VERSION ""

NS_ :

BS_:

BU_:

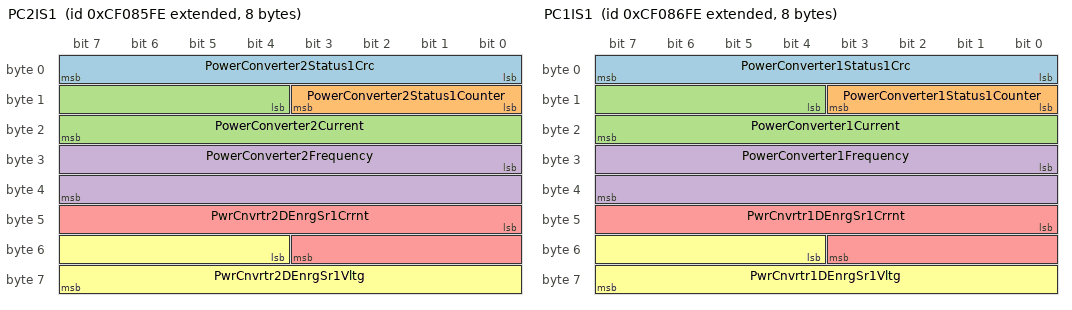
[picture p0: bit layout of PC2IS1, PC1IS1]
BO_ 2364573182 PC2IS1: 8 Vector__XXX
 SG_ PowerConverter2Status1Crc : 0|8@1+ (1,0) [0|250] "count" Vector__XXX
 SG_ PowerConverter2Status1Counter : 8|4@1+ (1,0) [0|15] "" Vector__XXX
 SG_ PowerConverter2Current : 12|12@1+ (0.0625,-125) [-125|125.9375] "%" Vector__XXX
 SG_ PowerConverter2Frequency : 24|16@1+ (0.00390625,-125) [-125|125.99609375] "%" Vector__XXX
 SG_ PwrCnvrtr2DEnrgSr1Crrnt : 40|12@1+ (0.0625,-125) [-125|125.9375] "%" Vector__XXX
 SG_ PwrCnvrtr2DEnrgSr1Vltg : 52|12@1+ (0.0625,-125) [-125|125.9375] "%" Vector__XXX

BO_ 2364573438 PC1IS1: 8 Vector__XXX
 SG_ PowerConverter1Status1Crc : 0|8@1+ (1,0) [0|250] "count" Vector__XXX
 SG_ PowerConverter1Status1Counter : 8|4@1+ (1,0) [0|15] "" Vector__XXX
 SG_ PowerConverter1Current : 12|12@1+ (0.0625,-125) [-125|125.9375] "%" Vector__XXX
 SG_ PowerConverter1Frequency : 24|16@1+ (0.00390625,-125) [-125|125.99609375] "%" Vector__XXX
 SG_ PwrCnvrtr1DEnrgSr1Crrnt : 40|12@1+ (0.0625,-125) [-125|125.9375] "%" Vector__XXX
 SG_ PwrCnvrtr1DEnrgSr1Vltg : 52|12@1+ (0.0625,-125) [-125|125.9375] "%" Vector__XXX

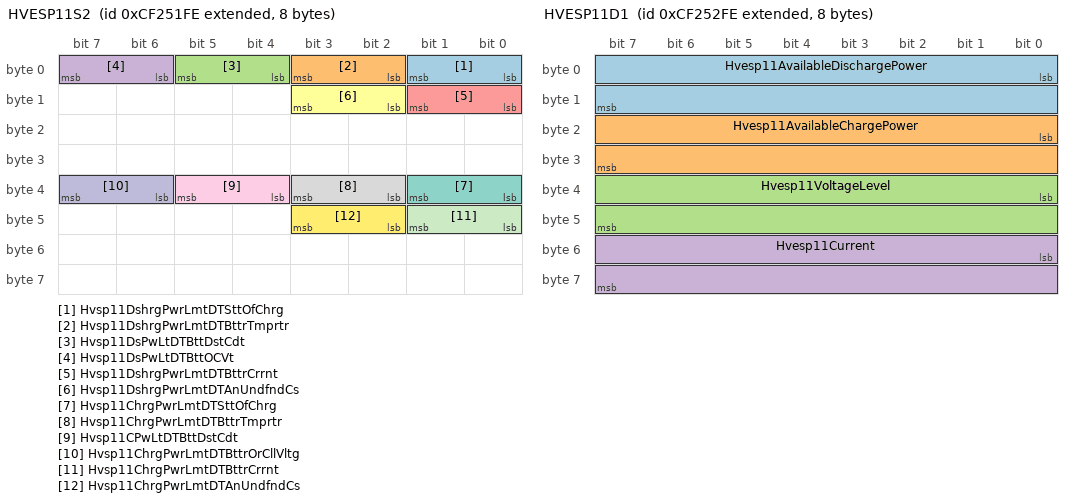
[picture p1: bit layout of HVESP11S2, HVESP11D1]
BO_ 2364690942 HVESP11S2: 8 Vector__XXX
 SG_ Hvsp11DshrgPwrLmtDTSttOfChrg : 0|2@1+ (1,0) [0|3] "" Vector__XXX
 SG_ Hvsp11DshrgPwrLmtDTBttrTmprtr : 2|2@1+ (1,0) [0|3] "" Vector__XXX
 SG_ Hvsp11DsPwLtDTBttDstCdt : 4|2@1+ (1,0) [0|3] "" Vector__XXX
 SG_ Hvsp11DsPwLtDTBttOCVt : 6|2@1+ (1,0) [0|3] "" Vector__XXX
 SG_ Hvsp11DshrgPwrLmtDTBttrCrrnt : 8|2@1+ (1,0) [0|3] "" Vector__XXX
 SG_ Hvsp11DshrgPwrLmtDTAnUndfndCs : 10|2@1+ (1,0) [0|3] "" Vector__XXX
 SG_ Hvsp11ChrgPwrLmtDTSttOfChrg : 32|2@1+ (1,0) [0|3] "" Vector__XXX
 SG_ Hvsp11ChrgPwrLmtDTBttrTmprtr : 34|2@1+ (1,0) [0|3] "" Vector__XXX
 SG_ Hvsp11CPwLtDTBttDstCdt : 36|2@1+ (1,0) [0|3] "" Vector__XXX
 SG_ Hvsp11ChrgPwrLmtDTBttrOrCllVltg : 38|2@1+ (1,0) [0|3] "" Vector__XXX
 SG_ Hvsp11ChrgPwrLmtDTBttrCrrnt : 40|2@1+ (1,0) [0|3] "" Vector__XXX
 SG_ Hvsp11ChrgPwrLmtDTAnUndfndCs : 42|2@1+ (1,0) [0|3] "" Vector__XXX

BO_ 2364691198 HVESP11D1: 8 Vector__XXX
 SG_ Hvesp11AvailableDischargePower : 0|16@1+ (0.05,0) [0|3212.75] "kW" Vector__XXX
 SG_ Hvesp11AvailableChargePower : 16|16@1+ (0.05,0) [0|3212.75] "kW" Vector__XXX
 SG_ Hvesp11VoltageLevel : 32|16@1+ (0.05,0) [0|3212.75] "V" Vector__XXX
 SG_ Hvesp11Current : 48|16@1+ (0.05,-1600) [-1600|1612.75] "A" Vector__XXX

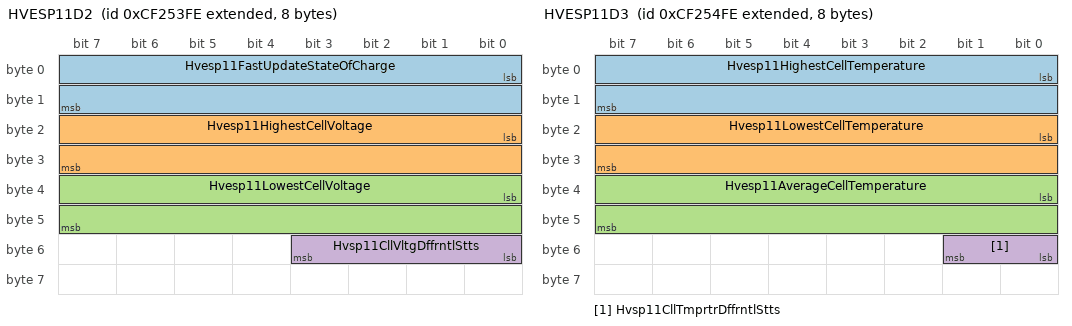
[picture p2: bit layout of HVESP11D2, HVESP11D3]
BO_ 2364691454 HVESP11D2: 8 Vector__XXX
 SG_ Hvesp11FastUpdateStateOfCharge : 0|16@1+ (0.0015625,0) [0|100.3984375] "%" Vector__XXX
 SG_ Hvesp11HighestCellVoltage : 16|16@1+ (0.001,0) [0|64.255] "V" Vector__XXX
 SG_ Hvesp11LowestCellVoltage : 32|16@1+ (0.001,0) [0|64.255] "V" Vector__XXX
 SG_ Hvsp11CllVltgDffrntlStts : 48|4@1+ (1,0) [0|15] "" Vector__XXX

BO_ 2364691710 HVESP11D3: 8 Vector__XXX
 SG_ Hvesp11HighestCellTemperature : 0|16@1+ (0.03125,-273) [-273|1734.96875] "degC" Vector__XXX
 SG_ Hvesp11LowestCellTemperature : 16|16@1+ (0.03125,-273) [-273|1734.96875] "degC" Vector__XXX
 SG_ Hvesp11AverageCellTemperature : 32|16@1+ (0.03125,-273) [-273|1734.96875] "degC" Vector__XXX
 SG_ Hvsp11CllTmprtrDffrntlStts : 48|2@1+ (1,0) [0|3] "" Vector__XXX

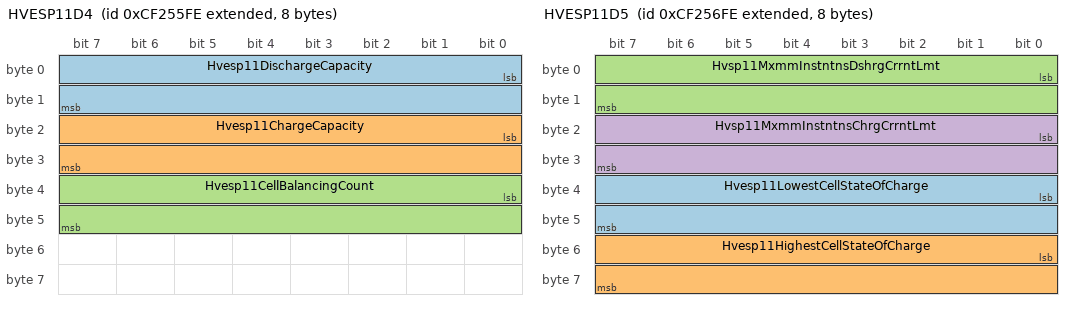
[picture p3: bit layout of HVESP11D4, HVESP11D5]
BO_ 2364691966 HVESP11D4: 8 Vector__XXX
 SG_ Hvesp11DischargeCapacity : 0|16@1+ (0.01,0) [0|642.55] "Ah" Vector__XXX
 SG_ Hvesp11ChargeCapacity : 16|16@1+ (0.01,0) [0|642.55] "Ah" Vector__XXX
 SG_ Hvesp11CellBalancingCount : 32|16@1+ (1,0) [0|64255] "count" Vector__XXX

BO_ 2364692222 HVESP11D5: 8 Vector__XXX
 SG_ Hvesp11LowestCellStateOfCharge : 32|16@1+ (0.0015625,0) [0|100.3984375] "%" Vector__XXX
 SG_ Hvesp11HighestCellStateOfCharge : 48|16@1+ (0.0015625,0) [0|100.3984375] "%" Vector__XXX
 SG_ Hvsp11MxmmInstntnsDshrgCrrntLmt : 0|16@1+ (0.05,-1600) [-1600|0] "A" Vector__XXX
 SG_ Hvsp11MxmmInstntnsChrgCrrntLmt : 16|16@1+ (0.05,-1600) [0|1612.75] "A" Vector__XXX

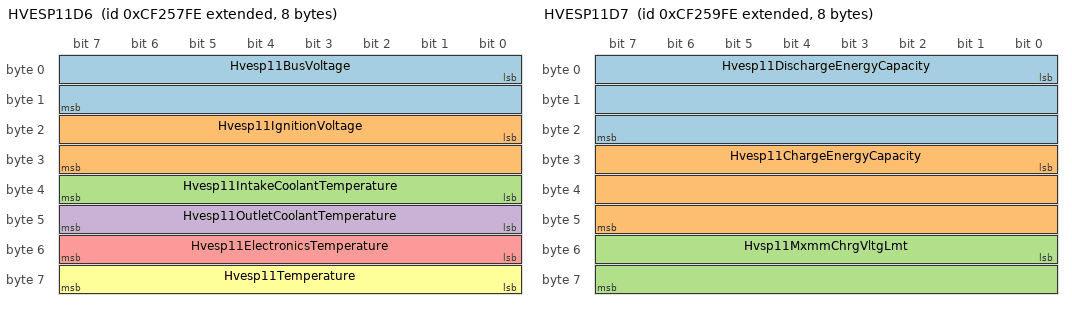
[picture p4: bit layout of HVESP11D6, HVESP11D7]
BO_ 2364692478 HVESP11D6: 8 Vector__XXX
 SG_ Hvesp11BusVoltage : 0|16@1+ (0.05,0) [0|3212.75] "V" Vector__XXX
 SG_ Hvesp11IgnitionVoltage : 16|16@1+ (0.01,0) [0|642.55] "V" Vector__XXX
 SG_ Hvesp11IntakeCoolantTemperature : 32|8@1+ (1,-40) [-40|210] "degC" Vector__XXX
 SG_ Hvesp11OutletCoolantTemperature : 40|8@1+ (1,-40) [-40|210] "degC" Vector__XXX
 SG_ Hvesp11ElectronicsTemperature : 48|8@1+ (1,-40) [-40|210] "degC" Vector__XXX
 SG_ Hvesp11Temperature : 56|8@1+ (1,-40) [-40|210] "degC" Vector__XXX

BO_ 2364692734 HVESP11S1: 8 Vector__XXX
 SG_ Hvsp11HghVltgBsPstvCnttrStt : 0|2@1+ (1,0) [0|3] "" Vector__XXX
 SG_ Hvsp11HghVltgBsNgtvCnttrStt : 2|2@1+ (1,0) [0|3] "" Vector__XXX
 SG_ Hvsp11HghVltgBsDsnntFrwrnng : 4|4@1+ (1,0) [0|15] "" Vector__XXX
 SG_ Hvsp11HghVltgBsPrChrgRlStt : 8|2@1+ (1,0) [0|3] "" Vector__XXX
 SG_ Hvsp11CntrOfPkCnttrStt : 10|2@1+ (1,0) [0|3] "" Vector__XXX
 SG_ Hvsp11HghVltgBsAtvIsltnTstStts : 12|4@1+ (1,0) [0|15] "" Vector__XXX
 SG_ Hvsp11HghVltgBsPssvIsltnTstStts : 16|4@1+ (1,0) [0|15] "" Vector__XXX
 SG_ Hvesp11HvilStatus : 20|2@1+ (1,0) [0|3] "" Vector__XXX
 SG_ Hvesp11InertiaSwitchStatus : 22|2@1+ (1,0) [0|3] "" Vector__XXX
 SG_ Hvesp11StateOfChargeStatus : 24|4@1+ (1,0) [0|15] "" Vector__XXX
 SG_ Hvesp11CellBalanceStatus : 28|2@1+ (1,0) [0|3] "" Vector__XXX
 SG_ Hvesp11CellBalancingActive : 30|2@1+ (1,0) [0|3] "" Vector__XXX
 SG_ Hvesp11InternalChargerStatus : 32|2@1+ (1,0) [0|3] "" Vector__XXX
 SG_ Hvsp11HghVltgBsCnntnStts : 40|4@1+ (1,0) [0|15] "" Vector__XXX
 SG_ Hvesp11OperationalStatus : 44|4@1+ (1,0) [0|15] "" Vector__XXX
 SG_ Hvesp11Status1Counter : 52|4@1+ (1,0) [0|15] "" Vector__XXX
 SG_ Hvesp11Status1Crc : 56|8@1+ (1,0) [0|250] "count" Vector__XXX

BO_ 2364692990 HVESP11D7: 8 Vector__XXX
 SG_ Hvesp11DischargeEnergyCapacity : 0|24@1+ (0.001,0) [0|16449.535] "kWh" Vector__XXX
 SG_ Hvesp11ChargeEnergyCapacity : 24|24@1+ (0.001,0) [0|16449.535] "kWh" Vector__XXX
 SG_ Hvsp11MxmmChrgVltgLmt : 48|16@1+ (0.05,0) [0|3212.75] "V" Vector__XXX

BO_ 2364693246 HVESP11MS1: 8 Vector__XXX
 SG_ Hvesp11Module1OperationalStatus : 0|2@1+ (1,0) [0|3] "" Vector__XXX
 SG_ Hvesp11Module2OperationalStatus : 2|2@1+ (1,0) [0|3] "" Vector__XXX
 SG_ Hvesp11Module3OperationalStatus : 4|2@1+ (1,0) [0|3] "" Vector__XXX
 SG_ Hvesp11Module4OperationalStatus : 6|2@1+ (1,0) [0|3] "" Vector__XXX
 SG_ Hvesp11Module5OperationalStatus : 8|2@1+ (1,0) [0|3] "" Vector__XXX
 SG_ Hvesp11Module6OperationalStatus : 10|2@1+ (1,0) [0|3] "" Vector__XXX
 SG_ Hvesp11Module7OperationalStatus : 12|2@1+ (1,0) [0|3] "" Vector__XXX
 SG_ Hvesp11Module8OperationalStatus : 14|2@1+ (1,0) [0|3] "" Vector__XXX
 SG_ Hvesp11Module9OperationalStatus : 16|2@1+ (1,0) [0|3] "" Vector__XXX
 SG_ Hvsp11Mdl10OprtnlStts : 18|2@1+ (1,0) [0|3] "" Vector__XXX
 SG_ Hvsp11Mdl11OprtnlStts : 20|2@1+ (1,0) [0|3] "" Vector__XXX
 SG_ Hvsp11Mdl12OprtnlStts : 22|2@1+ (1,0) [0|3] "" Vector__XXX
 SG_ Hvsp11Mdl13OprtnlStts : 24|2@1+ (1,0) [0|3] "" Vector__XXX
 SG_ Hvsp11Mdl14OprtnlStts : 26|2@1+ (1,0) [0|3] "" Vector__XXX
 SG_ Hvsp11Mdl15OprtnlStts : 28|2@1+ (1,0) [0|3] "" Vector__XXX
 SG_ Hvsp11Mdl16OprtnlStts : 30|2@1+ (1,0) [0|3] "" Vector__XXX
 SG_ Hvsp11Mdl17OprtnlStts : 32|2@1+ (1,0) [0|3] "" Vector__XXX
 SG_ Hvsp11Mdl18OprtnlStts : 34|2@1+ (1,0) [0|3] "" Vector__XXX
 SG_ Hvsp11Mdl19OprtnlStts : 36|2@1+ (1,0) [0|3] "" Vector__XXX
 SG_ Hvsp11Mdl20OprtnlStts : 38|2@1+ (1,0) [0|3] "" Vector__XXX
 SG_ Hvsp11Mdl21OprtnlStts : 40|2@1+ (1,0) [0|3] "" Vector__XXX
 SG_ Hvsp11Mdl22OprtnlStts : 42|2@1+ (1,0) [0|3] "" Vector__XXX
 SG_ Hvsp11Mdl23OprtnlStts : 44|2@1+ (1,0) [0|3] "" Vector__XXX
 SG_ Hvsp11Mdl24OprtnlStts : 46|2@1+ (1,0) [0|3] "" Vector__XXX
 SG_ Hvsp11Mdl25OprtnlStts : 48|2@1+ (1,0) [0|3] "" Vector__XXX
 SG_ Hvsp11Mdl26OprtnlStts : 50|2@1+ (1,0) [0|3] "" Vector__XXX
 SG_ Hvsp11Mdl27OprtnlStts : 52|2@1+ (1,0) [0|3] "" Vector__XXX
 SG_ Hvsp11Mdl28OprtnlStts : 54|2@1+ (1,0) [0|3] "" Vector__XXX
 SG_ Hvsp11Mdl29OprtnlStts : 56|2@1+ (1,0) [0|3] "" Vector__XXX
 SG_ Hvsp11Mdl30OprtnlStts : 58|2@1+ (1,0) [0|3] "" Vector__XXX
 SG_ Hvsp11Mdl31OprtnlStts : 60|2@1+ (1,0) [0|3] "" Vector__XXX
 SG_ Hvsp11Mdl32OprtnlStts : 62|2@1+ (1,0) [0|3] "" Vector__XXX

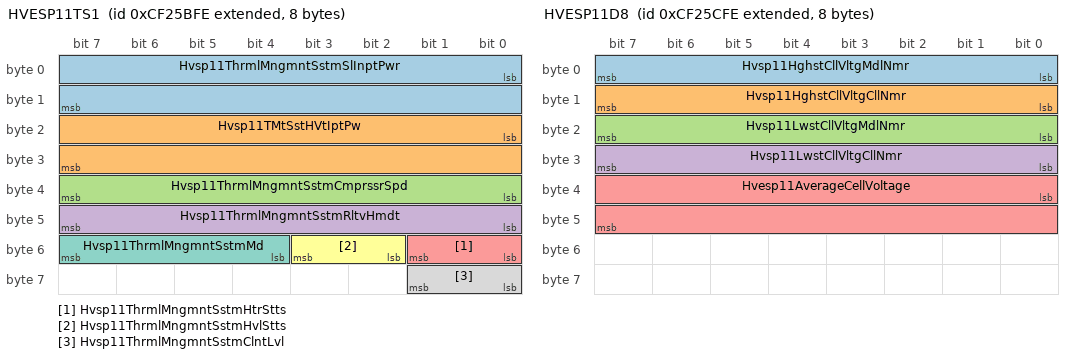
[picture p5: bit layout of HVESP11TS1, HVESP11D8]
BO_ 2364693502 HVESP11TS1: 8 Vector__XXX
 SG_ Hvsp11ThrmlMngmntSstmSlInptPwr : 0|16@1+ (0.5,0) [0|32127.5] "W" Vector__XXX
 SG_ Hvsp11TMtSstHVtIptPw : 16|16@1+ (0.5,0) [0|32127.5] "W" Vector__XXX
 SG_ Hvsp11ThrmlMngmntSstmCmprssrSpd : 32|8@1+ (32,0) [0|8000] "rpm" Vector__XXX
 SG_ Hvsp11ThrmlMngmntSstmRltvHmdt : 40|8@1+ (0.4,0) [0|100] "%" Vector__XXX
 SG_ Hvsp11ThrmlMngmntSstmHtrStts : 48|2@1+ (1,0) [0|3] "" Vector__XXX
 SG_ Hvsp11ThrmlMngmntSstmHvlStts : 50|2@1+ (1,0) [0|3] "" Vector__XXX
 SG_ Hvsp11ThrmlMngmntSstmMd : 52|4@1+ (1,0) [0|15] "" Vector__XXX
 SG_ Hvsp11ThrmlMngmntSstmClntLvl : 56|2@1+ (1,0) [0|3] "" Vector__XXX

BO_ 2364693758 HVESP11D8: 8 Vector__XXX
 SG_ Hvsp11HghstCllVltgMdlNmr : 0|8@1+ (1,0) [0|250] "count" Vector__XXX
 SG_ Hvsp11HghstCllVltgCllNmr : 8|8@1+ (1,0) [0|250] "count" Vector__XXX
 SG_ Hvsp11LwstCllVltgMdlNmr : 16|8@1+ (1,0) [0|250] "count" Vector__XXX
 SG_ Hvsp11LwstCllVltgCllNmr : 24|8@1+ (1,0) [0|250] "count" Vector__XXX
 SG_ Hvesp11AverageCellVoltage : 32|16@1+ (0.001,0) [0|64.255] "V" Vector__XXX

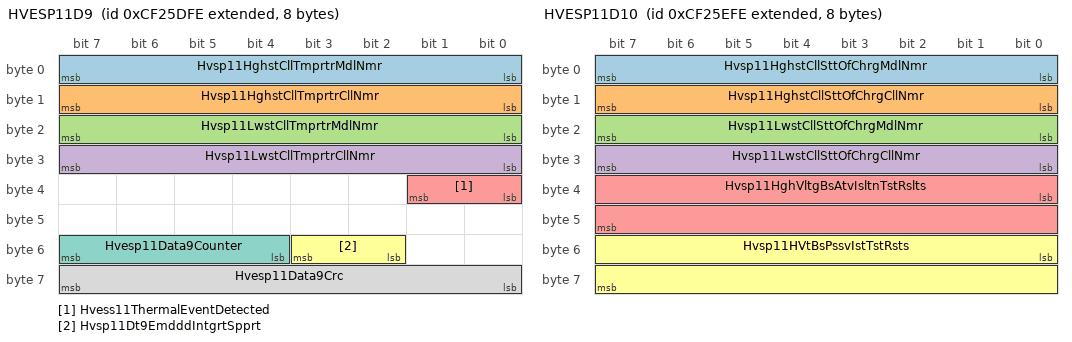
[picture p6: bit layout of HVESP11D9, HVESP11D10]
BO_ 2364694014 HVESP11D9: 8 Vector__XXX
 SG_ Hvsp11HghstCllTmprtrMdlNmr : 0|8@1+ (1,0) [0|250] "count" Vector__XXX
 SG_ Hvsp11HghstCllTmprtrCllNmr : 8|8@1+ (1,0) [0|250] "count" Vector__XXX
 SG_ Hvsp11LwstCllTmprtrMdlNmr : 16|8@1+ (1,0) [0|250] "count" Vector__XXX
 SG_ Hvsp11LwstCllTmprtrCllNmr : 24|8@1+ (1,0) [0|250] "count" Vector__XXX
 SG_ Hvess11ThermalEventDetected : 32|2@1+ (1,0) [0|3] "" Vector__XXX
 SG_ Hvsp11Dt9EmdddIntgrtSpprt : 50|2@1+ (1,0) [0|3] "" Vector__XXX
 SG_ Hvesp11Data9Counter : 52|4@1+ (1,0) [0|15] "" Vector__XXX
 SG_ Hvesp11Data9Crc : 56|8@1+ (1,0) [0|250] "count" Vector__XXX

BO_ 2364694270 HVESP11D10: 8 Vector__XXX
 SG_ Hvsp11HghstCllSttOfChrgMdlNmr : 0|8@1+ (1,0) [0|250] "count" Vector__XXX
 SG_ Hvsp11HghstCllSttOfChrgCllNmr : 8|8@1+ (1,0) [0|250] "count" Vector__XXX
 SG_ Hvsp11LwstCllSttOfChrgMdlNmr : 16|8@1+ (1,0) [0|250] "count" Vector__XXX
 SG_ Hvsp11LwstCllSttOfChrgCllNmr : 24|8@1+ (1,0) [0|250] "count" Vector__XXX
 SG_ Hvsp11HghVltgBsAtvIsltnTstRslts : 32|16@1+ (0.1,0) [0|6425.5] "OhmPerV" Vector__XXX
 SG_ Hvsp11HVtBsPssvIstTstRsts : 48|16@1+ (0.1,0) [0|6425.5] "OhmPerV" Vector__XXX

BO_ 2364694526 HVESP11D11: 8 Vector__XXX
 SG_ Hvsp11BsVltgNgtvTChsssGrndVltg : 0|16@1+ (0.05,0) [0|3212.75] "V" Vector__XXX
 SG_ Hvsp11VltgLvlNgtvTChsssGrndVltg : 16|16@1+ (0.05,0) [0|3212.75] "V" Vector__XXX
 SG_ Hvesp11ActualChargeRate : 32|16@1+ (0.05,0) [0|3212.75] "kW" Vector__XXX

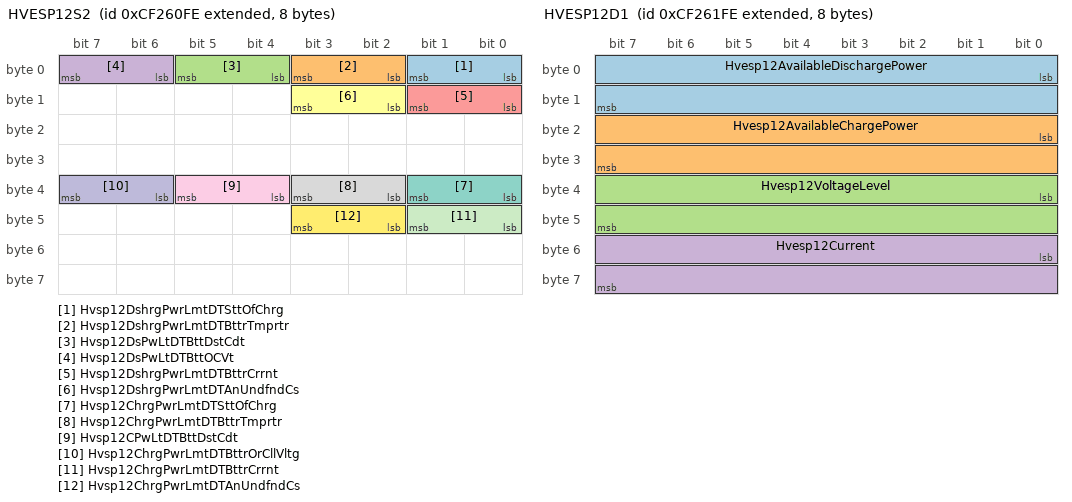
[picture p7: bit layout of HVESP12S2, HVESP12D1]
BO_ 2364694782 HVESP12S2: 8 Vector__XXX
 SG_ Hvsp12DshrgPwrLmtDTSttOfChrg : 0|2@1+ (1,0) [0|3] "" Vector__XXX
 SG_ Hvsp12DshrgPwrLmtDTBttrTmprtr : 2|2@1+ (1,0) [0|3] "" Vector__XXX
 SG_ Hvsp12DsPwLtDTBttDstCdt : 4|2@1+ (1,0) [0|3] "" Vector__XXX
 SG_ Hvsp12DsPwLtDTBttOCVt : 6|2@1+ (1,0) [0|3] "" Vector__XXX
 SG_ Hvsp12DshrgPwrLmtDTBttrCrrnt : 8|2@1+ (1,0) [0|3] "" Vector__XXX
 SG_ Hvsp12DshrgPwrLmtDTAnUndfndCs : 10|2@1+ (1,0) [0|3] "" Vector__XXX
 SG_ Hvsp12ChrgPwrLmtDTSttOfChrg : 32|2@1+ (1,0) [0|3] "" Vector__XXX
 SG_ Hvsp12ChrgPwrLmtDTBttrTmprtr : 34|2@1+ (1,0) [0|3] "" Vector__XXX
 SG_ Hvsp12CPwLtDTBttDstCdt : 36|2@1+ (1,0) [0|3] "" Vector__XXX
 SG_ Hvsp12ChrgPwrLmtDTBttrOrCllVltg : 38|2@1+ (1,0) [0|3] "" Vector__XXX
 SG_ Hvsp12ChrgPwrLmtDTBttrCrrnt : 40|2@1+ (1,0) [0|3] "" Vector__XXX
 SG_ Hvsp12ChrgPwrLmtDTAnUndfndCs : 42|2@1+ (1,0) [0|3] "" Vector__XXX

BO_ 2364695038 HVESP12D1: 8 Vector__XXX
 SG_ Hvesp12AvailableDischargePower : 0|16@1+ (0.05,0) [0|3212.75] "kW" Vector__XXX
 SG_ Hvesp12AvailableChargePower : 16|16@1+ (0.05,0) [0|3212.75] "kW" Vector__XXX
 SG_ Hvesp12VoltageLevel : 32|16@1+ (0.05,0) [0|3212.75] "V" Vector__XXX
 SG_ Hvesp12Current : 48|16@1+ (0.05,-1600) [-1600|1612.75] "A" Vector__XXX

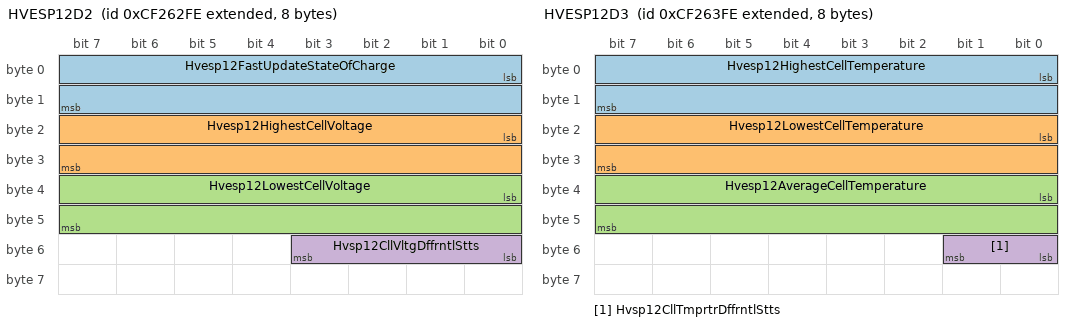
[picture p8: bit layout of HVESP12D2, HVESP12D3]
BO_ 2364695294 HVESP12D2: 8 Vector__XXX
 SG_ Hvesp12FastUpdateStateOfCharge : 0|16@1+ (0.0015625,0) [0|100.3984375] "%" Vector__XXX
 SG_ Hvesp12HighestCellVoltage : 16|16@1+ (0.001,0) [0|64.255] "V" Vector__XXX
 SG_ Hvesp12LowestCellVoltage : 32|16@1+ (0.001,0) [0|64.255] "V" Vector__XXX
 SG_ Hvsp12CllVltgDffrntlStts : 48|4@1+ (1,0) [0|15] "" Vector__XXX

BO_ 2364695550 HVESP12D3: 8 Vector__XXX
 SG_ Hvesp12HighestCellTemperature : 0|16@1+ (0.03125,-273) [-273|1734.96875] "degC" Vector__XXX
 SG_ Hvesp12LowestCellTemperature : 16|16@1+ (0.03125,-273) [-273|1734.96875] "degC" Vector__XXX
 SG_ Hvesp12AverageCellTemperature : 32|16@1+ (0.03125,-273) [-273|1734.96875] "degC" Vector__XXX
 SG_ Hvsp12CllTmprtrDffrntlStts : 48|2@1+ (1,0) [0|3] "" Vector__XXX

BO_ 2364695806 HVESP12D4: 8 Vector__XXX
 SG_ Hvesp12DischargeCapacity : 0|16@1+ (0.01,0) [0|642.55] "Ah" Vector__XXX
 SG_ Hvesp12ChargeCapacity : 16|16@1+ (0.01,0) [0|642.55] "Ah" Vector__XXX
 SG_ Hvesp12CellBalancingCount : 32|16@1+ (1,0) [0|64255] "count" Vector__XXX

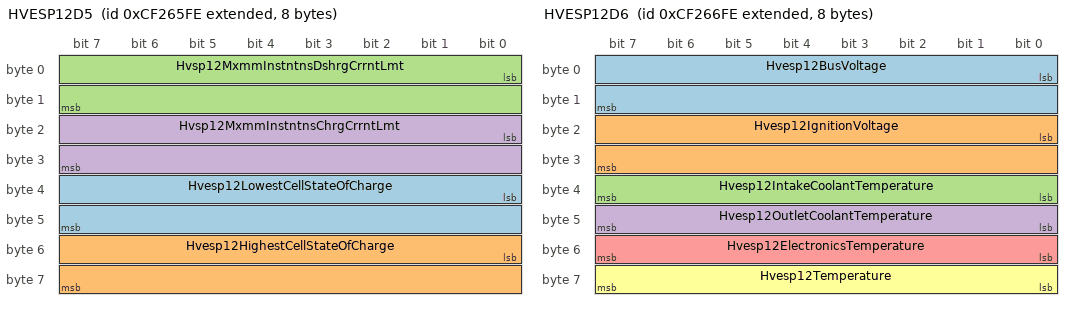
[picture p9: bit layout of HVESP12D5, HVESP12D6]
BO_ 2364696062 HVESP12D5: 8 Vector__XXX
 SG_ Hvesp12LowestCellStateOfCharge : 32|16@1+ (0.0015625,0) [0|100.3984375] "%" Vector__XXX
 SG_ Hvesp12HighestCellStateOfCharge : 48|16@1+ (0.0015625,0) [0|100.3984375] "%" Vector__XXX
 SG_ Hvsp12MxmmInstntnsDshrgCrrntLmt : 0|16@1+ (0.05,-1600) [-1600|0] "A" Vector__XXX
 SG_ Hvsp12MxmmInstntnsChrgCrrntLmt : 16|16@1+ (0.05,-1600) [0|1612.75] "A" Vector__XXX

BO_ 2364696318 HVESP12D6: 8 Vector__XXX
 SG_ Hvesp12BusVoltage : 0|16@1+ (0.05,0) [0|3212.75] "V" Vector__XXX
 SG_ Hvesp12IgnitionVoltage : 16|16@1+ (0.01,0) [0|642.55] "V" Vector__XXX
 SG_ Hvesp12IntakeCoolantTemperature : 32|8@1+ (1,-40) [-40|210] "degC" Vector__XXX
 SG_ Hvesp12OutletCoolantTemperature : 40|8@1+ (1,-40) [-40|210] "degC" Vector__XXX
 SG_ Hvesp12ElectronicsTemperature : 48|8@1+ (1,-40) [-40|210] "degC" Vector__XXX
 SG_ Hvesp12Temperature : 56|8@1+ (1,-40) [-40|210] "degC" Vector__XXX

BO_ 2364696574 HVESP12S1: 8 Vector__XXX
 SG_ Hvsp12HghVltgBsPstvCnttrStt : 0|2@1+ (1,0) [0|3] "" Vector__XXX
 SG_ Hvsp12HghVltgBsNgtvCnttrStt : 2|2@1+ (1,0) [0|3] "" Vector__XXX
 SG_ Hvsp12HghVltgBsDsnntFrwrnng : 4|4@1+ (1,0) [0|15] "" Vector__XXX
 SG_ Hvsp12HghVltgBsPrChrgRlStt : 8|2@1+ (1,0) [0|3] "" Vector__XXX
 SG_ Hvsp12CntrOfPkCnttrStt : 10|2@1+ (1,0) [0|3] "" Vector__XXX
 SG_ Hvsp12HghVltgBsAtvIsltnTstStts : 12|4@1+ (1,0) [0|15] "" Vector__XXX
 SG_ Hvsp12HghVltgBsPssvIsltnTstStts : 16|4@1+ (1,0) [0|15] "" Vector__XXX
 SG_ Hvesp12HvilStatus : 20|2@1+ (1,0) [0|3] "" Vector__XXX
 SG_ Hvesp12InertiaSwitchStatus : 22|2@1+ (1,0) [0|3] "" Vector__XXX
 SG_ Hvesp12StateOfChargeStatus : 24|4@1+ (1,0) [0|15] "" Vector__XXX
 SG_ Hvesp12CellBalanceStatus : 28|2@1+ (1,0) [0|3] "" Vector__XXX
 SG_ Hvesp12CellBalancingActive : 30|2@1+ (1,0) [0|3] "" Vector__XXX
 SG_ Hvesp12InternalChargerStatus : 32|2@1+ (1,0) [0|3] "" Vector__XXX
 SG_ Hvsp12HghVltgBsCnntnStts : 40|4@1+ (1,0) [0|15] "" Vector__XXX
 SG_ Hvesp12OperationalStatus : 44|4@1+ (1,0) [0|15] "" Vector__XXX
 SG_ Hvesp12Status1Counter : 52|4@1+ (1,0) [0|15] "" Vector__XXX
 SG_ Hvesp12Status1Crc : 56|8@1+ (1,0) [0|250] "count" Vector__XXX

BO_ 2364696830 HVESP12D7: 8 Vector__XXX
 SG_ Hvesp12DischargeEnergyCapacity : 0|24@1+ (0.001,0) [0|16449.535] "kWh" Vector__XXX
 SG_ Hvesp12ChargeEnergyCapacity : 24|24@1+ (0.001,0) [0|16449.535] "kWh" Vector__XXX
 SG_ Hvsp12MxmmChrgVltgLmt : 48|16@1+ (0.05,0) [0|3212.75] "V" Vector__XXX

BO_ 2364697086 HVESP12MS1: 8 Vector__XXX
 SG_ Hvesp12Module1OperationalStatus : 0|2@1+ (1,0) [0|3] "" Vector__XXX
 SG_ Hvesp12Module2OperationalStatus : 2|2@1+ (1,0) [0|3] "" Vector__XXX
 SG_ Hvesp12Module3OperationalStatus : 4|2@1+ (1,0) [0|3] "" Vector__XXX
 SG_ Hvesp12Module4OperationalStatus : 6|2@1+ (1,0) [0|3] "" Vector__XXX
 SG_ Hvesp12Module5OperationalStatus : 8|2@1+ (1,0) [0|3] "" Vector__XXX
 SG_ Hvesp12Module6OperationalStatus : 10|2@1+ (1,0) [0|3] "" Vector__XXX
 SG_ Hvesp12Module7OperationalStatus : 12|2@1+ (1,0) [0|3] "" Vector__XXX
 SG_ Hvesp12Module8OperationalStatus : 14|2@1+ (1,0) [0|3] "" Vector__XXX
 SG_ Hvesp12Module9OperationalStatus : 16|2@1+ (1,0) [0|3] "" Vector__XXX
 SG_ Hvsp12Mdl10OprtnlStts : 18|2@1+ (1,0) [0|3] "" Vector__XXX
 SG_ Hvsp12Mdl11OprtnlStts : 20|2@1+ (1,0) [0|3] "" Vector__XXX
 SG_ Hvsp12Mdl12OprtnlStts : 22|2@1+ (1,0) [0|3] "" Vector__XXX
 SG_ Hvsp12Mdl13OprtnlStts : 24|2@1+ (1,0) [0|3] "" Vector__XXX
 SG_ Hvsp12Mdl14OprtnlStts : 26|2@1+ (1,0) [0|3] "" Vector__XXX
 SG_ Hvsp12Mdl15OprtnlStts : 28|2@1+ (1,0) [0|3] "" Vector__XXX
 SG_ Hvsp12Mdl16OprtnlStts : 30|2@1+ (1,0) [0|3] "" Vector__XXX
 SG_ Hvsp12Mdl17OprtnlStts : 32|2@1+ (1,0) [0|3] "" Vector__XXX
 SG_ Hvsp12Mdl18OprtnlStts : 34|2@1+ (1,0) [0|3] "" Vector__XXX
 SG_ Hvsp12Mdl19OprtnlStts : 36|2@1+ (1,0) [0|3] "" Vector__XXX
 SG_ Hvsp12Mdl20OprtnlStts : 38|2@1+ (1,0) [0|3] "" Vector__XXX
 SG_ Hvsp12Mdl21OprtnlStts : 40|2@1+ (1,0) [0|3] "" Vector__XXX
 SG_ Hvsp12Mdl22OprtnlStts : 42|2@1+ (1,0) [0|3] "" Vector__XXX
 SG_ Hvsp12Mdl23OprtnlStts : 44|2@1+ (1,0) [0|3] "" Vector__XXX
 SG_ Hvsp12Mdl24OprtnlStts : 46|2@1+ (1,0) [0|3] "" Vector__XXX
 SG_ Hvsp12Mdl25OprtnlStts : 48|2@1+ (1,0) [0|3] "" Vector__XXX
 SG_ Hvsp12Mdl26OprtnlStts : 50|2@1+ (1,0) [0|3] "" Vector__XXX
 SG_ Hvsp12Mdl27OprtnlStts : 52|2@1+ (1,0) [0|3] "" Vector__XXX
 SG_ Hvsp12Mdl28OprtnlStts : 54|2@1+ (1,0) [0|3] "" Vector__XXX
 SG_ Hvsp12Mdl29OprtnlStts : 56|2@1+ (1,0) [0|3] "" Vector__XXX
 SG_ Hvsp12Mdl30OprtnlStts : 58|2@1+ (1,0) [0|3] "" Vector__XXX
 SG_ Hvsp12Mdl31OprtnlStts : 60|2@1+ (1,0) [0|3] "" Vector__XXX
 SG_ Hvsp12Mdl32OprtnlStts : 62|2@1+ (1,0) [0|3] "" Vector__XXX

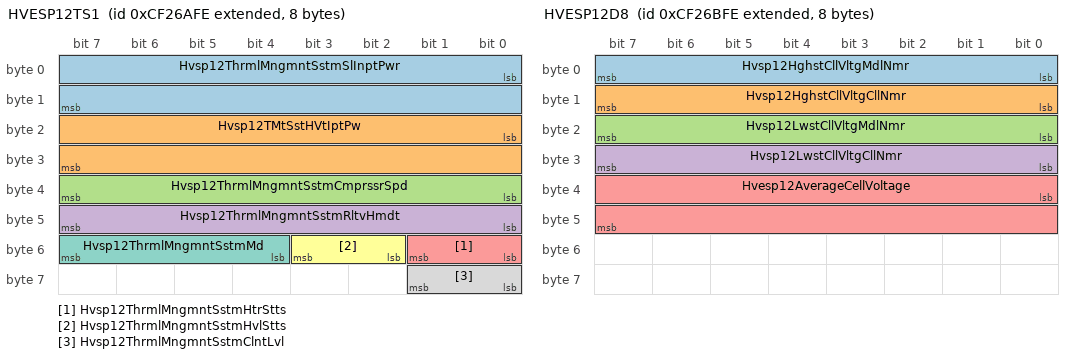
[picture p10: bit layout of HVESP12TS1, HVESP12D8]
BO_ 2364697342 HVESP12TS1: 8 Vector__XXX
 SG_ Hvsp12ThrmlMngmntSstmSlInptPwr : 0|16@1+ (0.5,0) [0|32127.5] "W" Vector__XXX
 SG_ Hvsp12TMtSstHVtIptPw : 16|16@1+ (0.5,0) [0|32127.5] "W" Vector__XXX
 SG_ Hvsp12ThrmlMngmntSstmCmprssrSpd : 32|8@1+ (32,0) [0|8000] "rpm" Vector__XXX
 SG_ Hvsp12ThrmlMngmntSstmRltvHmdt : 40|8@1+ (0.4,0) [0|100] "%" Vector__XXX
 SG_ Hvsp12ThrmlMngmntSstmHtrStts : 48|2@1+ (1,0) [0|3] "" Vector__XXX
 SG_ Hvsp12ThrmlMngmntSstmHvlStts : 50|2@1+ (1,0) [0|3] "" Vector__XXX
 SG_ Hvsp12ThrmlMngmntSstmMd : 52|4@1+ (1,0) [0|15] "" Vector__XXX
 SG_ Hvsp12ThrmlMngmntSstmClntLvl : 56|2@1+ (1,0) [0|3] "" Vector__XXX

BO_ 2364697598 HVESP12D8: 8 Vector__XXX
 SG_ Hvsp12HghstCllVltgMdlNmr : 0|8@1+ (1,0) [0|250] "count" Vector__XXX
 SG_ Hvsp12HghstCllVltgCllNmr : 8|8@1+ (1,0) [0|250] "count" Vector__XXX
 SG_ Hvsp12LwstCllVltgMdlNmr : 16|8@1+ (1,0) [0|250] "count" Vector__XXX
 SG_ Hvsp12LwstCllVltgCllNmr : 24|8@1+ (1,0) [0|250] "count" Vector__XXX
 SG_ Hvesp12AverageCellVoltage : 32|16@1+ (0.001,0) [0|64.255] "V" Vector__XXX

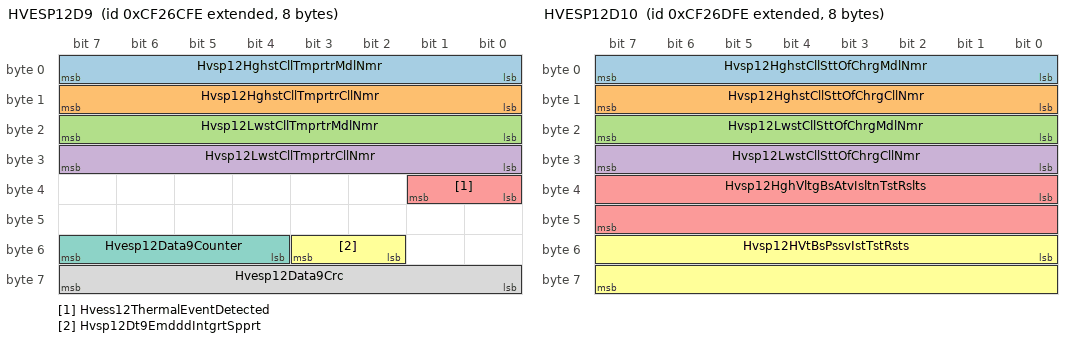
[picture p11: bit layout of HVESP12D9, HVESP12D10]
BO_ 2364697854 HVESP12D9: 8 Vector__XXX
 SG_ Hvsp12HghstCllTmprtrMdlNmr : 0|8@1+ (1,0) [0|250] "count" Vector__XXX
 SG_ Hvsp12HghstCllTmprtrCllNmr : 8|8@1+ (1,0) [0|250] "count" Vector__XXX
 SG_ Hvsp12LwstCllTmprtrMdlNmr : 16|8@1+ (1,0) [0|250] "count" Vector__XXX
 SG_ Hvsp12LwstCllTmprtrCllNmr : 24|8@1+ (1,0) [0|250] "count" Vector__XXX
 SG_ Hvess12ThermalEventDetected : 32|2@1+ (1,0) [0|3] "" Vector__XXX
 SG_ Hvsp12Dt9EmdddIntgrtSpprt : 50|2@1+ (1,0) [0|3] "" Vector__XXX
 SG_ Hvesp12Data9Counter : 52|4@1+ (1,0) [0|15] "" Vector__XXX
 SG_ Hvesp12Data9Crc : 56|8@1+ (1,0) [0|250] "count" Vector__XXX

BO_ 2364698110 HVESP12D10: 8 Vector__XXX
 SG_ Hvsp12HghstCllSttOfChrgMdlNmr : 0|8@1+ (1,0) [0|250] "count" Vector__XXX
 SG_ Hvsp12HghstCllSttOfChrgCllNmr : 8|8@1+ (1,0) [0|250] "count" Vector__XXX
 SG_ Hvsp12LwstCllSttOfChrgMdlNmr : 16|8@1+ (1,0) [0|250] "count" Vector__XXX
 SG_ Hvsp12LwstCllSttOfChrgCllNmr : 24|8@1+ (1,0) [0|250] "count" Vector__XXX
 SG_ Hvsp12HghVltgBsAtvIsltnTstRslts : 32|16@1+ (0.1,0) [0|6425.5] "OhmPerV" Vector__XXX
 SG_ Hvsp12HVtBsPssvIstTstRsts : 48|16@1+ (0.1,0) [0|6425.5] "OhmPerV" Vector__XXX

BO_ 2364698366 HVESP12D11: 8 Vector__XXX
 SG_ Hvsp12BsVltgNgtvTChsssGrndVltg : 0|16@1+ (0.05,0) [0|3212.75] "V" Vector__XXX
 SG_ Hvsp12VltgLvlNgtvTChsssGrndVltg : 16|16@1+ (0.05,0) [0|3212.75] "V" Vector__XXX
 SG_ Hvesp12ActualChargeRate : 32|16@1+ (0.05,0) [0|3212.75] "kW" Vector__XXX

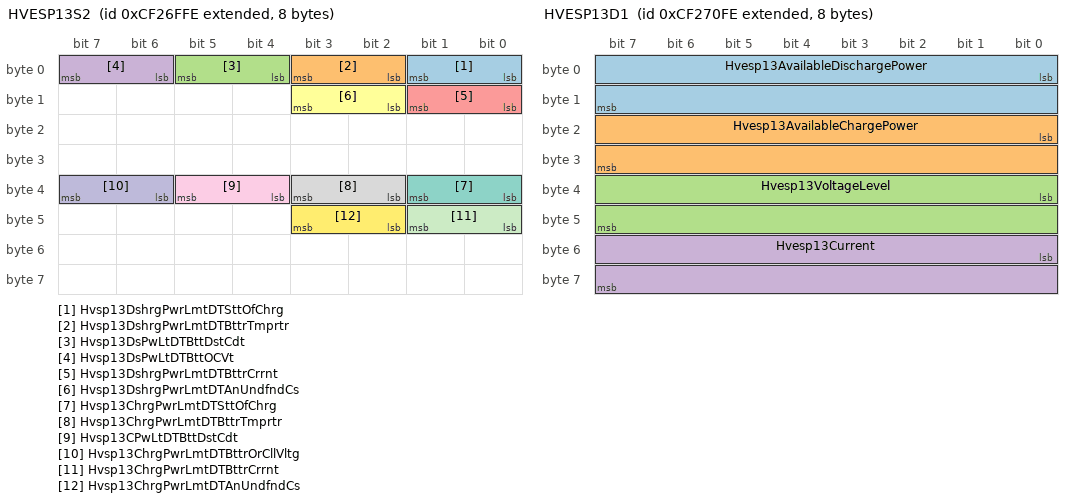
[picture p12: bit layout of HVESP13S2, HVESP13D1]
BO_ 2364698622 HVESP13S2: 8 Vector__XXX
 SG_ Hvsp13DshrgPwrLmtDTSttOfChrg : 0|2@1+ (1,0) [0|3] "" Vector__XXX
 SG_ Hvsp13DshrgPwrLmtDTBttrTmprtr : 2|2@1+ (1,0) [0|3] "" Vector__XXX
 SG_ Hvsp13DsPwLtDTBttDstCdt : 4|2@1+ (1,0) [0|3] "" Vector__XXX
 SG_ Hvsp13DsPwLtDTBttOCVt : 6|2@1+ (1,0) [0|3] "" Vector__XXX
 SG_ Hvsp13DshrgPwrLmtDTBttrCrrnt : 8|2@1+ (1,0) [0|3] "" Vector__XXX
 SG_ Hvsp13DshrgPwrLmtDTAnUndfndCs : 10|2@1+ (1,0) [0|3] "" Vector__XXX
 SG_ Hvsp13ChrgPwrLmtDTSttOfChrg : 32|2@1+ (1,0) [0|3] "" Vector__XXX
 SG_ Hvsp13ChrgPwrLmtDTBttrTmprtr : 34|2@1+ (1,0) [0|3] "" Vector__XXX
 SG_ Hvsp13CPwLtDTBttDstCdt : 36|2@1+ (1,0) [0|3] "" Vector__XXX
 SG_ Hvsp13ChrgPwrLmtDTBttrOrCllVltg : 38|2@1+ (1,0) [0|3] "" Vector__XXX
 SG_ Hvsp13ChrgPwrLmtDTBttrCrrnt : 40|2@1+ (1,0) [0|3] "" Vector__XXX
 SG_ Hvsp13ChrgPwrLmtDTAnUndfndCs : 42|2@1+ (1,0) [0|3] "" Vector__XXX

BO_ 2364698878 HVESP13D1: 8 Vector__XXX
 SG_ Hvesp13AvailableDischargePower : 0|16@1+ (0.05,0) [0|3212.75] "kW" Vector__XXX
 SG_ Hvesp13AvailableChargePower : 16|16@1+ (0.05,0) [0|3212.75] "kW" Vector__XXX
 SG_ Hvesp13VoltageLevel : 32|16@1+ (0.05,0) [0|3212.75] "V" Vector__XXX
 SG_ Hvesp13Current : 48|16@1+ (0.05,-1600) [-1600|1612.75] "A" Vector__XXX

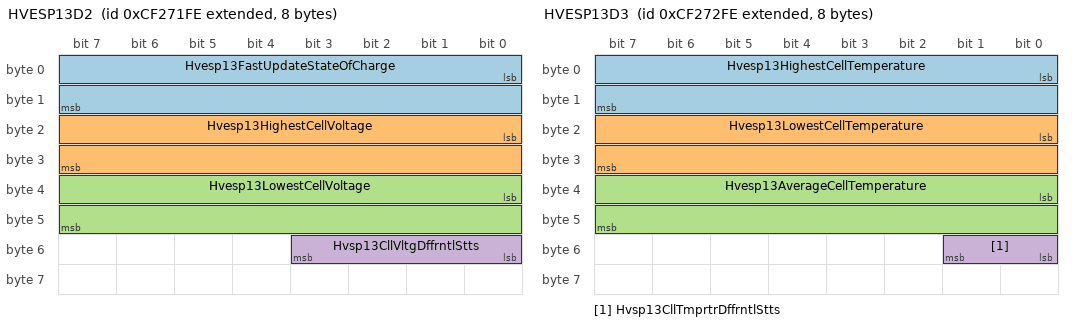
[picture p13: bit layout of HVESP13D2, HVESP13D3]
BO_ 2364699134 HVESP13D2: 8 Vector__XXX
 SG_ Hvesp13FastUpdateStateOfCharge : 0|16@1+ (0.0015625,0) [0|100.3984375] "%" Vector__XXX
 SG_ Hvesp13HighestCellVoltage : 16|16@1+ (0.001,0) [0|64.255] "V" Vector__XXX
 SG_ Hvesp13LowestCellVoltage : 32|16@1+ (0.001,0) [0|64.255] "V" Vector__XXX
 SG_ Hvsp13CllVltgDffrntlStts : 48|4@1+ (1,0) [0|15] "" Vector__XXX

BO_ 2364699390 HVESP13D3: 8 Vector__XXX
 SG_ Hvesp13HighestCellTemperature : 0|16@1+ (0.03125,-273) [-273|1734.96875] "degC" Vector__XXX
 SG_ Hvesp13LowestCellTemperature : 16|16@1+ (0.03125,-273) [-273|1734.96875] "degC" Vector__XXX
 SG_ Hvesp13AverageCellTemperature : 32|16@1+ (0.03125,-273) [-273|1734.96875] "degC" Vector__XXX
 SG_ Hvsp13CllTmprtrDffrntlStts : 48|2@1+ (1,0) [0|3] "" Vector__XXX

BO_ 2364699646 HVESP13D4: 8 Vector__XXX
 SG_ Hvesp13DischargeCapacity : 0|16@1+ (0.01,0) [0|642.55] "Ah" Vector__XXX
 SG_ Hvesp13ChargeCapacity : 16|16@1+ (0.01,0) [0|642.55] "Ah" Vector__XXX
 SG_ Hvesp13CellBalancingCount : 32|16@1+ (1,0) [0|64255] "count" Vector__XXX

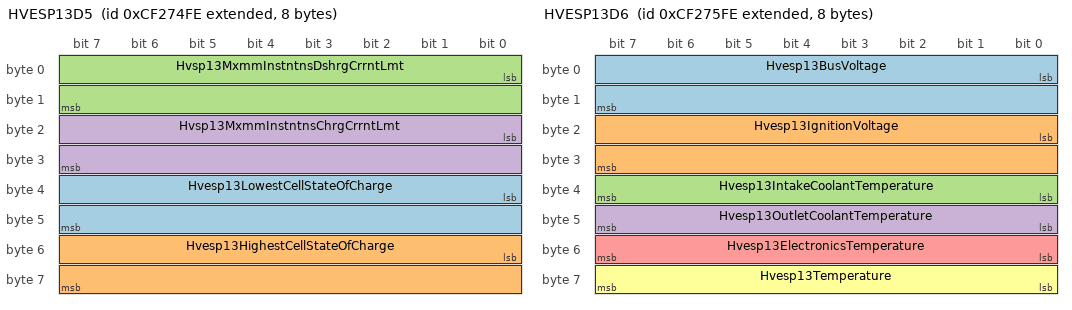
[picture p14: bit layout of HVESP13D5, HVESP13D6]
BO_ 2364699902 HVESP13D5: 8 Vector__XXX
 SG_ Hvesp13LowestCellStateOfCharge : 32|16@1+ (0.0015625,0) [0|100.3984375] "%" Vector__XXX
 SG_ Hvesp13HighestCellStateOfCharge : 48|16@1+ (0.0015625,0) [0|100.3984375] "%" Vector__XXX
 SG_ Hvsp13MxmmInstntnsDshrgCrrntLmt : 0|16@1+ (0.05,-1600) [-1600|0] "A" Vector__XXX
 SG_ Hvsp13MxmmInstntnsChrgCrrntLmt : 16|16@1+ (0.05,-1600) [0|1612.75] "A" Vector__XXX

BO_ 2364700158 HVESP13D6: 8 Vector__XXX
 SG_ Hvesp13BusVoltage : 0|16@1+ (0.05,0) [0|3212.75] "V" Vector__XXX
 SG_ Hvesp13IgnitionVoltage : 16|16@1+ (0.01,0) [0|642.55] "V" Vector__XXX
 SG_ Hvesp13IntakeCoolantTemperature : 32|8@1+ (1,-40) [-40|210] "degC" Vector__XXX
 SG_ Hvesp13OutletCoolantTemperature : 40|8@1+ (1,-40) [-40|210] "degC" Vector__XXX
 SG_ Hvesp13ElectronicsTemperature : 48|8@1+ (1,-40) [-40|210] "degC" Vector__XXX
 SG_ Hvesp13Temperature : 56|8@1+ (1,-40) [-40|210] "degC" Vector__XXX

BO_ 2364700414 HVESP13S1: 8 Vector__XXX
 SG_ Hvsp13HghVltgBsPstvCnttrStt : 0|2@1+ (1,0) [0|3] "" Vector__XXX
 SG_ Hvsp13HghVltgBsNgtvCnttrStt : 2|2@1+ (1,0) [0|3] "" Vector__XXX
 SG_ Hvsp13HghVltgBsDsnntFrwrnng : 4|4@1+ (1,0) [0|15] "" Vector__XXX
 SG_ Hvsp13HghVltgBsPrChrgRlStt : 8|2@1+ (1,0) [0|3] "" Vector__XXX
 SG_ Hvsp13CntrOfPkCnttrStt : 10|2@1+ (1,0) [0|3] "" Vector__XXX
 SG_ Hvsp13HghVltgBsAtvIsltnTstStts : 12|4@1+ (1,0) [0|15] "" Vector__XXX
 SG_ Hvsp13HghVltgBsPssvIsltnTstStts : 16|4@1+ (1,0) [0|15] "" Vector__XXX
 SG_ Hvesp13HvilStatus : 20|2@1+ (1,0) [0|3] "" Vector__XXX
 SG_ Hvesp13InertiaSwitchStatus : 22|2@1+ (1,0) [0|3] "" Vector__XXX
 SG_ Hvesp13StateOfChargeStatus : 24|4@1+ (1,0) [0|15] "" Vector__XXX
 SG_ Hvesp13CellBalanceStatus : 28|2@1+ (1,0) [0|3] "" Vector__XXX
 SG_ Hvesp13CellBalancingActive : 30|2@1+ (1,0) [0|3] "" Vector__XXX
 SG_ Hvesp13InternalChargerStatus : 32|2@1+ (1,0) [0|3] "" Vector__XXX
 SG_ Hvsp13HghVltgBsCnntnStts : 40|4@1+ (1,0) [0|15] "" Vector__XXX
 SG_ Hvesp13OperationalStatus : 44|4@1+ (1,0) [0|15] "" Vector__XXX
 SG_ Hvesp13Status1Counter : 52|4@1+ (1,0) [0|15] "" Vector__XXX
 SG_ Hvesp13Status1Crc : 56|8@1+ (1,0) [0|250] "count" Vector__XXX

BO_ 2364700670 HVESP13D7: 8 Vector__XXX
 SG_ Hvesp13DischargeEnergyCapacity : 0|24@1+ (0.001,0) [0|16449.535] "kWh" Vector__XXX
 SG_ Hvesp13ChargeEnergyCapacity : 24|24@1+ (0.001,0) [0|16449.535] "kWh" Vector__XXX
 SG_ Hvsp13MxmmChrgVltgLmt : 48|16@1+ (0.05,0) [0|3212.75] "V" Vector__XXX

BO_ 2364700926 HVESP13MS1: 8 Vector__XXX
 SG_ Hvesp13Module1OperationalStatus : 0|2@1+ (1,0) [0|3] "" Vector__XXX
 SG_ Hvesp13Module2OperationalStatus : 2|2@1+ (1,0) [0|3] "" Vector__XXX
 SG_ Hvesp13Module3OperationalStatus : 4|2@1+ (1,0) [0|3] "" Vector__XXX
 SG_ Hvesp13Module4OperationalStatus : 6|2@1+ (1,0) [0|3] "" Vector__XXX
 SG_ Hvesp13Module5OperationalStatus : 8|2@1+ (1,0) [0|3] "" Vector__XXX
 SG_ Hvesp13Module6OperationalStatus : 10|2@1+ (1,0) [0|3] "" Vector__XXX
 SG_ Hvesp13Module7OperationalStatus : 12|2@1+ (1,0) [0|3] "" Vector__XXX
 SG_ Hvesp13Module8OperationalStatus : 14|2@1+ (1,0) [0|3] "" Vector__XXX
 SG_ Hvesp13Module9OperationalStatus : 16|2@1+ (1,0) [0|3] "" Vector__XXX
 SG_ Hvsp13Mdl10OprtnlStts : 18|2@1+ (1,0) [0|3] "" Vector__XXX
 SG_ Hvsp13Mdl11OprtnlStts : 20|2@1+ (1,0) [0|3] "" Vector__XXX
 SG_ Hvsp13Mdl12OprtnlStts : 22|2@1+ (1,0) [0|3] "" Vector__XXX
 SG_ Hvsp13Mdl13OprtnlStts : 24|2@1+ (1,0) [0|3] "" Vector__XXX
 SG_ Hvsp13Mdl14OprtnlStts : 26|2@1+ (1,0) [0|3] "" Vector__XXX
 SG_ Hvsp13Mdl15OprtnlStts : 28|2@1+ (1,0) [0|3] "" Vector__XXX
 SG_ Hvsp13Mdl16OprtnlStts : 30|2@1+ (1,0) [0|3] "" Vector__XXX
 SG_ Hvsp13Mdl17OprtnlStts : 32|2@1+ (1,0) [0|3] "" Vector__XXX
 SG_ Hvsp13Mdl18OprtnlStts : 34|2@1+ (1,0) [0|3] "" Vector__XXX
 SG_ Hvsp13Mdl19OprtnlStts : 36|2@1+ (1,0) [0|3] "" Vector__XXX
 SG_ Hvsp13Mdl20OprtnlStts : 38|2@1+ (1,0) [0|3] "" Vector__XXX
 SG_ Hvsp13Mdl21OprtnlStts : 40|2@1+ (1,0) [0|3] "" Vector__XXX
 SG_ Hvsp13Mdl22OprtnlStts : 42|2@1+ (1,0) [0|3] "" Vector__XXX
 SG_ Hvsp13Mdl23OprtnlStts : 44|2@1+ (1,0) [0|3] "" Vector__XXX
 SG_ Hvsp13Mdl24OprtnlStts : 46|2@1+ (1,0) [0|3] "" Vector__XXX
 SG_ Hvsp13Mdl25OprtnlStts : 48|2@1+ (1,0) [0|3] "" Vector__XXX
 SG_ Hvsp13Mdl26OprtnlStts : 50|2@1+ (1,0) [0|3] "" Vector__XXX
 SG_ Hvsp13Mdl27OprtnlStts : 52|2@1+ (1,0) [0|3] "" Vector__XXX
 SG_ Hvsp13Mdl28OprtnlStts : 54|2@1+ (1,0) [0|3] "" Vector__XXX
 SG_ Hvsp13Mdl29OprtnlStts : 56|2@1+ (1,0) [0|3] "" Vector__XXX
 SG_ Hvsp13Mdl30OprtnlStts : 58|2@1+ (1,0) [0|3] "" Vector__XXX
 SG_ Hvsp13Mdl31OprtnlStts : 60|2@1+ (1,0) [0|3] "" Vector__XXX
 SG_ Hvsp13Mdl32OprtnlStts : 62|2@1+ (1,0) [0|3] "" Vector__XXX

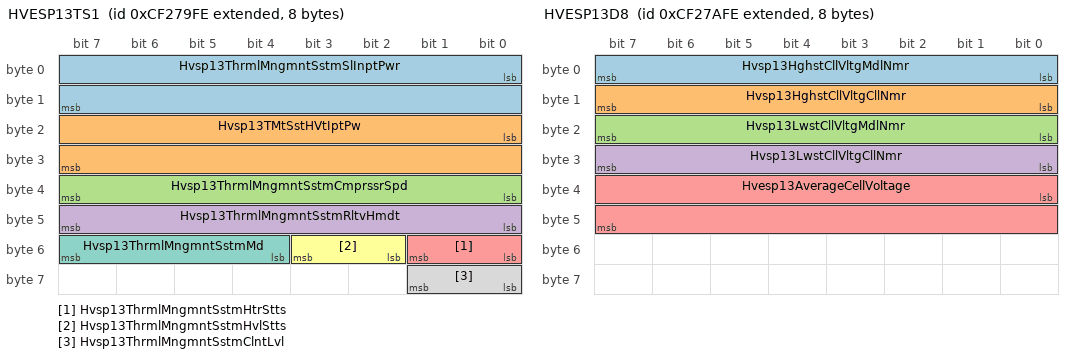
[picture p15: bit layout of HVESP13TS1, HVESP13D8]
BO_ 2364701182 HVESP13TS1: 8 Vector__XXX
 SG_ Hvsp13ThrmlMngmntSstmSlInptPwr : 0|16@1+ (0.5,0) [0|32127.5] "W" Vector__XXX
 SG_ Hvsp13TMtSstHVtIptPw : 16|16@1+ (0.5,0) [0|32127.5] "W" Vector__XXX
 SG_ Hvsp13ThrmlMngmntSstmCmprssrSpd : 32|8@1+ (32,0) [0|8000] "rpm" Vector__XXX
 SG_ Hvsp13ThrmlMngmntSstmRltvHmdt : 40|8@1+ (0.4,0) [0|100] "%" Vector__XXX
 SG_ Hvsp13ThrmlMngmntSstmHtrStts : 48|2@1+ (1,0) [0|3] "" Vector__XXX
 SG_ Hvsp13ThrmlMngmntSstmHvlStts : 50|2@1+ (1,0) [0|3] "" Vector__XXX
 SG_ Hvsp13ThrmlMngmntSstmMd : 52|4@1+ (1,0) [0|15] "" Vector__XXX
 SG_ Hvsp13ThrmlMngmntSstmClntLvl : 56|2@1+ (1,0) [0|3] "" Vector__XXX

BO_ 2364701438 HVESP13D8: 8 Vector__XXX
 SG_ Hvsp13HghstCllVltgMdlNmr : 0|8@1+ (1,0) [0|250] "count" Vector__XXX
 SG_ Hvsp13HghstCllVltgCllNmr : 8|8@1+ (1,0) [0|250] "count" Vector__XXX
 SG_ Hvsp13LwstCllVltgMdlNmr : 16|8@1+ (1,0) [0|250] "count" Vector__XXX
 SG_ Hvsp13LwstCllVltgCllNmr : 24|8@1+ (1,0) [0|250] "count" Vector__XXX
 SG_ Hvesp13AverageCellVoltage : 32|16@1+ (0.001,0) [0|64.255] "V" Vector__XXX

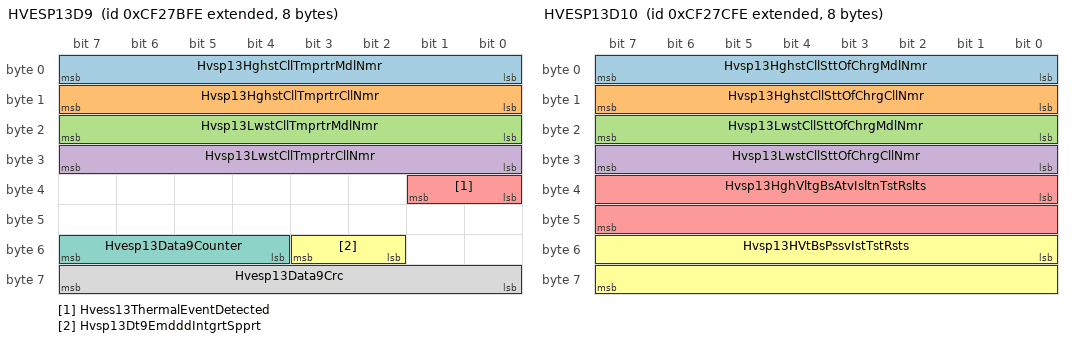
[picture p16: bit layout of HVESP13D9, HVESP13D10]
BO_ 2364701694 HVESP13D9: 8 Vector__XXX
 SG_ Hvsp13HghstCllTmprtrMdlNmr : 0|8@1+ (1,0) [0|250] "count" Vector__XXX
 SG_ Hvsp13HghstCllTmprtrCllNmr : 8|8@1+ (1,0) [0|250] "count" Vector__XXX
 SG_ Hvsp13LwstCllTmprtrMdlNmr : 16|8@1+ (1,0) [0|250] "count" Vector__XXX
 SG_ Hvsp13LwstCllTmprtrCllNmr : 24|8@1+ (1,0) [0|250] "count" Vector__XXX
 SG_ Hvess13ThermalEventDetected : 32|2@1+ (1,0) [0|3] "" Vector__XXX
 SG_ Hvsp13Dt9EmdddIntgrtSpprt : 50|2@1+ (1,0) [0|3] "" Vector__XXX
 SG_ Hvesp13Data9Counter : 52|4@1+ (1,0) [0|15] "" Vector__XXX
 SG_ Hvesp13Data9Crc : 56|8@1+ (1,0) [0|250] "count" Vector__XXX

BO_ 2364701950 HVESP13D10: 8 Vector__XXX
 SG_ Hvsp13HghstCllSttOfChrgMdlNmr : 0|8@1+ (1,0) [0|250] "count" Vector__XXX
 SG_ Hvsp13HghstCllSttOfChrgCllNmr : 8|8@1+ (1,0) [0|250] "count" Vector__XXX
 SG_ Hvsp13LwstCllSttOfChrgMdlNmr : 16|8@1+ (1,0) [0|250] "count" Vector__XXX
 SG_ Hvsp13LwstCllSttOfChrgCllNmr : 24|8@1+ (1,0) [0|250] "count" Vector__XXX
 SG_ Hvsp13HghVltgBsAtvIsltnTstRslts : 32|16@1+ (0.1,0) [0|6425.5] "OhmPerV" Vector__XXX
 SG_ Hvsp13HVtBsPssvIstTstRsts : 48|16@1+ (0.1,0) [0|6425.5] "OhmPerV" Vector__XXX

BO_ 2364702206 HVESP13D11: 8 Vector__XXX
 SG_ Hvsp13BsVltgNgtvTChsssGrndVltg : 0|16@1+ (0.05,0) [0|3212.75] "V" Vector__XXX
 SG_ Hvsp13VltgLvlNgtvTChsssGrndVltg : 16|16@1+ (0.05,0) [0|3212.75] "V" Vector__XXX
 SG_ Hvesp13ActualChargeRate : 32|16@1+ (0.05,0) [0|3212.75] "kW" Vector__XXX

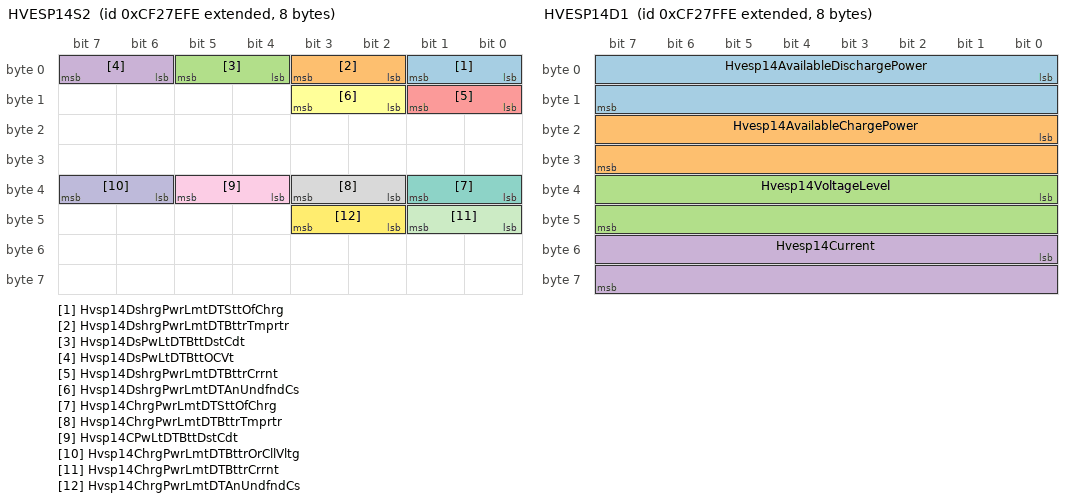
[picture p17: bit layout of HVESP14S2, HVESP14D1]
BO_ 2364702462 HVESP14S2: 8 Vector__XXX
 SG_ Hvsp14DshrgPwrLmtDTSttOfChrg : 0|2@1+ (1,0) [0|3] "" Vector__XXX
 SG_ Hvsp14DshrgPwrLmtDTBttrTmprtr : 2|2@1+ (1,0) [0|3] "" Vector__XXX
 SG_ Hvsp14DsPwLtDTBttDstCdt : 4|2@1+ (1,0) [0|3] "" Vector__XXX
 SG_ Hvsp14DsPwLtDTBttOCVt : 6|2@1+ (1,0) [0|3] "" Vector__XXX
 SG_ Hvsp14DshrgPwrLmtDTBttrCrrnt : 8|2@1+ (1,0) [0|3] "" Vector__XXX
 SG_ Hvsp14DshrgPwrLmtDTAnUndfndCs : 10|2@1+ (1,0) [0|3] "" Vector__XXX
 SG_ Hvsp14ChrgPwrLmtDTSttOfChrg : 32|2@1+ (1,0) [0|3] "" Vector__XXX
 SG_ Hvsp14ChrgPwrLmtDTBttrTmprtr : 34|2@1+ (1,0) [0|3] "" Vector__XXX
 SG_ Hvsp14CPwLtDTBttDstCdt : 36|2@1+ (1,0) [0|3] "" Vector__XXX
 SG_ Hvsp14ChrgPwrLmtDTBttrOrCllVltg : 38|2@1+ (1,0) [0|3] "" Vector__XXX
 SG_ Hvsp14ChrgPwrLmtDTBttrCrrnt : 40|2@1+ (1,0) [0|3] "" Vector__XXX
 SG_ Hvsp14ChrgPwrLmtDTAnUndfndCs : 42|2@1+ (1,0) [0|3] "" Vector__XXX

BO_ 2364702718 HVESP14D1: 8 Vector__XXX
 SG_ Hvesp14AvailableDischargePower : 0|16@1+ (0.05,0) [0|3212.75] "kW" Vector__XXX
 SG_ Hvesp14AvailableChargePower : 16|16@1+ (0.05,0) [0|3212.75] "kW" Vector__XXX
 SG_ Hvesp14VoltageLevel : 32|16@1+ (0.05,0) [0|3212.75] "V" Vector__XXX
 SG_ Hvesp14Current : 48|16@1+ (0.05,-1600) [-1600|1612.75] "A" Vector__XXX

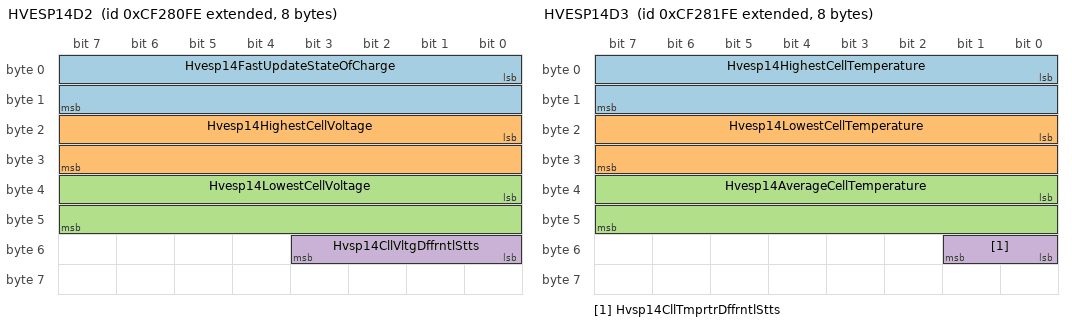
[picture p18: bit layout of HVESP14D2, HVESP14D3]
BO_ 2364702974 HVESP14D2: 8 Vector__XXX
 SG_ Hvesp14FastUpdateStateOfCharge : 0|16@1+ (0.0015625,0) [0|100.3984375] "%" Vector__XXX
 SG_ Hvesp14HighestCellVoltage : 16|16@1+ (0.001,0) [0|64.255] "V" Vector__XXX
 SG_ Hvesp14LowestCellVoltage : 32|16@1+ (0.001,0) [0|64.255] "V" Vector__XXX
 SG_ Hvsp14CllVltgDffrntlStts : 48|4@1+ (1,0) [0|15] "" Vector__XXX

BO_ 2364703230 HVESP14D3: 8 Vector__XXX
 SG_ Hvesp14HighestCellTemperature : 0|16@1+ (0.03125,-273) [-273|1734.96875] "degC" Vector__XXX
 SG_ Hvesp14LowestCellTemperature : 16|16@1+ (0.03125,-273) [-273|1734.96875] "degC" Vector__XXX
 SG_ Hvesp14AverageCellTemperature : 32|16@1+ (0.03125,-273) [-273|1734.96875] "degC" Vector__XXX
 SG_ Hvsp14CllTmprtrDffrntlStts : 48|2@1+ (1,0) [0|3] "" Vector__XXX

BO_ 2364703486 HVESP14D4: 8 Vector__XXX
 SG_ Hvesp14DischargeCapacity : 0|16@1+ (0.01,0) [0|642.55] "Ah" Vector__XXX
 SG_ Hvesp14ChargeCapacity : 16|16@1+ (0.01,0) [0|642.55] "Ah" Vector__XXX
 SG_ Hvesp14CellBalancingCount : 32|16@1+ (1,0) [0|64255] "count" Vector__XXX

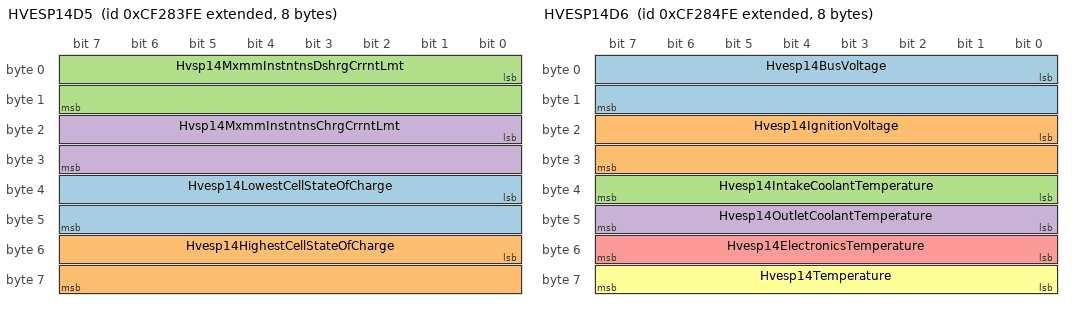
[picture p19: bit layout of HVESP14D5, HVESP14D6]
BO_ 2364703742 HVESP14D5: 8 Vector__XXX
 SG_ Hvesp14LowestCellStateOfCharge : 32|16@1+ (0.0015625,0) [0|100.3984375] "%" Vector__XXX
 SG_ Hvesp14HighestCellStateOfCharge : 48|16@1+ (0.0015625,0) [0|100.3984375] "%" Vector__XXX
 SG_ Hvsp14MxmmInstntnsDshrgCrrntLmt : 0|16@1+ (0.05,-1600) [-1600|0] "A" Vector__XXX
 SG_ Hvsp14MxmmInstntnsChrgCrrntLmt : 16|16@1+ (0.05,-1600) [0|1612.75] "A" Vector__XXX

BO_ 2364703998 HVESP14D6: 8 Vector__XXX
 SG_ Hvesp14BusVoltage : 0|16@1+ (0.05,0) [0|3212.75] "V" Vector__XXX
 SG_ Hvesp14IgnitionVoltage : 16|16@1+ (0.01,0) [0|642.55] "V" Vector__XXX
 SG_ Hvesp14IntakeCoolantTemperature : 32|8@1+ (1,-40) [-40|210] "degC" Vector__XXX
 SG_ Hvesp14OutletCoolantTemperature : 40|8@1+ (1,-40) [-40|210] "degC" Vector__XXX
 SG_ Hvesp14ElectronicsTemperature : 48|8@1+ (1,-40) [-40|210] "degC" Vector__XXX
 SG_ Hvesp14Temperature : 56|8@1+ (1,-40) [-40|210] "degC" Vector__XXX

BO_ 2364704254 HVESP14S1: 8 Vector__XXX
 SG_ Hvsp14HghVltgBsPstvCnttrStt : 0|2@1+ (1,0) [0|3] "" Vector__XXX
 SG_ Hvsp14HghVltgBsNgtvCnttrStt : 2|2@1+ (1,0) [0|3] "" Vector__XXX
 SG_ Hvsp14HghVltgBsDsnntFrwrnng : 4|4@1+ (1,0) [0|15] "" Vector__XXX
 SG_ Hvsp14HghVltgBsPrChrgRlStt : 8|2@1+ (1,0) [0|3] "" Vector__XXX
 SG_ Hvsp14CntrOfPkCnttrStt : 10|2@1+ (1,0) [0|3] "" Vector__XXX
 SG_ Hvsp14HghVltgBsAtvIsltnTstStts : 12|4@1+ (1,0) [0|15] "" Vector__XXX
 SG_ Hvsp14HghVltgBsPssvIsltnTstStts : 16|4@1+ (1,0) [0|15] "" Vector__XXX
 SG_ Hvesp14HvilStatus : 20|2@1+ (1,0) [0|3] "" Vector__XXX
 SG_ Hvesp14InertiaSwitchStatus : 22|2@1+ (1,0) [0|3] "" Vector__XXX
 SG_ Hvesp14StateOfChargeStatus : 24|4@1+ (1,0) [0|15] "" Vector__XXX
 SG_ Hvesp14CellBalanceStatus : 28|2@1+ (1,0) [0|3] "" Vector__XXX
 SG_ Hvesp14CellBalancingActive : 30|2@1+ (1,0) [0|3] "" Vector__XXX
 SG_ Hvesp14InternalChargerStatus : 32|2@1+ (1,0) [0|3] "" Vector__XXX
 SG_ Hvsp14HghVltgBsCnntnStts : 40|4@1+ (1,0) [0|15] "" Vector__XXX
 SG_ Hvesp14OperationalStatus : 44|4@1+ (1,0) [0|15] "" Vector__XXX
 SG_ Hvesp14Status1Counter : 52|4@1+ (1,0) [0|15] "" Vector__XXX
 SG_ Hvesp14Status1Crc : 56|8@1+ (1,0) [0|250] "count" Vector__XXX

BO_ 2364704510 HVESP14D7: 8 Vector__XXX
 SG_ Hvesp14DischargeEnergyCapacity : 0|24@1+ (0.001,0) [0|16449.535] "kWh" Vector__XXX
 SG_ Hvesp14ChargeEnergyCapacity : 24|24@1+ (0.001,0) [0|16449.535] "kWh" Vector__XXX
 SG_ Hvsp14MxmmChrgVltgLmt : 48|16@1+ (0.05,0) [0|3212.75] "V" Vector__XXX

CM_ BO_ 2364573182 "Power Converter 2 Status 1";
CM_ SG_ 2364573182 PowerConverter2Status1Crc "Power Converter 2 Status 1 CRC: The CRC is defined as follows: - Length: 8 bits- Polynomial: x^8+x^5+x^3+x^2+x+1- Initial Value: FFh- Input Data Reflection: Not reflected- Result Data Reflection: Not reflected- XOR value: FFh SAE makes no claim of th...";
CM_ SG_ 2364573182 PowerConverter2Status1Counter "Power Converter 2 Status 1 Counter: The message counter is used to detect situations where the transmitting ECU malfunction repeats the same frame all the time. The receiver of the information may use the counter parameter to detect this situation. T...";
CM_ SG_ 2364573182 PowerConverter2Current "Power Converter 2 Current: The measured or estimated system current.  This refers to the system rotor output and excludes any gearbox that may be attached to the system.  Refer to SPN 20667 (Power Converter 2 Reference Current) to convert % to A.The ...";
CM_ SG_ 2364573182 PowerConverter2Frequency "Power Converter 2 Frequency: The measured or estimated system frequency.  This refers to the system rotor output and excludes any gearbox that may be attached to the system.   Refer to SPN 20668 (Power Converter 2 Reference Frequency) to convert % to...";
CM_ SG_ 2364573182 PwrCnvrtr2DEnrgSr1Crrnt "Power Converter 2 DC Energy Source 1 Current: This is the DC Energy Source 1 current of the Power Converter.Refer to SPN 20667 (Power Converter 2 Reference Current) to convert % to Amps.While systeming, the current is defined as positive.  For exampl...";
CM_ SG_ 2364573182 PwrCnvrtr2DEnrgSr1Vltg "Power Converter 2 DC Energy Source 1 Voltage: The measured or estimated DC Energy Source 1 voltage.  Refer to SPN 20679 (Power Converter 2 Reference Voltage) to convert % to Volts.";
CM_ BO_ 2364573438 "Power Converter 1 Status 1";
CM_ SG_ 2364573438 PowerConverter1Status1Crc "Power Converter 1 Status 1 CRC: The CRC is defined as follows: - Length: 8 bits- Polynomial: x^8+x^5+x^3+x^2+x+1- Initial Value: FFh- Input Data Reflection: Not reflected- Result Data Reflection: Not reflected- XOR value: FFh SAE makes no claim of th...";
CM_ SG_ 2364573438 PowerConverter1Status1Counter "Power Converter 1 Status 1 Counter: The message counter is used to detect situations where the transmitting ECU malfunction repeats the same frame all the time. The receiver of the information may use the counter parameter to detect this situation. T...";
CM_ SG_ 2364573438 PowerConverter1Current "Power Converter 1 Current: The measured or estimated system current.  This refers to the system rotor output and excludes any gearbox that may be attached to the system.Refer to SPN 20690 (Power Converter 1 Reference Current) to convert % to A.The sy...";
CM_ SG_ 2364573438 PowerConverter1Frequency "Power Converter 1 Frequency: The measured or estimated system frequency.  This refers to the system rotor output and excludes any gearbox that may be attached to the system.   Refer to SPN 20701 (Power Converter 1 Reference Frequency) to convert % to...";
CM_ SG_ 2364573438 PwrCnvrtr1DEnrgSr1Crrnt "Power Converter 1 DC Energy Source 1 Current: This is the DC Energy Source 1 current of the Power Converter.Refer to SPN 20690 (Power Converter 1 Reference Current) to convert % to Amps.While systeming, the current is defined as positive.  For exampl...";
CM_ SG_ 2364573438 PwrCnvrtr1DEnrgSr1Vltg "Power Converter 1 DC Energy Source 1 Voltage: The measured or estimated DC Energy Source 1 voltage.  Refer to SPN 20691 (Power Converter 1 Reference Voltage) to convert % to Volts.";
CM_ BO_ 2364690942 "High Voltage Energy Storage Pack 11 Status 2";
CM_ SG_ 2364690942 Hvsp11DshrgPwrLmtDTSttOfChrg "HVESP11 Discharge Power Limit Due to State of Charge: Indicates whether or not discharge power of this HVES instance is being limited due to state of charge.This parameter is for one of multiple packs in an HVESS.  If there is only one pack in the sy...";
CM_ SG_ 2364690942 Hvsp11DshrgPwrLmtDTBttrTmprtr "HVESP11 Discharge Power Limit Due to Battery Temperature: Indicates whether or not discharge power of this HVES instance is being limited due to battery temperature.This parameter is for one of multiple packs in an HVESS.  If there is only one pack i...";
CM_ SG_ 2364690942 Hvsp11DsPwLtDTBttDstCdt "HVESP11 Discharge Power Limit Due to Battery Diagnostic Condition: Indicates whether or not discharge power of this HVES instance is being limited due to a battery diagnostic condition.This parameter is for one of multiple packs in an HVESS.  If ther...";
CM_ SG_ 2364690942 Hvsp11DsPwLtDTBttOCVt "HVESP11 Discharge Power Limit Due to Battery or Cell Voltage: Indicates whether or not discharge power of this HVES instance is being limited due to a battery or cell voltage level.This parameter is for one of multiple packs in an HVESS.  If there is...";
CM_ SG_ 2364690942 Hvsp11DshrgPwrLmtDTBttrCrrnt "HVESP11 Discharge Power Limit Due to Battery Current: Indicates whether or not discharge power of this HVES instance is being limited due to battery current.This parameter is for one of multiple packs in an HVESS.  If there is only one pack in the sy...";
CM_ SG_ 2364690942 Hvsp11DshrgPwrLmtDTAnUndfndCs "HVESP11 Discharge Power Limit Due to an Undefined Cause: Indicates whether or not discharge power of this HVES instance is being limited due to an undefined cause.This parameter is for one of multiple packs in an HVESS.  If there is only one pack in ...";
CM_ SG_ 2364690942 Hvsp11ChrgPwrLmtDTSttOfChrg "HVESP11 Charge Power Limit Due to State of Charge: Indicates whether or not charge power of this HVES instance is being limited due to state of charge.This parameter is for one of multiple packs in an HVESS.  If there is only one pack in the system, ...";
CM_ SG_ 2364690942 Hvsp11ChrgPwrLmtDTBttrTmprtr "HVESP11 Charge Power Limit Due to Battery Temperature: Indicates whether or not charge power of this HVES instance is being limited due to battery temperature.This parameter is for one of multiple packs in an HVESS.  If there is only one pack in the ...";
CM_ SG_ 2364690942 Hvsp11CPwLtDTBttDstCdt "HVESP11 Charge Power Limit Due to Battery Diagnostic Condition: Indicates whether or not charge power of this HVES instance is being limited due to a battery diagnostic condition.This parameter is for one of multiple packs in an HVESS.  If there is o...";
CM_ SG_ 2364690942 Hvsp11ChrgPwrLmtDTBttrOrCllVltg "HVESP11 Charge Power Limit Due to Battery or Cell Voltage: Indicates whether or not charge power of this HVES instance is being limited due to a battery or cell voltage level.This parameter is for one of multiple packs in an HVESS.  If there is only ...";
CM_ SG_ 2364690942 Hvsp11ChrgPwrLmtDTBttrCrrnt "HVESP11 Charge Power Limit Due to Battery Current: Indicates whether or not charge power of this HVES instance is being limited due to battery current.This parameter is for one of multiple packs in an HVESS.  If there is only one pack in the system, ...";
CM_ SG_ 2364690942 Hvsp11ChrgPwrLmtDTAnUndfndCs "HVESP11 Charge Power Limit Due to an Undefined Cause: Indicates whether or not charge power of this HVES instance is being limited due to an undefined cause.This parameter is for one of multiple packs in an HVESS.  If there is only one pack in the sy...";
CM_ BO_ 2364691198 "High Voltage Energy Storage Pack 11 Data 1";
CM_ SG_ 2364691198 Hvesp11AvailableDischargePower "HVESP11 Available Discharge Power: The rate at which this High Voltage Energy Storage Pack instance can currently provide energy for propulsion or other uses.This parameter is for one of multiple packs in an HVESS.  If there is only one pack in the s...";
CM_ SG_ 2364691198 Hvesp11AvailableChargePower "HVESP11 Available Charge Power: The rate at which this High Voltage Energy Storage Pack instance can currently receive energy from a regenerative or recharging system.This parameter is for one of multiple packs in an HVESS.  If there is only one pack...";
CM_ SG_ 2364691198 Hvesp11VoltageLevel "HVESP11 Voltage Level: The voltage level of this High Voltage Energy Storage Pack instance. This parameter should be synchronized with SPN 15295 (HVESP11 Current) such that a realized power value can be calculated. If the HVES component physically co...";
CM_ SG_ 2364691198 Hvesp11Current "HVESP11 Current: The current in or out of this High Voltage Energy Storage Pack instance. This parameter should be synchronized with SPN 15294 (HVESP11 Voltage Level) such that a realized power value can be calculated. This parameter is defined from ...";
CM_ BO_ 2364691454 "High Voltage Energy Storage Pack 11 Data 2";
CM_ SG_ 2364691454 Hvesp11FastUpdateStateOfCharge "HVESP11 Fast Update State of Charge: Indicates this High Voltage Energy Storage Pack instance state of charge. 0% means no charge remaining, 100% means the system is fully charged in terms of physical limits of this energy storage pack instance. Acce...";
CM_ SG_ 2364691454 Hvesp11HighestCellVoltage "HVESP11 Highest Cell Voltage: The highest voltage level reported by any cell in this High Voltage Energy Storage Pack instance. If a single voltage sensor covers more than one cell, the value in this parameter is for the smallest group of cells measu...";
CM_ SG_ 2364691454 Hvesp11LowestCellVoltage "HVESP11 Lowest Cell Voltage: The lowest voltage level reported by any cell in this High Voltage Energy Storage Pack instance. If a single voltage sensor covers more than one cell, the value in this parameter is for the smallest group of cells measure...";
CM_ SG_ 2364691454 Hvsp11CllVltgDffrntlStts "HVESP11 Cell Voltage Differential Status: Indicates whether or not the differential between the highest and lowest cell voltages are within acceptable limits, according to this High Voltage Energy Storage Pack instance. The actual voltage differentia...";
CM_ BO_ 2364691710 "High Voltage Energy Storage Pack 11 Data 3";
CM_ SG_ 2364691710 Hvesp11HighestCellTemperature "HVESP11 Highest Cell Temperature: The highest temperature level reported by any cell in this High Voltage Energy Storage Pack instance. If a single temperature sensor covers more than one cell, the value in this parameter is for the smallest group of...";
CM_ SG_ 2364691710 Hvesp11LowestCellTemperature "HVESP11 Lowest Cell Temperature: The lowest temperature level reported by any cell in this High Voltage Energy Storage Pack instance. If a single temperature sensor covers more than one cell, the value in this parameter is for the smallest group of c...";
CM_ SG_ 2364691710 Hvesp11AverageCellTemperature "HVESP11 Average Cell Temperature: The average temperature level of all cells in this High Voltage Energy Storage Pack instance.This parameter is for one of multiple packs in an HVESS.  If there is only one pack in the system, the HVESS parameters sho...";
CM_ SG_ 2364691710 Hvsp11CllTmprtrDffrntlStts "HVESP11 Cell Temperature Differential Status: Indicates whether or not the differential between the highest and lowest cell temperatures are within acceptable limits per this High Voltage Energy Storage Pack instance. The actual temperature different...";
CM_ BO_ 2364691966 "High Voltage Energy Storage Pack 11 Data 4";
CM_ SG_ 2364691966 Hvesp11DischargeCapacity "HVESP11 Discharge Capacity: The amount of stored electrical charge in this High Voltage Energy Storage Pack instance that is available for use by the hybrid or EV system, i.e. 'how full is the tank'. See SPN 15334 (HVESP11 Discharge Energy Capacity) ...";
CM_ SG_ 2364691966 Hvesp11ChargeCapacity "HVESP11 Charge Capacity: The amount of unused electrical charge storage in this High Voltage Energy Storage Pack instance that is available to be filled by charging, i.e. 'how much empty space is remaining in the tank'. See SPN 15335 (HVESP11 Charge ...";
CM_ SG_ 2364691966 Hvesp11CellBalancingCount "HVESP11 Cell Balancing Count: The number of cells that are currently being balanced in this High Voltage Energy Storage Pack instance.This parameter is for one of multiple packs in an HVESS.  If there is only one pack in the system, the HVESS paramet...";
CM_ BO_ 2364692222 "High Voltage Energy Storage Pack 11 Data 5";
CM_ SG_ 2364692222 Hvesp11LowestCellStateOfCharge "HVESP11 Lowest Cell State of Charge: Indicates the state of charge of the lowest-charged cell in this High Voltage Energy Storage Pack instance. 0% means no charge remaining, 100% means the cell is fully charged. If a single state of charge value cov...";
CM_ SG_ 2364692222 Hvesp11HighestCellStateOfCharge "HVESP11 Highest Cell State of Charge: Indicates the state of charge of the highest-charged cell in this High Voltage Energy Storage Pack instance. 0% means no charge remaining, 100% means the cell is fully charged. If a single state of charge value c...";
CM_ SG_ 2364692222 Hvsp11MxmmInstntnsDshrgCrrntLmt "HVESP11 Maximum Instantaneous Discharge Current Limit: The maximum instantaneous current flow limit out of this High Voltage Energy Storage Pack instance. This parameter is defined from the high voltage energy storage pack's point of view and should ...";
CM_ SG_ 2364692222 Hvsp11MxmmInstntnsChrgCrrntLmt "HVESP11 Maximum Instantaneous Charge Current Limit: The maximum instantaneous current flow limit into this High Voltage Energy Storage Pack instance. This parameter is defined from the high voltage energy storage pack's point of view and should refle...";
CM_ BO_ 2364692478 "High Voltage Energy Storage Pack 11 Data 6";
CM_ SG_ 2364692478 Hvesp11BusVoltage "HVESP11 Bus Voltage: The voltage level of the high voltage bus, as measured by this High Voltage Energy Storage Pack instance on the bus side (not the battery side) of its contactors.This parameter is for one of multiple packs in an HVESS.  If there ...";
CM_ SG_ 2364692478 Hvesp11IgnitionVoltage "HVESP11 Ignition Voltage: The voltage level at the ignition input of this High Voltage Energy Storage Pack controller.This parameter is for one of multiple packs in an HVESS.  If there is only one pack in the system, the HVESS parameters should be us...";
CM_ SG_ 2364692478 Hvesp11IntakeCoolantTemperature "HVESP11 Intake Coolant Temperature: The temperature of liquid coolant as it enters this High Voltage Energy Storage Pack instance.This parameter is for one of multiple packs in an HVESS.  If there is only one pack in the system, the HVESS parameters ...";
CM_ SG_ 2364692478 Hvesp11OutletCoolantTemperature "HVESP11 Outlet Coolant Temperature: The temperature of liquid coolant as it exits this High Voltage Energy Storage Pack instance.This parameter is for one of multiple packs in an HVESS.  If there is only one pack in the system, the HVESS parameters s...";
CM_ SG_ 2364692478 Hvesp11ElectronicsTemperature "HVESP11 Electronics Temperature: The temperature of the electronics or control modules in this High Voltage Energy Storage Pack instance.  If there are multiple temperature sensors then this parameter would be set to the maximum sensor reading.This p...";
CM_ SG_ 2364692478 Hvesp11Temperature "HVESP11 Temperature: The temperature of this High Voltage Energy Storage Pack instance. The value may be determined from a unique sensor specifically for this purpose, or by aggregating various temperature sensor readings within the pack.This paramet...";
CM_ BO_ 2364692734 "High Voltage Energy Storage Pack 11 Status 1";
CM_ SG_ 2364692734 Hvsp11HghVltgBsPstvCnttrStt "HVESP11 High-Voltage Bus (Positive) Contactor State: Position of this High Voltage Energy Storage Pack instance positive side bus contactor.  When this contactor is closed, the positive side of this HVES instance is connected to the positive side of ...";
CM_ SG_ 2364692734 Hvsp11HghVltgBsNgtvCnttrStt "HVESP11 High-Voltage Bus (Negative) Contactor State: Position of this High Voltage Energy Storage Pack instance negative side bus contactor. When this contactor is closed, the negative side of this HVES instance is connected to the negative side of t...";
CM_ SG_ 2364692734 Hvsp11HghVltgBsDsnntFrwrnng "HVESP11 High-Voltage Bus Disconnect Forewarning: Indicates that this High Voltage Energy Storage Pack instance is about to disconnect from the high voltage bus due to unacceptable conditions.This parameter is for one of multiple packs in an HVESS. If...";
CM_ SG_ 2364692734 Hvsp11HghVltgBsPrChrgRlStt "HVESP11 High-Voltage Bus Pre-Charge Relay State: Position of the high-voltage bus contactor pre-charge relay.  When this relay is closed, this High Voltage Energy Storage Pack instance is bringing the high-voltage bus up to its operating level.This p...";
CM_ SG_ 2364692734 Hvsp11CntrOfPkCnttrStt "HVESP11 Center of Pack Contactor State: Position of the center high-voltage contactor. When this contactor is closed, the positive half of this High Voltage Energy Storage Pack instance is connected to the negative half. If a system controls the posi...";
CM_ SG_ 2364692734 Hvsp11HghVltgBsAtvIsltnTstStts "HVESP11 High-Voltage Bus Active Isolation Test Status: Status of the high-voltage bus electrical active isolation test as performed by this High Voltage Energy Storage Pack instance.This parameter is for one of multiple packs in an HVESS. If there is...";
CM_ SG_ 2364692734 Hvsp11HghVltgBsPssvIsltnTstStts "HVESP11 High-Voltage Bus Passive Isolation Test Status: Status of the high-voltage bus electrical passive isolation test as performed by this High Voltage Energy Storage Pack instance.This parameter is for one of multiple packs in an HVESS. If there ...";
CM_ SG_ 2364692734 Hvesp11HvilStatus "HVESP11 HVIL Status: Status of the High Voltage Interlock Loop from the viewpoint of this High Voltage Energy Storage Pack instance.This parameter is for one of multiple packs in an HVESS. If there is only one pack in the system, the HVESS parameters...";
CM_ SG_ 2364692734 Hvesp11InertiaSwitchStatus "HVESP11 Inertia Switch Status: Switch indicating that an impact has been sensed by this High Voltage Energy Storage Pack instance. The impact indication may require action by another controller, or by this HVES instance itself.  For example, a contro...";
CM_ SG_ 2364692734 Hvesp11StateOfChargeStatus "HVESP11 State of Charge Status: Status of this High Voltage Energy Storage Pack instance State of Charge (SOC).  Note:  A given HVES controller may not support all of the states.This parameter is for one of multiple packs in an HVESS.  If there is on...";
CM_ SG_ 2364692734 Hvesp11CellBalanceStatus "HVESP11 Cell Balance Status: Indicates whether or not the cells in this High Voltage Energy Storage Pack instance are balanced.This parameter is for one of multiple packs in an HVESS.  If there is only one pack in the system, the HVESS parameters sho...";
CM_ SG_ 2364692734 Hvesp11CellBalancingActive "HVESP11 Cell Balancing Active: Indicates whether or not the cells in this High Voltage Energy Storage Pack instance are currently being balanced.This parameter is for one of multiple packs in an HVESS.  If there is only one pack in the system, the HV...";
CM_ SG_ 2364692734 Hvesp11InternalChargerStatus "HVESP11 Internal Charger Status: Indicates that the charger in this HVES instance is on.  External chargers may use the External Energy Source Connection Status (SPN 7898) and related SPs.This parameter is for one of multiple packs in an HVESS. If th...";
CM_ SG_ 2364692734 Hvsp11HghVltgBsCnntnStts "HVESP11 High-Voltage Bus Connection Status: This parameter provides high level feedback on this High Voltage Energy Storage Pack instance high voltage bus connection. For specific contactor information, see SPN 15317 (HVESP11 High-Voltage Bus (Positi...";
CM_ SG_ 2364692734 Hvesp11OperationalStatus "HVESP11 Operational Status: Provides feedback on where this High Voltage Energy Storage Pack instance is in its operating spectrum, and includes feedback in response to the Operation Consent [i.e. SPN 15275 (HVESP11 Operation Consent)] and Power Down...";
CM_ SG_ 2364692734 Hvesp11Status1Counter "HVESP11 Status 1 Counter: The message counter is used to detect situations where the transmitting ECU malfunction repeats the same frame all the time. The receiver of the information may use the counter parameter to detect this situation. The transmi...";
CM_ SG_ 2364692734 Hvesp11Status1Crc "HVESP11 Status 1 CRC: The CRC is defined as follows: - Length: 8 bits- Polynomial: x^8+x^5+x^3+x^2+x+1- Initial Value: FFh- Input Data Reflection: Not reflected- Result Data Reflection: Not reflected- XOR value: FFh SAE makes no claim of the function...";
CM_ BO_ 2364692990 "High Voltage Energy Storage Pack 11 Data 7";
CM_ SG_ 2364692990 Hvesp11DischargeEnergyCapacity "HVESP11 Discharge Energy Capacity: The amount of stored electrical energy in this High Voltage Energy Storage Pack instance that is available for use by the hybrid or EV system, i.e. 'how full is the tank'. See SPN 15304 (HVESP11 Discharge Capacity) ...";
CM_ SG_ 2364692990 Hvesp11ChargeEnergyCapacity "HVESP11 Charge Energy Capacity: The amount of unused electrical energy storage available to be filled by charging this High Voltage Energy Storage Pack instance, i.e. 'how much empty space is remaining in the tank'. See SPN 15305 (HVESP11 Charge Capa...";
CM_ SG_ 2364692990 Hvsp11MxmmChrgVltgLmt "HVESP11 Maximum Charge Voltage Limit: The maximum voltage level not to be exceeded while charging this High Voltage Energy Storage Pack instance. If this parameter is not supported, the maximum charge voltage should be limited to SPN 15403 (HVESP11 R...";
CM_ BO_ 2364693246 "High Voltage Energy Storage Pack 11 Module Status 1";
CM_ SG_ 2364693246 Hvesp11Module1OperationalStatus "HVESP11 Module 1 Operational Status: Operational Status of Module 1 in this High Voltage Energy Storage Pack Instance.  Not Operational is used when the module is initializing or not able to function (e.g. internal module level monitors have failed)....";
CM_ SG_ 2364693246 Hvesp11Module2OperationalStatus "HVESP11 Module 2 Operational Status: Operational Status of Module 2 in this High Voltage Energy Storage Pack Instance.  Not Operational is used when the module is initializing or not able to function (e.g. internal module level monitors have failed)....";
CM_ SG_ 2364693246 Hvesp11Module3OperationalStatus "HVESP11 Module 3 Operational Status: Operational Status of Module 3 in this High Voltage Energy Storage Pack Instance.  Not Operational is used when the module is initializing or not able to function (e.g. internal module level monitors have failed)....";
CM_ SG_ 2364693246 Hvesp11Module4OperationalStatus "HVESP11 Module 4 Operational Status: Operational Status of Module 4 in this High Voltage Energy Storage Pack Instance.  Not Operational is used when the module is initializing or not able to function (e.g. internal module level monitors have failed)....";
CM_ SG_ 2364693246 Hvesp11Module5OperationalStatus "HVESP11 Module 5 Operational Status: Operational Status of Module 5 in this High Voltage Energy Storage Pack Instance.  Not Operational is used when the module is initializing or not able to function (e.g. internal module level monitors have failed)....";
CM_ SG_ 2364693246 Hvesp11Module6OperationalStatus "HVESP11 Module 6 Operational Status: Operational Status of Module 6 in this High Voltage Energy Storage Pack Instance.  Not Operational is used when the module is initializing or not able to function (e.g. internal module level monitors have failed)....";
CM_ SG_ 2364693246 Hvesp11Module7OperationalStatus "HVESP11 Module 7 Operational Status: Operational Status of Module 7 in this High Voltage Energy Storage Pack Instance.  Not Operational is used when the module is initializing or not able to function (e.g. internal module level monitors have failed)....";
CM_ SG_ 2364693246 Hvesp11Module8OperationalStatus "HVESP11 Module 8 Operational Status: Operational Status of Module 8 in this High Voltage Energy Storage Pack Instance.  Not Operational is used when the module is initializing or not able to function (e.g. internal module level monitors have failed)....";
CM_ SG_ 2364693246 Hvesp11Module9OperationalStatus "HVESP11 Module 9 Operational Status: Operational Status of Module 9 in this High Voltage Energy Storage Pack Instance.  Not Operational is used when the module is initializing or not able to function (e.g. internal module level monitors have failed)....";
CM_ SG_ 2364693246 Hvsp11Mdl10OprtnlStts "HVESP11 Module 10 Operational Status: Operational Status of Module 10 in this High Voltage Energy Storage Pack Instance.  Not Operational is used when the module is initializing or not able to function (e.g. internal module level monitors have failed...";
CM_ SG_ 2364693246 Hvsp11Mdl11OprtnlStts "HVESP11 Module 11 Operational Status: Operational Status of Module 11 in this High Voltage Energy Storage Pack Instance.  Not Operational is used when the module is initializing or not able to function (e.g. internal module level monitors have failed...";
CM_ SG_ 2364693246 Hvsp11Mdl12OprtnlStts "HVESP11 Module 12 Operational Status: Operational Status of Module 12 in this High Voltage Energy Storage Pack Instance.  Not Operational is used when the module is initializing or not able to function (e.g. internal module level monitors have failed...";
CM_ SG_ 2364693246 Hvsp11Mdl13OprtnlStts "HVESP11 Module 13 Operational Status: Operational Status of Module 13 in this High Voltage Energy Storage Pack Instance.  Not Operational is used when the module is initializing or not able to function (e.g. internal module level monitors have failed...";
CM_ SG_ 2364693246 Hvsp11Mdl14OprtnlStts "HVESP11 Module 14 Operational Status: Operational Status of Module 14 in this High Voltage Energy Storage Pack Instance.  Not Operational is used when the module is initializing or not able to function (e.g. internal module level monitors have failed...";
CM_ SG_ 2364693246 Hvsp11Mdl15OprtnlStts "HVESP11 Module 15 Operational Status: Operational Status of Module 15 in this High Voltage Energy Storage Pack Instance.  Not Operational is used when the module is initializing or not able to function (e.g. internal module level monitors have failed...";
CM_ SG_ 2364693246 Hvsp11Mdl16OprtnlStts "HVESP11 Module 16 Operational Status: Operational Status of Module 16 in this High Voltage Energy Storage Pack Instance.  Not Operational is used when the module is initializing or not able to function (e.g. internal module level monitors have failed...";
CM_ SG_ 2364693246 Hvsp11Mdl17OprtnlStts "HVESP11 Module 17 Operational Status: Operational Status of Module 17 in this High Voltage Energy Storage Pack Instance.  Not Operational is used when the module is initializing or not able to function (e.g. internal module level monitors have failed...";
CM_ SG_ 2364693246 Hvsp11Mdl18OprtnlStts "HVESP11 Module 18 Operational Status: Operational Status of Module 18 in this High Voltage Energy Storage Pack Instance.  Not Operational is used when the module is initializing or not able to function (e.g. internal module level monitors have failed...";
CM_ SG_ 2364693246 Hvsp11Mdl19OprtnlStts "HVESP11 Module 19 Operational Status: Operational Status of Module 19 in this High Voltage Energy Storage Pack Instance.  Not Operational is used when the module is initializing or not able to function (e.g. internal module level monitors have failed...";
CM_ SG_ 2364693246 Hvsp11Mdl20OprtnlStts "HVESP11 Module 20 Operational Status: Operational Status of Module 20 in this High Voltage Energy Storage Pack Instance.  Not Operational is used when the module is initializing or not able to function (e.g. internal module level monitors have failed...";
CM_ SG_ 2364693246 Hvsp11Mdl21OprtnlStts "HVESP11 Module 21 Operational Status: Operational Status of Module 21 in this High Voltage Energy Storage Pack Instance.  Not Operational is used when the module is initializing or not able to function (e.g. internal module level monitors have failed...";
CM_ SG_ 2364693246 Hvsp11Mdl22OprtnlStts "HVESP11 Module 22 Operational Status: Operational Status of Module 22 in this High Voltage Energy Storage Pack Instance.  Not Operational is used when the module is initializing or not able to function (e.g. internal module level monitors have failed...";
CM_ SG_ 2364693246 Hvsp11Mdl23OprtnlStts "HVESP11 Module 23 Operational Status: Operational Status of Module 23 in this High Voltage Energy Storage Pack Instance.  Not Operational is used when the module is initializing or not able to function (e.g. internal module level monitors have failed...";
CM_ SG_ 2364693246 Hvsp11Mdl24OprtnlStts "HVESP11 Module 24 Operational Status: Operational Status of Module 24 in this High Voltage Energy Storage Pack Instance.  Not Operational is used when the module is initializing or not able to function (e.g. internal module level monitors have failed...";
CM_ SG_ 2364693246 Hvsp11Mdl25OprtnlStts "HVESP11 Module 25 Operational Status: Operational Status of Module 25 in this High Voltage Energy Storage Pack Instance.  Not Operational is used when the module is initializing or not able to function (e.g. internal module level monitors have failed...";
CM_ SG_ 2364693246 Hvsp11Mdl26OprtnlStts "HVESP11 Module 26 Operational Status: Operational Status of Module 26 in this High Voltage Energy Storage Pack Instance.  Not Operational is used when the module is initializing or not able to function (e.g. internal module level monitors have failed...";
CM_ SG_ 2364693246 Hvsp11Mdl27OprtnlStts "HVESP11 Module 27 Operational Status: Operational Status of Module 27 in this High Voltage Energy Storage Pack Instance.  Not Operational is used when the module is initializing or not able to function (e.g. internal module level monitors have failed...";
CM_ SG_ 2364693246 Hvsp11Mdl28OprtnlStts "HVESP11 Module 28 Operational Status: Operational Status of Module 28 in this High Voltage Energy Storage Pack Instance.  Not Operational is used when the module is initializing or not able to function (e.g. internal module level monitors have failed...";
CM_ SG_ 2364693246 Hvsp11Mdl29OprtnlStts "HVESP11 Module 29 Operational Status: Operational Status of Module 29 in this High Voltage Energy Storage Pack Instance.  Not Operational is used when the module is initializing or not able to function (e.g. internal module level monitors have failed...";
CM_ SG_ 2364693246 Hvsp11Mdl30OprtnlStts "HVESP11 Module 30 Operational Status: Operational Status of Module 30 in this High Voltage Energy Storage Pack Instance.  Not Operational is used when the module is initializing or not able to function (e.g. internal module level monitors have failed...";
CM_ SG_ 2364693246 Hvsp11Mdl31OprtnlStts "HVESP11 Module 31 Operational Status: Operational Status of Module 31 in this High Voltage Energy Storage Pack Instance.  Not Operational is used when the module is initializing or not able to function (e.g. internal module level monitors have failed...";
CM_ SG_ 2364693246 Hvsp11Mdl32OprtnlStts "HVESP11 Module 32 Operational Status: Operational Status of Module 32 in this High Voltage Energy Storage Pack Instance.  Not Operational is used when the module is initializing or not able to function (e.g. internal module level monitors have failed...";
CM_ BO_ 2364693502 "High Voltage Energy Storage Pack 11 Thermal Management System Status 1";
CM_ SG_ 2364693502 Hvsp11ThrmlMngmntSstmSlInptPwr "HVESP11 Thermal Management System SLI Input Power: This is the low-voltage power consumed by this HVES Thermal Management System (TMS).This parameter is for one of multiple packs in an HVESS.  If there is only one pack in the system, the HVESS parame...";
CM_ SG_ 2364693502 Hvsp11TMtSstHVtIptPw "HVESP11 Thermal Management System High-Voltage Input Power: This is the high-voltage power consumed by this HVES Thermal Management System (TMS).This parameter is for one of multiple packs in an HVESS.  If there is only one pack in the system, the HV...";
CM_ SG_ 2364693502 Hvsp11ThrmlMngmntSstmCmprssrSpd "HVESP11 Thermal Management System Compressor Speed: When this High Voltage Energy Storage Pack Thermal Management System is equipped with an active cooling system (e.g. air conditioner), this is the Compressor Speed.This parameter is for one of multi...";
CM_ SG_ 2364693502 Hvsp11ThrmlMngmntSstmRltvHmdt "HVESP11 Thermal Management System Relative Humidty: When this High Voltage Energy Storage Pack Thermal Management System is equipped with a relative humidity sensor, this is the  measured Relative Humidity.This parameter is for one of multiple packs ...";
CM_ SG_ 2364693502 Hvsp11ThrmlMngmntSstmHtrStts "HVESP11 Thermal Management System Heater Status: The state of this High Voltage Energy Storage Pack heaterThis parameter is for one of multiple packs in an HVESS.  If there is only one pack in the system, the HVESS parameters should be used. If there...";
CM_ SG_ 2364693502 Hvsp11ThrmlMngmntSstmHvlStts "HVESP11 Thermal Management System HVIL Status: In multiple HVES configurations, this is the status of the High Voltage Interlock Loop from the viewpoint of this Thermal Management System.00b = HVIL Closed01b = HVIL Open10b = Error11b = Not AvailableT...";
CM_ SG_ 2364693502 Hvsp11ThrmlMngmntSstmMd "HVESP11 Thermal Management System Mode: Indicates the operating mode of the Thermal Management System.  The heat transfer medium may be (e.g. liquid or air).  The cooling system may be fans, liquid coolant, or a combination of mediums.  The system ma...";
CM_ SG_ 2364693502 Hvsp11ThrmlMngmntSstmClntLvl "HVESP11 Thermal Management System Coolant Level: Indicates the coolant level in this HVES Thermal Management System (TMS).This parameter is for one of multiple packs in an HVESS.  If there is only one pack in the system, the HVESS parameters should b...";
CM_ BO_ 2364693758 "High Voltage Energy Storage Pack 11 Data 8";
CM_ SG_ 2364693758 Hvsp11HghstCllVltgMdlNmr "HVESP11 Highest Cell Voltage Module Number: Identifies the location of the module containing SPN 15297 (HVESP11 Highest Cell Voltage).This parameter is for one of multiple packs in an HVESS. If there is only one pack in the system, the HVESS paramete...";
CM_ SG_ 2364693758 Hvsp11HghstCllVltgCllNmr "HVESP11 Highest Cell Voltage Cell Number: Identifies the location of SPN 15297 (HVESP11 Highest Cell Voltage) within SPN 15377 (HVESP11 Highest Cell Voltage Module Number).This parameter is for one of multiple packs in an HVESS. If there is only one ...";
CM_ SG_ 2364693758 Hvsp11LwstCllVltgMdlNmr "HVESP11 Lowest Cell Voltage Module Number: Identifies the location of the module containing SPN 15298 (HVESP11 Lowest Cell Voltage).This parameter is for one of multiple packs in an HVESS. If there is only one pack in the system, the HVESS parameters...";
CM_ SG_ 2364693758 Hvsp11LwstCllVltgCllNmr "HVESP11 Lowest Cell Voltage Cell Number: Identifies the location of SPN 15298 (HVESP11 Lowest Cell Voltage) within SPN 15379 (HVESP11 Lowest Cell Voltage Module Number).This parameter is for one of multiple packs in an HVESS. If there is only one pac...";
CM_ SG_ 2364693758 Hvesp11AverageCellVoltage "HVESP11 Average Cell Voltage: The average cell voltage in this High Voltage Energy Storage Pack instance.This parameter is for one of multiple packs in an HVESS.  If there is only one pack in the system, the HVESS parameters should be used. If there ...";
CM_ BO_ 2364694014 "High Voltage Energy Storage Pack 11 Data 9";
CM_ SG_ 2364694014 Hvsp11HghstCllTmprtrMdlNmr "HVESP11 Highest Cell Temperature Module Number: Identifies the location of the module containing SPN 15300 (HVESP11 Highest Cell Temperature).This parameter is for one of multiple packs in an HVESS. If there is only one pack in the system, the HVESS ...";
CM_ SG_ 2364694014 Hvsp11HghstCllTmprtrCllNmr "HVESP11 Highest Cell Temperature Cell Number: Identifies the location of SPN 15300 (HVESP11 Highest Cell Temperature) within SPN 15382 (HVESP11 Highest Cell Temperature Module Number).This parameter is for one of multiple packs in an HVESS. If there ...";
CM_ SG_ 2364694014 Hvsp11LwstCllTmprtrMdlNmr "HVESP11 Lowest Cell Temperature Module Number: Identifies the location of the module containing SPN 15301 (HVESP11 Lowest Cell Temperature).This parameter is for one of multiple packs in an HVESS. If there is only one pack in the system, the HVESS pa...";
CM_ SG_ 2364694014 Hvsp11LwstCllTmprtrCllNmr "HVESP11 Lowest Cell Temperature Cell Number: Identifies the location of SPN 15301 (HVESP11 Lowest Cell Temperature) within SPN 15384 (HVESP11 Lowest Cell Temperature Module Number).This parameter is for one of multiple packs in an HVESS. If there is ...";
CM_ SG_ 2364694014 Hvess11ThermalEventDetected "HVESS11 Thermal Event Detected: A sensor has detected the presence of a thermal event at or near High Voltage Energy Storage Pack instance.00b = No Thermal Event Detected01b = Thermal Event Detected10b = Error11b = Not availableThis parameter is for ...";
CM_ SG_ 2364694014 Hvsp11Dt9EmdddIntgrtSpprt "HVESP11 Data 9 Embedded Integrity Support: Indicates SPN 23006 (HVESP11 Data 9 CRC) and SPN 23005 (HVESP11 Data 9 Counter) are supported by the sender.00b = Embedded CRC and Counter are supported by the sender01b = Protection is provided using an ext...";
CM_ SG_ 2364694014 Hvesp11Data9Counter "HVESP11 Data 9 Counter: The message counter is used to detect situations where the transmitting ECU malfunction repeats the same frame all the time. The receiver of the information may use the counter parameter to detect this situation. The transmitt...";
CM_ SG_ 2364694014 Hvesp11Data9Crc "HVESP11 Data 9 CRC: The CRC is defined as follows: - Length: 8 bits- Polynomial: x^8+x^5+x^3+x^2+x+1- Initial Value: FFh- Input Data Reflection: Not reflected- Result Data Reflection: Not reflected- XOR value: FFh SAE makes no claim of the functional...";
CM_ BO_ 2364694270 "High Voltage Energy Storage Pack 11 Data 10";
CM_ SG_ 2364694270 Hvsp11HghstCllSttOfChrgMdlNmr "HVESP11 Highest Cell State of Charge Module Number: Identifies the location of the module containing SPN 15310 (HVESP11 Highest Cell State of Charge).This parameter is for one of multiple packs in an HVESS. If there is only one pack in the system, th...";
CM_ SG_ 2364694270 Hvsp11HghstCllSttOfChrgCllNmr "HVESP11 Highest Cell State of Charge Cell Number: Identifies the location of SPN 15310 (HVESP11 Highest Cell State of Charge) within SPN 15386 (HVESP11 Highest Cell State of Charge Module Number).This parameter is for one of multiple packs in an HVES...";
CM_ SG_ 2364694270 Hvsp11LwstCllSttOfChrgMdlNmr "HVESP11 Lowest Cell State of Charge Module Number: Identifies the location of the module containing SPN 15309 (HVESP11 Lowest Cell State of Charge).This parameter is for one of multiple packs in an HVESS. If there is only one pack in the system, the ...";
CM_ SG_ 2364694270 Hvsp11LwstCllSttOfChrgCllNmr "HVESP11 Lowest Cell State of Charge Cell Number: Identifies the location of SPN 15309 (HVESP11 Lowest Cell State of Charge) within SPN 15388 (HVESP11 Lowest Cell State of Charge Module Number).This parameter is for one of multiple packs in an HVESS. ...";
CM_ SG_ 2364694270 Hvsp11HghVltgBsAtvIsltnTstRslts "HVESP11 High-Voltage Bus Active Isolation Test Results: The isolation resistance expressed in Ohms per Volt that resulted from the High-Voltage Bus Active Isolation Test.See SPN 15322 (HVESP11 High-Voltage Bus Active Isolation Test Status) for test s...";
CM_ SG_ 2364694270 Hvsp11HVtBsPssvIstTstRsts "HVESP11 High-Voltage Bus Passive Isolation Test Results: The isolation resistance expressed in Ohms per Volt that resulted from the High-Voltage Bus Passive Isolation Test.See SPN 15323 (HVESP11 High-Voltage Bus Passive Isolation Test Status) for tes...";
CM_ BO_ 2364694526 "High Voltage Energy Storage Pack 11 Data 11";
CM_ SG_ 2364694526 Hvsp11BsVltgNgtvTChsssGrndVltg "HVESP11 Bus Voltage Negative to Chassis Ground Voltage: Voltage difference between the most negative terminal of the HVES battery and chassis measured on the hybrid or EV system bus side (not the battery side) of any HVES contained output contactor. ...";
CM_ SG_ 2364694526 Hvsp11VltgLvlNgtvTChsssGrndVltg "HVESP11 Voltage Level Negative to Chassis Ground Voltage: Voltage difference between the most negative terminal of the HVES battery and chassis measured at the battery side of any HVES contained output contactor.  This voltage may be used for system ...";
CM_ SG_ 2364694526 Hvesp11ActualChargeRate "HVESP11 Actual Charge Rate: This signal represents the actual present charge rate of this High Voltage Energy Storage Pack instance.This parameter is for one of multiple packs in an HVESS. If there is only one pack in the system, the HVESS parameters...";
CM_ BO_ 2364694782 "High Voltage Energy Storage Pack 12 Status 2";
CM_ SG_ 2364694782 Hvsp12DshrgPwrLmtDTSttOfChrg "HVESP12 Discharge Power Limit Due to State of Charge: Indicates whether or not discharge power of this HVES instance is being limited due to state of charge.This parameter is for one of multiple packs in an HVESS.  If there is only one pack in the sy...";
CM_ SG_ 2364694782 Hvsp12DshrgPwrLmtDTBttrTmprtr "HVESP12 Discharge Power Limit Due to Battery Temperature: Indicates whether or not discharge power of this HVES instance is being limited due to battery temperature.This parameter is for one of multiple packs in an HVESS.  If there is only one pack i...";
CM_ SG_ 2364694782 Hvsp12DsPwLtDTBttDstCdt "HVESP12 Discharge Power Limit Due to Battery Diagnostic Condition: Indicates whether or not discharge power of this HVES instance is being limited due to a battery diagnostic condition.This parameter is for one of multiple packs in an HVESS.  If ther...";
CM_ SG_ 2364694782 Hvsp12DsPwLtDTBttOCVt "HVESP12 Discharge Power Limit Due to Battery or Cell Voltage: Indicates whether or not discharge power of this HVES instance is being limited due to a battery or cell voltage level.This parameter is for one of multiple packs in an HVESS.  If there is...";
CM_ SG_ 2364694782 Hvsp12DshrgPwrLmtDTBttrCrrnt "HVESP12 Discharge Power Limit Due to Battery Current: Indicates whether or not discharge power of this HVES instance is being limited due to battery current.This parameter is for one of multiple packs in an HVESS.  If there is only one pack in the sy...";
CM_ SG_ 2364694782 Hvsp12DshrgPwrLmtDTAnUndfndCs "HVESP12 Discharge Power Limit Due to an Undefined Cause: Indicates whether or not discharge power of this HVES instance is being limited due to an undefined cause.This parameter is for one of multiple packs in an HVESS.  If there is only one pack in ...";
CM_ SG_ 2364694782 Hvsp12ChrgPwrLmtDTSttOfChrg "HVESP12 Charge Power Limit Due to State of Charge: Indicates whether or not charge power of this HVES instance is being limited due to state of charge.This parameter is for one of multiple packs in an HVESS.  If there is only one pack in the system, ...";
CM_ SG_ 2364694782 Hvsp12ChrgPwrLmtDTBttrTmprtr "HVESP12 Charge Power Limit Due to Battery Temperature: Indicates whether or not charge power of this HVES instance is being limited due to battery temperature.This parameter is for one of multiple packs in an HVESS.  If there is only one pack in the ...";
CM_ SG_ 2364694782 Hvsp12CPwLtDTBttDstCdt "HVESP12 Charge Power Limit Due to Battery Diagnostic Condition: Indicates whether or not charge power of this HVES instance is being limited due to a battery diagnostic condition.This parameter is for one of multiple packs in an HVESS.  If there is o...";
CM_ SG_ 2364694782 Hvsp12ChrgPwrLmtDTBttrOrCllVltg "HVESP12 Charge Power Limit Due to Battery or Cell Voltage: Indicates whether or not charge power of this HVES instance is being limited due to a battery or cell voltage level.This parameter is for one of multiple packs in an HVESS.  If there is only ...";
CM_ SG_ 2364694782 Hvsp12ChrgPwrLmtDTBttrCrrnt "HVESP12 Charge Power Limit Due to Battery Current: Indicates whether or not charge power of this HVES instance is being limited due to battery current.This parameter is for one of multiple packs in an HVESS.  If there is only one pack in the system, ...";
CM_ SG_ 2364694782 Hvsp12ChrgPwrLmtDTAnUndfndCs "HVESP12 Charge Power Limit Due to an Undefined Cause: Indicates whether or not charge power of this HVES instance is being limited due to an undefined cause.This parameter is for one of multiple packs in an HVESS.  If there is only one pack in the sy...";
CM_ BO_ 2364695038 "High Voltage Energy Storage Pack 12 Data 1";
CM_ SG_ 2364695038 Hvesp12AvailableDischargePower "HVESP12 Available Discharge Power: The rate at which this High Voltage Energy Storage Pack instance can currently provide energy for propulsion or other uses.This parameter is for one of multiple packs in an HVESS.  If there is only one pack in the s...";
CM_ SG_ 2364695038 Hvesp12AvailableChargePower "HVESP12 Available Charge Power: The rate at which this High Voltage Energy Storage Pack instance can currently receive energy from a regenerative or recharging system.This parameter is for one of multiple packs in an HVESS.  If there is only one pack...";
CM_ SG_ 2364695038 Hvesp12VoltageLevel "HVESP12 Voltage Level: The voltage level of this High Voltage Energy Storage Pack instance. This parameter should be synchronized with SPN 15437 (HVESP12 Current) such that a realized power value can be calculated. If the HVES component physically co...";
CM_ SG_ 2364695038 Hvesp12Current "HVESP12 Current: The current in or out of this High Voltage Energy Storage Pack instance. This parameter should be synchronized with SPN 15436 (HVESP12 Voltage Level) such that a realized power value can be calculated. This parameter is defined from ...";
CM_ BO_ 2364695294 "High Voltage Energy Storage Pack 12 Data 2";
CM_ SG_ 2364695294 Hvesp12FastUpdateStateOfCharge "HVESP12 Fast Update State of Charge: Indicates this High Voltage Energy Storage Pack instance state of charge. 0% means no charge remaining, 100% means the system is fully charged in terms of physical limits of this energy storage pack instance. Acce...";
CM_ SG_ 2364695294 Hvesp12HighestCellVoltage "HVESP12 Highest Cell Voltage: The highest voltage level reported by any cell in this High Voltage Energy Storage Pack instance. If a single voltage sensor covers more than one cell, the value in this parameter is for the smallest group of cells measu...";
CM_ SG_ 2364695294 Hvesp12LowestCellVoltage "HVESP12 Lowest Cell Voltage: The lowest voltage level reported by any cell in this High Voltage Energy Storage Pack instance. If a single voltage sensor covers more than one cell, the value in this parameter is for the smallest group of cells measure...";
CM_ SG_ 2364695294 Hvsp12CllVltgDffrntlStts "HVESP12 Cell Voltage Differential Status: Indicates whether or not the differential between the highest and lowest cell voltages are within acceptable limits, according to this High Voltage Energy Storage Pack instance. The actual voltage differentia...";
CM_ BO_ 2364695550 "High Voltage Energy Storage Pack 12 Data 3";
CM_ SG_ 2364695550 Hvesp12HighestCellTemperature "HVESP12 Highest Cell Temperature: The highest temperature level reported by any cell in this High Voltage Energy Storage Pack instance. If a single temperature sensor covers more than one cell, the value in this parameter is for the smallest group of...";
CM_ SG_ 2364695550 Hvesp12LowestCellTemperature "HVESP12 Lowest Cell Temperature: The lowest temperature level reported by any cell in this High Voltage Energy Storage Pack instance. If a single temperature sensor covers more than one cell, the value in this parameter is for the smallest group of c...";
CM_ SG_ 2364695550 Hvesp12AverageCellTemperature "HVESP12 Average Cell Temperature: The average temperature level of all cells in this High Voltage Energy Storage Pack instance.This parameter is for one of multiple packs in an HVESS.  If there is only one pack in the system, the HVESS parameters sho...";
CM_ SG_ 2364695550 Hvsp12CllTmprtrDffrntlStts "HVESP12 Cell Temperature Differential Status: Indicates whether or not the differential between the highest and lowest cell temperatures are within acceptable limits per this High Voltage Energy Storage Pack instance. The actual temperature different...";
CM_ BO_ 2364695806 "High Voltage Energy Storage Pack 12 Data 4";
CM_ SG_ 2364695806 Hvesp12DischargeCapacity "HVESP12 Discharge Capacity: The amount of stored electrical charge in this High Voltage Energy Storage Pack instance that is available for use by the hybrid or EV system, i.e. 'how full is the tank'. See SPN 15476 (HVESP12 Discharge Energy Capacity) ...";
CM_ SG_ 2364695806 Hvesp12ChargeCapacity "HVESP12 Charge Capacity: The amount of unused electrical charge storage in this High Voltage Energy Storage Pack instance that is available to be filled by charging, i.e. 'how much empty space is remaining in the tank'. See SPN 15477 (HVESP12 Charge ...";
CM_ SG_ 2364695806 Hvesp12CellBalancingCount "HVESP12 Cell Balancing Count: The number of cells that are currently being balanced in this High Voltage Energy Storage Pack instance.This parameter is for one of multiple packs in an HVESS.  If there is only one pack in the system, the HVESS paramet...";
CM_ BO_ 2364696062 "High Voltage Energy Storage Pack 12 Data 5";
CM_ SG_ 2364696062 Hvesp12LowestCellStateOfCharge "HVESP12 Lowest Cell State of Charge: Indicates the state of charge of the lowest-charged cell in this High Voltage Energy Storage Pack instance. 0% means no charge remaining, 100% means the cell is fully charged. If a single state of charge value cov...";
CM_ SG_ 2364696062 Hvesp12HighestCellStateOfCharge "HVESP12 Highest Cell State of Charge: Indicates the state of charge of the highest-charged cell in this High Voltage Energy Storage Pack instance. 0% means no charge remaining, 100% means the cell is fully charged. If a single state of charge value c...";
CM_ SG_ 2364696062 Hvsp12MxmmInstntnsDshrgCrrntLmt "HVESP12 Maximum Instantaneous Discharge Current Limit: The maximum instantaneous current flow limit out of this High Voltage Energy Storage Pack instance. This parameter is defined from the high voltage energy storage pack's point of view and should ...";
CM_ SG_ 2364696062 Hvsp12MxmmInstntnsChrgCrrntLmt "HVESP12 Maximum Instantaneous Charge Current Limit: The maximum instantaneous current flow limit into this High Voltage Energy Storage Pack instance. This parameter is defined from the high voltage energy storage pack's point of view and should refle...";
CM_ BO_ 2364696318 "High Voltage Energy Storage Pack 12 Data 6";
CM_ SG_ 2364696318 Hvesp12BusVoltage "HVESP12 Bus Voltage: The voltage level of the high voltage bus, as measured by this High Voltage Energy Storage Pack instance on the bus side (not the battery side) of its contactors.This parameter is for one of multiple packs in an HVESS.  If there ...";
CM_ SG_ 2364696318 Hvesp12IgnitionVoltage "HVESP12 Ignition Voltage: The voltage level at the ignition input of this High Voltage Energy Storage Pack controller.This parameter is for one of multiple packs in an HVESS.  If there is only one pack in the system, the HVESS parameters should be us...";
CM_ SG_ 2364696318 Hvesp12IntakeCoolantTemperature "HVESP12 Intake Coolant Temperature: The temperature of liquid coolant as it enters this High Voltage Energy Storage Pack instance.This parameter is for one of multiple packs in an HVESS.  If there is only one pack in the system, the HVESS parameters ...";
CM_ SG_ 2364696318 Hvesp12OutletCoolantTemperature "HVESP12 Outlet Coolant Temperature: The temperature of liquid coolant as it exits this High Voltage Energy Storage Pack instance.This parameter is for one of multiple packs in an HVESS.  If there is only one pack in the system, the HVESS parameters s...";
CM_ SG_ 2364696318 Hvesp12ElectronicsTemperature "HVESP12 Electronics Temperature: The temperature of the electronics or control modules in this High Voltage Energy Storage Pack instance.  If there are multiple temperature sensors then this parameter would be set to the maximum sensor reading.This p...";
CM_ SG_ 2364696318 Hvesp12Temperature "HVESP12 Temperature: The temperature of this High Voltage Energy Storage Pack instance. The value may be determined from a unique sensor specifically for this purpose, or by aggregating various temperature sensor readings within the pack.This paramet...";
CM_ BO_ 2364696574 "High Voltage Energy Storage Pack 12 Status 1";
CM_ SG_ 2364696574 Hvsp12HghVltgBsPstvCnttrStt "HVESP12 High-Voltage Bus (Positive) Contactor State: Position of this High Voltage Energy Storage Pack instance positive side bus contactor.  When this contactor is closed, the positive side of this HVES instance is connected to the positive side of ...";
CM_ SG_ 2364696574 Hvsp12HghVltgBsNgtvCnttrStt "HVESP12 High-Voltage Bus (Negative) Contactor State: Position of this High Voltage Energy Storage Pack instance negative side bus contactor. When this contactor is closed, the negative side of this HVES instance is connected to the negative side of t...";
CM_ SG_ 2364696574 Hvsp12HghVltgBsDsnntFrwrnng "HVESP12 High-Voltage Bus Disconnect Forewarning: Indicates that this High Voltage Energy Storage Pack instance is about to disconnect from the high voltage bus due to unacceptable conditions.This parameter is for one of multiple packs in an HVESS. If...";
CM_ SG_ 2364696574 Hvsp12HghVltgBsPrChrgRlStt "HVESP12 High-Voltage Bus Pre-Charge Relay State: Position of the high-voltage bus contactor pre-charge relay.  When this relay is closed, this High Voltage Energy Storage Pack instance is bringing the high-voltage bus up to its operating level.This p...";
CM_ SG_ 2364696574 Hvsp12CntrOfPkCnttrStt "HVESP12 Center of Pack Contactor State: Position of the center high-voltage contactor. When this contactor is closed, the positive half of this High Voltage Energy Storage Pack instance is connected to the negative half. If a system controls the posi...";
CM_ SG_ 2364696574 Hvsp12HghVltgBsAtvIsltnTstStts "HVESP12 High-Voltage Bus Active Isolation Test Status: Status of the high-voltage bus electrical active isolation test as performed by this High Voltage Energy Storage Pack instance.This parameter is for one of multiple packs in an HVESS. If there is...";
CM_ SG_ 2364696574 Hvsp12HghVltgBsPssvIsltnTstStts "HVESP12 High-Voltage Bus Passive Isolation Test Status: Status of the high-voltage bus electrical passive isolation test as performed by this High Voltage Energy Storage Pack instance.This parameter is for one of multiple packs in an HVESS. If there ...";
CM_ SG_ 2364696574 Hvesp12HvilStatus "HVESP12 HVIL Status: Status of the High Voltage Interlock Loop from the viewpoint of this High Voltage Energy Storage Pack instance.This parameter is for one of multiple packs in an HVESS. If there is only one pack in the system, the HVESS parameters...";
CM_ SG_ 2364696574 Hvesp12InertiaSwitchStatus "HVESP12 Inertia Switch Status: Switch indicating that an impact has been sensed by this High Voltage Energy Storage Pack instance. The impact indication may require action by another controller, or by this HVES instance itself.  For example, a contro...";
CM_ SG_ 2364696574 Hvesp12StateOfChargeStatus "HVESP12 State of Charge Status: Status of this High Voltage Energy Storage Pack instance State of Charge (SOC).  Note:  A given HVES controller may not support all of the states.This parameter is for one of multiple packs in an HVESS.  If there is on...";
CM_ SG_ 2364696574 Hvesp12CellBalanceStatus "HVESP12 Cell Balance Status: Indicates whether or not the cells in this High Voltage Energy Storage Pack instance are balanced.This parameter is for one of multiple packs in an HVESS.  If there is only one pack in the system, the HVESS parameters sho...";
CM_ SG_ 2364696574 Hvesp12CellBalancingActive "HVESP12 Cell Balancing Active: Indicates whether or not the cells in this High Voltage Energy Storage Pack instance are currently being balanced.This parameter is for one of multiple packs in an HVESS.  If there is only one pack in the system, the HV...";
CM_ SG_ 2364696574 Hvesp12InternalChargerStatus "HVESP12 Internal Charger Status: Indicates that the charger in this HVES instance is on.  External chargers may use the External Energy Source Connection Status (SPN 7898) and related SPs.This parameter is for one of multiple packs in an HVESS. If th...";
CM_ SG_ 2364696574 Hvsp12HghVltgBsCnntnStts "HVESP12 High-Voltage Bus Connection Status: This parameter provides high level feedback on this High Voltage Energy Storage Pack instance high voltage bus connection. For specific contactor information, see SPN 15459 (HVESP12 High-Voltage Bus (Positi...";
CM_ SG_ 2364696574 Hvesp12OperationalStatus "HVESP12 Operational Status: Provides feedback on where this High Voltage Energy Storage Pack instance is in its operating spectrum, and includes feedback in response to the Operation Consent [i.e. SPN 15417 (HVESP12 Operation Consent)] and Power Down...";
CM_ SG_ 2364696574 Hvesp12Status1Counter "HVESP12 Status 1 Counter: The message counter is used to detect situations where the transmitting ECU malfunction repeats the same frame all the time. The receiver of the information may use the counter parameter to detect this situation. The transmi...";
CM_ SG_ 2364696574 Hvesp12Status1Crc "HVESP12 Status 1 CRC: The CRC is defined as follows: - Length: 8 bits- Polynomial: x^8+x^5+x^3+x^2+x+1- Initial Value: FFh- Input Data Reflection: Not reflected- Result Data Reflection: Not reflected- XOR value: FFh SAE makes no claim of the function...";
CM_ BO_ 2364696830 "High Voltage Energy Storage Pack 12 Data 7";
CM_ SG_ 2364696830 Hvesp12DischargeEnergyCapacity "HVESP12 Discharge Energy Capacity: The amount of stored electrical energy in this High Voltage Energy Storage Pack instance that is available for use by the hybrid or EV system, i.e. 'how full is the tank'. See SPN 15446 (HVESP12 Discharge Capacity) ...";
CM_ SG_ 2364696830 Hvesp12ChargeEnergyCapacity "HVESP12 Charge Energy Capacity: The amount of unused electrical energy storage available to be filled by charging this High Voltage Energy Storage Pack instance, i.e. 'how much empty space is remaining in the tank'. See SPN 15447 (HVESP12 Charge Capa...";
CM_ SG_ 2364696830 Hvsp12MxmmChrgVltgLmt "HVESP12 Maximum Charge Voltage Limit: The maximum voltage level not to be exceeded while charging this High Voltage Energy Storage Pack instance. If this parameter is not supported, the maximum charge voltage should be limited to SPN 15545 (HVESP12 R...";
CM_ BO_ 2364697086 "High Voltage Energy Storage Pack 12 Module Status 1";
CM_ SG_ 2364697086 Hvesp12Module1OperationalStatus "HVESP12 Module 1 Operational Status: Operational Status of Module 1 in this High Voltage Energy Storage Pack Instance.  Not Operational is used when the module is initializing or not able to function (e.g. internal module level monitors have failed)....";
CM_ SG_ 2364697086 Hvesp12Module2OperationalStatus "HVESP12 Module 2 Operational Status: Operational Status of Module 2 in this High Voltage Energy Storage Pack Instance.  Not Operational is used when the module is initializing or not able to function (e.g. internal module level monitors have failed)....";
CM_ SG_ 2364697086 Hvesp12Module3OperationalStatus "HVESP12 Module 3 Operational Status: Operational Status of Module 3 in this High Voltage Energy Storage Pack Instance.  Not Operational is used when the module is initializing or not able to function (e.g. internal module level monitors have failed)....";
CM_ SG_ 2364697086 Hvesp12Module4OperationalStatus "HVESP12 Module 4 Operational Status: Operational Status of Module 4 in this High Voltage Energy Storage Pack Instance.  Not Operational is used when the module is initializing or not able to function (e.g. internal module level monitors have failed)....";
CM_ SG_ 2364697086 Hvesp12Module5OperationalStatus "HVESP12 Module 5 Operational Status: Operational Status of Module 5 in this High Voltage Energy Storage Pack Instance.  Not Operational is used when the module is initializing or not able to function (e.g. internal module level monitors have failed)....";
CM_ SG_ 2364697086 Hvesp12Module6OperationalStatus "HVESP12 Module 6 Operational Status: Operational Status of Module 6 in this High Voltage Energy Storage Pack Instance.  Not Operational is used when the module is initializing or not able to function (e.g. internal module level monitors have failed)....";
CM_ SG_ 2364697086 Hvesp12Module7OperationalStatus "HVESP12 Module 7 Operational Status: Operational Status of Module 7 in this High Voltage Energy Storage Pack Instance.  Not Operational is used when the module is initializing or not able to function (e.g. internal module level monitors have failed)....";
CM_ SG_ 2364697086 Hvesp12Module8OperationalStatus "HVESP12 Module 8 Operational Status: Operational Status of Module 8 in this High Voltage Energy Storage Pack Instance.  Not Operational is used when the module is initializing or not able to function (e.g. internal module level monitors have failed)....";
CM_ SG_ 2364697086 Hvesp12Module9OperationalStatus "HVESP12 Module 9 Operational Status: Operational Status of Module 9 in this High Voltage Energy Storage Pack Instance.  Not Operational is used when the module is initializing or not able to function (e.g. internal module level monitors have failed)....";
CM_ SG_ 2364697086 Hvsp12Mdl10OprtnlStts "HVESP12 Module 10 Operational Status: Operational Status of Module 10 in this High Voltage Energy Storage Pack Instance.  Not Operational is used when the module is initializing or not able to function (e.g. internal module level monitors have failed...";
CM_ SG_ 2364697086 Hvsp12Mdl11OprtnlStts "HVESP12 Module 11 Operational Status: Operational Status of Module 11 in this High Voltage Energy Storage Pack Instance.  Not Operational is used when the module is initializing or not able to function (e.g. internal module level monitors have failed...";
CM_ SG_ 2364697086 Hvsp12Mdl12OprtnlStts "HVESP12 Module 12 Operational Status: Operational Status of Module 12 in this High Voltage Energy Storage Pack Instance.  Not Operational is used when the module is initializing or not able to function (e.g. internal module level monitors have failed...";
CM_ SG_ 2364697086 Hvsp12Mdl13OprtnlStts "HVESP12 Module 13 Operational Status: Operational Status of Module 13 in this High Voltage Energy Storage Pack Instance.  Not Operational is used when the module is initializing or not able to function (e.g. internal module level monitors have failed...";
CM_ SG_ 2364697086 Hvsp12Mdl14OprtnlStts "HVESP12 Module 14 Operational Status: Operational Status of Module 14 in this High Voltage Energy Storage Pack Instance.  Not Operational is used when the module is initializing or not able to function (e.g. internal module level monitors have failed...";
CM_ SG_ 2364697086 Hvsp12Mdl15OprtnlStts "HVESP12 Module 15 Operational Status: Operational Status of Module 15 in this High Voltage Energy Storage Pack Instance.  Not Operational is used when the module is initializing or not able to function (e.g. internal module level monitors have failed...";
CM_ SG_ 2364697086 Hvsp12Mdl16OprtnlStts "HVESP12 Module 16 Operational Status: Operational Status of Module 16 in this High Voltage Energy Storage Pack Instance.  Not Operational is used when the module is initializing or not able to function (e.g. internal module level monitors have failed...";
CM_ SG_ 2364697086 Hvsp12Mdl17OprtnlStts "HVESP12 Module 17 Operational Status: Operational Status of Module 17 in this High Voltage Energy Storage Pack Instance.  Not Operational is used when the module is initializing or not able to function (e.g. internal module level monitors have failed...";
CM_ SG_ 2364697086 Hvsp12Mdl18OprtnlStts "HVESP12 Module 18 Operational Status: Operational Status of Module 18 in this High Voltage Energy Storage Pack Instance.  Not Operational is used when the module is initializing or not able to function (e.g. internal module level monitors have failed...";
CM_ SG_ 2364697086 Hvsp12Mdl19OprtnlStts "HVESP12 Module 19 Operational Status: Operational Status of Module 19 in this High Voltage Energy Storage Pack Instance.  Not Operational is used when the module is initializing or not able to function (e.g. internal module level monitors have failed...";
CM_ SG_ 2364697086 Hvsp12Mdl20OprtnlStts "HVESP12 Module 20 Operational Status: Operational Status of Module 20 in this High Voltage Energy Storage Pack Instance.  Not Operational is used when the module is initializing or not able to function (e.g. internal module level monitors have failed...";
CM_ SG_ 2364697086 Hvsp12Mdl21OprtnlStts "HVESP12 Module 21 Operational Status: Operational Status of Module 21 in this High Voltage Energy Storage Pack Instance.  Not Operational is used when the module is initializing or not able to function (e.g. internal module level monitors have failed...";
CM_ SG_ 2364697086 Hvsp12Mdl22OprtnlStts "HVESP12 Module 22 Operational Status: Operational Status of Module 22 in this High Voltage Energy Storage Pack Instance.  Not Operational is used when the module is initializing or not able to function (e.g. internal module level monitors have failed...";
CM_ SG_ 2364697086 Hvsp12Mdl23OprtnlStts "HVESP12 Module 23 Operational Status: Operational Status of Module 23 in this High Voltage Energy Storage Pack Instance.  Not Operational is used when the module is initializing or not able to function (e.g. internal module level monitors have failed...";
CM_ SG_ 2364697086 Hvsp12Mdl24OprtnlStts "HVESP12 Module 24 Operational Status: Operational Status of Module 24 in this High Voltage Energy Storage Pack Instance.  Not Operational is used when the module is initializing or not able to function (e.g. internal module level monitors have failed...";
CM_ SG_ 2364697086 Hvsp12Mdl25OprtnlStts "HVESP12 Module 25 Operational Status: Operational Status of Module 25 in this High Voltage Energy Storage Pack Instance.  Not Operational is used when the module is initializing or not able to function (e.g. internal module level monitors have failed...";
CM_ SG_ 2364697086 Hvsp12Mdl26OprtnlStts "HVESP12 Module 26 Operational Status: Operational Status of Module 26 in this High Voltage Energy Storage Pack Instance.  Not Operational is used when the module is initializing or not able to function (e.g. internal module level monitors have failed...";
CM_ SG_ 2364697086 Hvsp12Mdl27OprtnlStts "HVESP12 Module 27 Operational Status: Operational Status of Module 27 in this High Voltage Energy Storage Pack Instance.  Not Operational is used when the module is initializing or not able to function (e.g. internal module level monitors have failed...";
CM_ SG_ 2364697086 Hvsp12Mdl28OprtnlStts "HVESP12 Module 28 Operational Status: Operational Status of Module 28 in this High Voltage Energy Storage Pack Instance.  Not Operational is used when the module is initializing or not able to function (e.g. internal module level monitors have failed...";
CM_ SG_ 2364697086 Hvsp12Mdl29OprtnlStts "HVESP12 Module 29 Operational Status: Operational Status of Module 29 in this High Voltage Energy Storage Pack Instance.  Not Operational is used when the module is initializing or not able to function (e.g. internal module level monitors have failed...";
CM_ SG_ 2364697086 Hvsp12Mdl30OprtnlStts "HVESP12 Module 30 Operational Status: Operational Status of Module 30 in this High Voltage Energy Storage Pack Instance.  Not Operational is used when the module is initializing or not able to function (e.g. internal module level monitors have failed...";
CM_ SG_ 2364697086 Hvsp12Mdl31OprtnlStts "HVESP12 Module 31 Operational Status: Operational Status of Module 31 in this High Voltage Energy Storage Pack Instance.  Not Operational is used when the module is initializing or not able to function (e.g. internal module level monitors have failed...";
CM_ SG_ 2364697086 Hvsp12Mdl32OprtnlStts "HVESP12 Module 32 Operational Status: Operational Status of Module 32 in this High Voltage Energy Storage Pack Instance.  Not Operational is used when the module is initializing or not able to function (e.g. internal module level monitors have failed...";
CM_ BO_ 2364697342 "High Voltage Energy Storage Pack 12 Thermal Management System Status 1";
CM_ SG_ 2364697342 Hvsp12ThrmlMngmntSstmSlInptPwr "HVESP12 Thermal Management System SLI Input Power: This is the low-voltage power consumed by this HVES Thermal Management System (TMS).This parameter is for one of multiple packs in an HVESS.  If there is only one pack in the system, the HVESS parame...";
CM_ SG_ 2364697342 Hvsp12TMtSstHVtIptPw "HVESP12 Thermal Management System High-Voltage Input Power: This is the high-voltage power consumed by this HVES Thermal Management System (TMS).This parameter is for one of multiple packs in an HVESS.  If there is only one pack in the system, the HV...";
CM_ SG_ 2364697342 Hvsp12ThrmlMngmntSstmCmprssrSpd "HVESP12 Thermal Management System Compressor Speed: When this High Voltage Energy Storage Pack Thermal Management System is equipped with an active cooling system (e.g. air conditioner), this is the Compressor Speed.This parameter is for one of multi...";
CM_ SG_ 2364697342 Hvsp12ThrmlMngmntSstmRltvHmdt "HVESP12 Thermal Management System Relative Humidty: When this High Voltage Energy Storage Pack Thermal Management System is equipped with a relative humidity sensor, this is the  measured Relative Humidity.This parameter is for one of multiple packs ...";
CM_ SG_ 2364697342 Hvsp12ThrmlMngmntSstmHtrStts "HVESP12 Thermal Management System Heater Status: The state of this High Voltage Energy Storage Pack heaterThis parameter is for one of multiple packs in an HVESS.  If there is only one pack in the system, the HVESS parameters should be used. If there...";
CM_ SG_ 2364697342 Hvsp12ThrmlMngmntSstmHvlStts "HVESP12 Thermal Management System HVIL Status: In multiple HVES configurations, this is the status of the High Voltage Interlock Loop from the viewpoint of this Thermal Management System.00b = HVIL Closed01b = HVIL Open10b = Error11b = Not AvailableT...";
CM_ SG_ 2364697342 Hvsp12ThrmlMngmntSstmMd "HVESP12 Thermal Management System Mode: Indicates the operating mode of the Thermal Management System.  The heat transfer medium may be (e.g. liquid or air).  The cooling system may be fans, liquid coolant, or a combination of mediums.  The system ma...";
CM_ SG_ 2364697342 Hvsp12ThrmlMngmntSstmClntLvl "HVESP12 Thermal Management System Coolant Level: Indicates the coolant level in this HVES Thermal Management System (TMS).This parameter is for one of multiple packs in an HVESS.  If there is only one pack in the system, the HVESS parameters should b...";
CM_ BO_ 2364697598 "High Voltage Energy Storage Pack 12 Data 8";
CM_ SG_ 2364697598 Hvsp12HghstCllVltgMdlNmr "HVESP12 Highest Cell Voltage Module Number: Identifies the location of the module containing SPN 15439 (HVESP12 Highest Cell Voltage).This parameter is for one of multiple packs in an HVESS. If there is only one pack in the system, the HVESS paramete...";
CM_ SG_ 2364697598 Hvsp12HghstCllVltgCllNmr "HVESP12 Highest Cell Voltage Cell Number: Identifies the location of SPN 15439 (HVESP12 Highest Cell Voltage) within SPN 15519 (HVESP12 Highest Cell Voltage Module Number).This parameter is for one of multiple packs in an HVESS. If there is only one ...";
CM_ SG_ 2364697598 Hvsp12LwstCllVltgMdlNmr "HVESP12 Lowest Cell Voltage Module Number: Identifies the location of the module containing SPN 15440 (HVESP12 Lowest Cell Voltage).This parameter is for one of multiple packs in an HVESS. If there is only one pack in the system, the HVESS parameters...";
CM_ SG_ 2364697598 Hvsp12LwstCllVltgCllNmr "HVESP12 Lowest Cell Voltage Cell Number: Identifies the location of SPN 15440 (HVESP12 Lowest Cell Voltage) within SPN 15521 (HVESP12 Lowest Cell Voltage Module Number).This parameter is for one of multiple packs in an HVESS. If there is only one pac...";
CM_ SG_ 2364697598 Hvesp12AverageCellVoltage "HVESP12 Average Cell Voltage: The average cell voltage in this High Voltage Energy Storage Pack instance.This parameter is for one of multiple packs in an HVESS.  If there is only one pack in the system, the HVESS parameters should be used. If there ...";
CM_ BO_ 2364697854 "High Voltage Energy Storage Pack 12 Data 9";
CM_ SG_ 2364697854 Hvsp12HghstCllTmprtrMdlNmr "HVESP12 Highest Cell Temperature Module Number: Identifies the location of the module containing SPN 15442 (HVESP12 Highest Cell Temperature).This parameter is for one of multiple packs in an HVESS. If there is only one pack in the system, the HVESS ...";
CM_ SG_ 2364697854 Hvsp12HghstCllTmprtrCllNmr "HVESP12 Highest Cell Temperature Cell Number: Identifies the location of SPN 15442 (HVESP12 Highest Cell Temperature) within SPN 15524 (HVESP12 Highest Cell Temperature Module Number).This parameter is for one of multiple packs in an HVESS. If there ...";
CM_ SG_ 2364697854 Hvsp12LwstCllTmprtrMdlNmr "HVESP12 Lowest Cell Temperature Module Number: Identifies the location of the module containing SPN 15443 (HVESP12 Lowest Cell Temperature).This parameter is for one of multiple packs in an HVESS. If there is only one pack in the system, the HVESS pa...";
CM_ SG_ 2364697854 Hvsp12LwstCllTmprtrCllNmr "HVESP12 Lowest Cell Temperature Cell Number: Identifies the location of SPN 15443 (HVESP12 Lowest Cell Temperature) within SPN 15526 (HVESP12 Lowest Cell Temperature Module Number).This parameter is for one of multiple packs in an HVESS. If there is ...";
CM_ SG_ 2364697854 Hvess12ThermalEventDetected "HVESS12 Thermal Event Detected: A sensor has detected the presence of a thermal event at or near High Voltage Energy Storage Pack instance.00b = No Thermal Event Detected01b = Thermal Event Detected10b = Error11b = Not availableThis parameter is for ...";
CM_ SG_ 2364697854 Hvsp12Dt9EmdddIntgrtSpprt "HVESP12 Data 9 Embedded Integrity Support: Indicates SPN 23009 (HVESP12 Data 9 CRC) and SPN 23008 (HVESP12 Data 9 Counter) are supported by the sender.00b = Embedded CRC and Counter are supported by the sender01b = Protection is provided using an ext...";
CM_ SG_ 2364697854 Hvesp12Data9Counter "HVESP12 Data 9 Counter: The message counter is used to detect situations where the transmitting ECU malfunction repeats the same frame all the time. The receiver of the information may use the counter parameter to detect this situation. The transmitt...";
CM_ SG_ 2364697854 Hvesp12Data9Crc "HVESP12 Data 9 CRC: The CRC is defined as follows: - Length: 8 bits- Polynomial: x^8+x^5+x^3+x^2+x+1- Initial Value: FFh- Input Data Reflection: Not reflected- Result Data Reflection: Not reflected- XOR value: FFh SAE makes no claim of the functional...";
CM_ BO_ 2364698110 "High Voltage Energy Storage Pack 12 Data 10";
CM_ SG_ 2364698110 Hvsp12HghstCllSttOfChrgMdlNmr "HVESP12 Highest Cell State of Charge Module Number: Identifies the location of the module containing SPN 15452 (HVESP12 Highest Cell State of Charge).This parameter is for one of multiple packs in an HVESS. If there is only one pack in the system, th...";
CM_ SG_ 2364698110 Hvsp12HghstCllSttOfChrgCllNmr "HVESP12 Highest Cell State of Charge Cell Number: Identifies the location of SPN 15452 (HVESP12 Highest Cell State of Charge) within SPN 15528 (HVESP12 Highest Cell State of Charge Module Number).This parameter is for one of multiple packs in an HVES...";
CM_ SG_ 2364698110 Hvsp12LwstCllSttOfChrgMdlNmr "HVESP12 Lowest Cell State of Charge Module Number: Identifies the location of the module containing SPN 15451 (HVESP12 Lowest Cell State of Charge).This parameter is for one of multiple packs in an HVESS. If there is only one pack in the system, the ...";
CM_ SG_ 2364698110 Hvsp12LwstCllSttOfChrgCllNmr "HVESP12 Lowest Cell State of Charge Cell Number: Identifies the location of SPN 15451 (HVESP12 Lowest Cell State of Charge) within SPN 15530 (HVESP12 Lowest Cell State of Charge Module Number).This parameter is for one of multiple packs in an HVESS. ...";
CM_ SG_ 2364698110 Hvsp12HghVltgBsAtvIsltnTstRslts "HVESP12 High-Voltage Bus Active Isolation Test Results: The isolation resistance expressed in Ohms per Volt that resulted from the High-Voltage Bus Active Isolation Test.See SPN 15464 (HVESP12 High-Voltage Bus Active Isolation Test Status) for test s...";
CM_ SG_ 2364698110 Hvsp12HVtBsPssvIstTstRsts "HVESP12 High-Voltage Bus Passive Isolation Test Results: The isolation resistance expressed in Ohms per Volt that resulted from the High-Voltage Bus Passive Isolation Test.See SPN 15465 (HVESP12 High-Voltage Bus Passive Isolation Test Status) for tes...";
CM_ BO_ 2364698366 "High Voltage Energy Storage Pack 12 Data 11";
CM_ SG_ 2364698366 Hvsp12BsVltgNgtvTChsssGrndVltg "HVESP12 Bus Voltage Negative to Chassis Ground Voltage: Voltage difference between the most negative terminal of the HVES battery and chassis measured on the hybrid or EV system bus side (not the battery side) of any HVES contained output contactor. ...";
CM_ SG_ 2364698366 Hvsp12VltgLvlNgtvTChsssGrndVltg "HVESP12 Voltage Level Negative to Chassis Ground Voltage: Voltage difference between the most negative terminal of the HVES battery and chassis measured at the battery side of any HVES contained output contactor.  This voltage may be used for system ...";
CM_ SG_ 2364698366 Hvesp12ActualChargeRate "HVESP12 Actual Charge Rate: This signal represents the actual present charge rate of this High Voltage Energy Storage Pack instance.This parameter is for one of multiple packs in an HVESS. If there is only one pack in the system, the HVESS parameters...";
CM_ BO_ 2364698622 "High Voltage Energy Storage Pack 13 Status 2";
CM_ SG_ 2364698622 Hvsp13DshrgPwrLmtDTSttOfChrg "HVESP13 Discharge Power Limit Due to State of Charge: Indicates whether or not discharge power of this HVES instance is being limited due to state of charge.This parameter is for one of multiple packs in an HVESS.  If there is only one pack in the sy...";
CM_ SG_ 2364698622 Hvsp13DshrgPwrLmtDTBttrTmprtr "HVESP13 Discharge Power Limit Due to Battery Temperature: Indicates whether or not discharge power of this HVES instance is being limited due to battery temperature.This parameter is for one of multiple packs in an HVESS.  If there is only one pack i...";
CM_ SG_ 2364698622 Hvsp13DsPwLtDTBttDstCdt "HVESP13 Discharge Power Limit Due to Battery Diagnostic Condition: Indicates whether or not discharge power of this HVES instance is being limited due to a battery diagnostic condition.This parameter is for one of multiple packs in an HVESS.  If ther...";
CM_ SG_ 2364698622 Hvsp13DsPwLtDTBttOCVt "HVESP13 Discharge Power Limit Due to Battery or Cell Voltage: Indicates whether or not discharge power of this HVES instance is being limited due to a battery or cell voltage level.This parameter is for one of multiple packs in an HVESS.  If there is...";
CM_ SG_ 2364698622 Hvsp13DshrgPwrLmtDTBttrCrrnt "HVESP13 Discharge Power Limit Due to Battery Current: Indicates whether or not discharge power of this HVES instance is being limited due to battery current.This parameter is for one of multiple packs in an HVESS.  If there is only one pack in the sy...";
CM_ SG_ 2364698622 Hvsp13DshrgPwrLmtDTAnUndfndCs "HVESP13 Discharge Power Limit Due to an Undefined Cause: Indicates whether or not discharge power of this HVES instance is being limited due to an undefined cause.This parameter is for one of multiple packs in an HVESS.  If there is only one pack in ...";
CM_ SG_ 2364698622 Hvsp13ChrgPwrLmtDTSttOfChrg "HVESP13 Charge Power Limit Due to State of Charge: Indicates whether or not charge power of this HVES instance is being limited due to state of charge.This parameter is for one of multiple packs in an HVESS.  If there is only one pack in the system, ...";
CM_ SG_ 2364698622 Hvsp13ChrgPwrLmtDTBttrTmprtr "HVESP13 Charge Power Limit Due to Battery Temperature: Indicates whether or not charge power of this HVES instance is being limited due to battery temperature.This parameter is for one of multiple packs in an HVESS.  If there is only one pack in the ...";
CM_ SG_ 2364698622 Hvsp13CPwLtDTBttDstCdt "HVESP13 Charge Power Limit Due to Battery Diagnostic Condition: Indicates whether or not charge power of this HVES instance is being limited due to a battery diagnostic condition.This parameter is for one of multiple packs in an HVESS.  If there is o...";
CM_ SG_ 2364698622 Hvsp13ChrgPwrLmtDTBttrOrCllVltg "HVESP13 Charge Power Limit Due to Battery or Cell Voltage: Indicates whether or not charge power of this HVES instance is being limited due to a battery or cell voltage level.This parameter is for one of multiple packs in an HVESS.  If there is only ...";
CM_ SG_ 2364698622 Hvsp13ChrgPwrLmtDTBttrCrrnt "HVESP13 Charge Power Limit Due to Battery Current: Indicates whether or not charge power of this HVES instance is being limited due to battery current.This parameter is for one of multiple packs in an HVESS.  If there is only one pack in the system, ...";
CM_ SG_ 2364698622 Hvsp13ChrgPwrLmtDTAnUndfndCs "HVESP13 Charge Power Limit Due to an Undefined Cause: Indicates whether or not charge power of this HVES instance is being limited due to an undefined cause.This parameter is for one of multiple packs in an HVESS.  If there is only one pack in the sy...";
CM_ BO_ 2364698878 "High Voltage Energy Storage Pack 13 Data 1";
CM_ SG_ 2364698878 Hvesp13AvailableDischargePower "HVESP13 Available Discharge Power: The rate at which this High Voltage Energy Storage Pack instance can currently provide energy for propulsion or other uses.This parameter is for one of multiple packs in an HVESS.  If there is only one pack in the s...";
CM_ SG_ 2364698878 Hvesp13AvailableChargePower "HVESP13 Available Charge Power: The rate at which this High Voltage Energy Storage Pack instance can currently receive energy from a regenerative or recharging system.This parameter is for one of multiple packs in an HVESS.  If there is only one pack...";
CM_ SG_ 2364698878 Hvesp13VoltageLevel "HVESP13 Voltage Level: The voltage level of this High Voltage Energy Storage Pack instance. This parameter should be synchronized with SPN 15579 (HVESP13 Current) such that a realized power value can be calculated. If the HVES component physically co...";
CM_ SG_ 2364698878 Hvesp13Current "HVESP13 Current: The current in or out of this High Voltage Energy Storage Pack instance. This parameter should be synchronized with SPN 15578 (HVESP13 Voltage Level) such that a realized power value can be calculated. This parameter is defined from ...";
CM_ BO_ 2364699134 "High Voltage Energy Storage Pack 13 Data 2";
CM_ SG_ 2364699134 Hvesp13FastUpdateStateOfCharge "HVESP13 Fast Update State of Charge: Indicates this High Voltage Energy Storage Pack instance state of charge. 0% means no charge remaining, 100% means the system is fully charged in terms of physical limits of this energy storage pack instance. Acce...";
CM_ SG_ 2364699134 Hvesp13HighestCellVoltage "HVESP13 Highest Cell Voltage: The highest voltage level reported by any cell in this High Voltage Energy Storage Pack instance. If a single voltage sensor covers more than one cell, the value in this parameter is for the smallest group of cells measu...";
CM_ SG_ 2364699134 Hvesp13LowestCellVoltage "HVESP13 Lowest Cell Voltage: The lowest voltage level reported by any cell in this High Voltage Energy Storage Pack instance. If a single voltage sensor covers more than one cell, the value in this parameter is for the smallest group of cells measure...";
CM_ SG_ 2364699134 Hvsp13CllVltgDffrntlStts "HVESP13 Cell Voltage Differential Status: Indicates whether or not the differential between the highest and lowest cell voltages are within acceptable limits, according to this High Voltage Energy Storage Pack instance. The actual voltage differentia...";
CM_ BO_ 2364699390 "High Voltage Energy Storage Pack 13 Data 3";
CM_ SG_ 2364699390 Hvesp13HighestCellTemperature "HVESP13 Highest Cell Temperature: The highest temperature level reported by any cell in this High Voltage Energy Storage Pack instance. If a single temperature sensor covers more than one cell, the value in this parameter is for the smallest group of...";
CM_ SG_ 2364699390 Hvesp13LowestCellTemperature "HVESP13 Lowest Cell Temperature: The lowest temperature level reported by any cell in this High Voltage Energy Storage Pack instance. If a single temperature sensor covers more than one cell, the value in this parameter is for the smallest group of c...";
CM_ SG_ 2364699390 Hvesp13AverageCellTemperature "HVESP13 Average Cell Temperature: The average temperature level of all cells in this High Voltage Energy Storage Pack instance.This parameter is for one of multiple packs in an HVESS.  If there is only one pack in the system, the HVESS parameters sho...";
CM_ SG_ 2364699390 Hvsp13CllTmprtrDffrntlStts "HVESP13 Cell Temperature Differential Status: Indicates whether or not the differential between the highest and lowest cell temperatures are within acceptable limits per this High Voltage Energy Storage Pack instance. The actual temperature different...";
CM_ BO_ 2364699646 "High Voltage Energy Storage Pack 13 Data 4";
CM_ SG_ 2364699646 Hvesp13DischargeCapacity "HVESP13 Discharge Capacity: The amount of stored electrical charge in this High Voltage Energy Storage Pack instance that is available for use by the hybrid or EV system, i.e. 'how full is the tank'. See SPN 15618 (HVESP13 Discharge Energy Capacity) ...";
CM_ SG_ 2364699646 Hvesp13ChargeCapacity "HVESP13 Charge Capacity: The amount of unused electrical charge storage in this High Voltage Energy Storage Pack instance that is available to be filled by charging, i.e. 'how much empty space is remaining in the tank'. See SPN 15619 (HVESP13 Charge ...";
CM_ SG_ 2364699646 Hvesp13CellBalancingCount "HVESP13 Cell Balancing Count: The number of cells that are currently being balanced in this High Voltage Energy Storage Pack instance.This parameter is for one of multiple packs in an HVESS.  If there is only one pack in the system, the HVESS paramet...";
CM_ BO_ 2364699902 "High Voltage Energy Storage Pack 13 Data 5";
CM_ SG_ 2364699902 Hvesp13LowestCellStateOfCharge "HVESP13 Lowest Cell State of Charge: Indicates the state of charge of the lowest-charged cell in this High Voltage Energy Storage Pack instance. 0% means no charge remaining, 100% means the cell is fully charged. If a single state of charge value cov...";
CM_ SG_ 2364699902 Hvesp13HighestCellStateOfCharge "HVESP13 Highest Cell State of Charge: Indicates the state of charge of the highest-charged cell in this High Voltage Energy Storage Pack instance. 0% means no charge remaining, 100% means the cell is fully charged. If a single state of charge value c...";
CM_ SG_ 2364699902 Hvsp13MxmmInstntnsDshrgCrrntLmt "HVESP13 Maximum Instantaneous Discharge Current Limit: The maximum instantaneous current flow limit out of this High Voltage Energy Storage Pack instance. This parameter is defined from the high voltage energy storage pack's point of view and should ...";
CM_ SG_ 2364699902 Hvsp13MxmmInstntnsChrgCrrntLmt "HVESP13 Maximum Instantaneous Charge Current Limit: The maximum instantaneous current flow limit into this High Voltage Energy Storage Pack instance. This parameter is defined from the high voltage energy storage pack's point of view and should refle...";
CM_ BO_ 2364700158 "High Voltage Energy Storage Pack 13 Data 6";
CM_ SG_ 2364700158 Hvesp13BusVoltage "HVESP13 Bus Voltage: The voltage level of the high voltage bus, as measured by this High Voltage Energy Storage Pack instance on the bus side (not the battery side) of its contactors.This parameter is for one of multiple packs in an HVESS.  If there ...";
CM_ SG_ 2364700158 Hvesp13IgnitionVoltage "HVESP13 Ignition Voltage: The voltage level at the ignition input of this High Voltage Energy Storage Pack controller.This parameter is for one of multiple packs in an HVESS.  If there is only one pack in the system, the HVESS parameters should be us...";
CM_ SG_ 2364700158 Hvesp13IntakeCoolantTemperature "HVESP13 Intake Coolant Temperature: The temperature of liquid coolant as it enters this High Voltage Energy Storage Pack instance.This parameter is for one of multiple packs in an HVESS.  If there is only one pack in the system, the HVESS parameters ...";
CM_ SG_ 2364700158 Hvesp13OutletCoolantTemperature "HVESP13 Outlet Coolant Temperature: The temperature of liquid coolant as it exits this High Voltage Energy Storage Pack instance.This parameter is for one of multiple packs in an HVESS.  If there is only one pack in the system, the HVESS parameters s...";
CM_ SG_ 2364700158 Hvesp13ElectronicsTemperature "HVESP13 Electronics Temperature: The temperature of the electronics or control modules in this High Voltage Energy Storage Pack instance.  If there are multiple temperature sensors then this parameter would be set to the maximum sensor reading.This p...";
CM_ SG_ 2364700158 Hvesp13Temperature "HVESP13 Temperature: The temperature of this High Voltage Energy Storage Pack instance. The value may be determined from a unique sensor specifically for this purpose, or by aggregating various temperature sensor readings within the pack.This paramet...";
CM_ BO_ 2364700414 "High Voltage Energy Storage Pack 13 Status 1";
CM_ SG_ 2364700414 Hvsp13HghVltgBsPstvCnttrStt "HVESP13 High-Voltage Bus (Positive) Contactor State: Position of this High Voltage Energy Storage Pack instance positive side bus contactor.  When this contactor is closed, the positive side of this HVES instance is connected to the positive side of ...";
CM_ SG_ 2364700414 Hvsp13HghVltgBsNgtvCnttrStt "HVESP13 High-Voltage Bus (Negative) Contactor State: Position of this High Voltage Energy Storage Pack instance negative side bus contactor. When this contactor is closed, the negative side of this HVES instance is connected to the negative side of t...";
CM_ SG_ 2364700414 Hvsp13HghVltgBsDsnntFrwrnng "HVESP13 High-Voltage Bus Disconnect Forewarning: Indicates that this High Voltage Energy Storage Pack instance is about to disconnect from the high voltage bus due to unacceptable conditions.This parameter is for one of multiple packs in an HVESS. If...";
CM_ SG_ 2364700414 Hvsp13HghVltgBsPrChrgRlStt "HVESP13 High-Voltage Bus Pre-Charge Relay State: Position of the high-voltage bus contactor pre-charge relay.  When this relay is closed, this High Voltage Energy Storage Pack instance is bringing the high-voltage bus up to its operating level.This p...";
CM_ SG_ 2364700414 Hvsp13CntrOfPkCnttrStt "HVESP13 Center of Pack Contactor State: Position of the center high-voltage contactor. When this contactor is closed, the positive half of this High Voltage Energy Storage Pack instance is connected to the negative half. If a system controls the posi...";
CM_ SG_ 2364700414 Hvsp13HghVltgBsAtvIsltnTstStts "HVESP13 High-Voltage Bus Active Isolation Test Status: Status of the high-voltage bus electrical active isolation test as performed by this High Voltage Energy Storage Pack instance.This parameter is for one of multiple packs in an HVESS. If there is...";
CM_ SG_ 2364700414 Hvsp13HghVltgBsPssvIsltnTstStts "HVESP13 High-Voltage Bus Passive Isolation Test Status: Status of the high-voltage bus electrical passive isolation test as performed by this High Voltage Energy Storage Pack instance.This parameter is for one of multiple packs in an HVESS. If there ...";
CM_ SG_ 2364700414 Hvesp13HvilStatus "HVESP13 HVIL Status: Status of the High Voltage Interlock Loop from the viewpoint of this High Voltage Energy Storage Pack instance.This parameter is for one of multiple packs in an HVESS. If there is only one pack in the system, the HVESS parameters...";
CM_ SG_ 2364700414 Hvesp13InertiaSwitchStatus "HVESP13 Inertia Switch Status: Switch indicating that an impact has been sensed by this High Voltage Energy Storage Pack instance. The impact indication may require action by another controller, or by this HVES instance itself.  For example, a contro...";
CM_ SG_ 2364700414 Hvesp13StateOfChargeStatus "HVESP13 State of Charge Status: Status of this High Voltage Energy Storage Pack instance State of Charge (SOC).  Note:  A given HVES controller may not support all of the states.This parameter is for one of multiple packs in an HVESS.  If there is on...";
CM_ SG_ 2364700414 Hvesp13CellBalanceStatus "HVESP13 Cell Balance Status: Indicates whether or not the cells in this High Voltage Energy Storage Pack instance are balanced.This parameter is for one of multiple packs in an HVESS.  If there is only one pack in the system, the HVESS parameters sho...";
CM_ SG_ 2364700414 Hvesp13CellBalancingActive "HVESP13 Cell Balancing Active: Indicates whether or not the cells in this High Voltage Energy Storage Pack instance are currently being balanced.This parameter is for one of multiple packs in an HVESS.  If there is only one pack in the system, the HV...";
CM_ SG_ 2364700414 Hvesp13InternalChargerStatus "HVESP13 Internal Charger Status: Indicates that the charger in this HVES instance is on.  External chargers may use the External Energy Source Connection Status (SPN 7898) and related SPs.This parameter is for one of multiple packs in an HVESS. If th...";
CM_ SG_ 2364700414 Hvsp13HghVltgBsCnntnStts "HVESP13 High-Voltage Bus Connection Status: This parameter provides high level feedback on this High Voltage Energy Storage Pack instance high voltage bus connection. For specific contactor information, see SPN 15601 (HVESP13 High-Voltage Bus (Positi...";
CM_ SG_ 2364700414 Hvesp13OperationalStatus "HVESP13 Operational Status: Provides feedback on where this High Voltage Energy Storage Pack instance is in its operating spectrum, and includes feedback in response to the Operation Consent [i.e. SPN 15559 (HVESP13 Operation Consent)] and Power Down...";
CM_ SG_ 2364700414 Hvesp13Status1Counter "HVESP13 Status 1 Counter: The message counter is used to detect situations where the transmitting ECU malfunction repeats the same frame all the time. The receiver of the information may use the counter parameter to detect this situation. The transmi...";
CM_ SG_ 2364700414 Hvesp13Status1Crc "HVESP13 Status 1 CRC: The CRC is defined as follows: - Length: 8 bits- Polynomial: x^8+x^5+x^3+x^2+x+1- Initial Value: FFh- Input Data Reflection: Not reflected- Result Data Reflection: Not reflected- XOR value: FFh SAE makes no claim of the function...";
CM_ BO_ 2364700670 "High Voltage Energy Storage Pack 13 Data 7";
CM_ SG_ 2364700670 Hvesp13DischargeEnergyCapacity "HVESP13 Discharge Energy Capacity: The amount of stored electrical energy in this High Voltage Energy Storage Pack instance that is available for use by the hybrid or EV system, i.e. 'how full is the tank'. See SPN 15588 (HVESP13 Discharge Capacity) ...";
CM_ SG_ 2364700670 Hvesp13ChargeEnergyCapacity "HVESP13 Charge Energy Capacity: The amount of unused electrical energy storage available to be filled by charging this High Voltage Energy Storage Pack instance, i.e. 'how much empty space is remaining in the tank'. See SPN 15589 (HVESP13 Charge Capa...";
CM_ SG_ 2364700670 Hvsp13MxmmChrgVltgLmt "HVESP13 Maximum Charge Voltage Limit: The maximum voltage level not to be exceeded while charging this High Voltage Energy Storage Pack instance. If this parameter is not supported, the maximum charge voltage should be limited to SPN 15687 (HVESP13 R...";
CM_ BO_ 2364700926 "High Voltage Energy Storage Pack 13 Module Status 1";
CM_ SG_ 2364700926 Hvesp13Module1OperationalStatus "HVESP13 Module 1 Operational Status: Operational Status of Module 1 in this High Voltage Energy Storage Pack Instance.  Not Operational is used when the module is initializing or not able to function (e.g. internal module level monitors have failed)....";
CM_ SG_ 2364700926 Hvesp13Module2OperationalStatus "HVESP13 Module 2 Operational Status: Operational Status of Module 2 in this High Voltage Energy Storage Pack Instance.  Not Operational is used when the module is initializing or not able to function (e.g. internal module level monitors have failed)....";
CM_ SG_ 2364700926 Hvesp13Module3OperationalStatus "HVESP13 Module 3 Operational Status: Operational Status of Module 3 in this High Voltage Energy Storage Pack Instance.  Not Operational is used when the module is initializing or not able to function (e.g. internal module level monitors have failed)....";
CM_ SG_ 2364700926 Hvesp13Module4OperationalStatus "HVESP13 Module 4 Operational Status: Operational Status of Module 4 in this High Voltage Energy Storage Pack Instance.  Not Operational is used when the module is initializing or not able to function (e.g. internal module level monitors have failed)....";
CM_ SG_ 2364700926 Hvesp13Module5OperationalStatus "HVESP13 Module 5 Operational Status: Operational Status of Module 5 in this High Voltage Energy Storage Pack Instance.  Not Operational is used when the module is initializing or not able to function (e.g. internal module level monitors have failed)....";
CM_ SG_ 2364700926 Hvesp13Module6OperationalStatus "HVESP13 Module 6 Operational Status: Operational Status of Module 6 in this High Voltage Energy Storage Pack Instance.  Not Operational is used when the module is initializing or not able to function (e.g. internal module level monitors have failed)....";
CM_ SG_ 2364700926 Hvesp13Module7OperationalStatus "HVESP13 Module 7 Operational Status: Operational Status of Module 7 in this High Voltage Energy Storage Pack Instance.  Not Operational is used when the module is initializing or not able to function (e.g. internal module level monitors have failed)....";
CM_ SG_ 2364700926 Hvesp13Module8OperationalStatus "HVESP13 Module 8 Operational Status: Operational Status of Module 8 in this High Voltage Energy Storage Pack Instance.  Not Operational is used when the module is initializing or not able to function (e.g. internal module level monitors have failed)....";
CM_ SG_ 2364700926 Hvesp13Module9OperationalStatus "HVESP13 Module 9 Operational Status: Operational Status of Module 9 in this High Voltage Energy Storage Pack Instance.  Not Operational is used when the module is initializing or not able to function (e.g. internal module level monitors have failed)....";
CM_ SG_ 2364700926 Hvsp13Mdl10OprtnlStts "HVESP13 Module 10 Operational Status: Operational Status of Module 10 in this High Voltage Energy Storage Pack Instance.  Not Operational is used when the module is initializing or not able to function (e.g. internal module level monitors have failed...";
CM_ SG_ 2364700926 Hvsp13Mdl11OprtnlStts "HVESP13 Module 11 Operational Status: Operational Status of Module 11 in this High Voltage Energy Storage Pack Instance.  Not Operational is used when the module is initializing or not able to function (e.g. internal module level monitors have failed...";
CM_ SG_ 2364700926 Hvsp13Mdl12OprtnlStts "HVESP13 Module 12 Operational Status: Operational Status of Module 12 in this High Voltage Energy Storage Pack Instance.  Not Operational is used when the module is initializing or not able to function (e.g. internal module level monitors have failed...";
CM_ SG_ 2364700926 Hvsp13Mdl13OprtnlStts "HVESP13 Module 13 Operational Status: Operational Status of Module 13 in this High Voltage Energy Storage Pack Instance.  Not Operational is used when the module is initializing or not able to function (e.g. internal module level monitors have failed...";
CM_ SG_ 2364700926 Hvsp13Mdl14OprtnlStts "HVESP13 Module 14 Operational Status: Operational Status of Module 14 in this High Voltage Energy Storage Pack Instance.  Not Operational is used when the module is initializing or not able to function (e.g. internal module level monitors have failed...";
CM_ SG_ 2364700926 Hvsp13Mdl15OprtnlStts "HVESP13 Module 15 Operational Status: Operational Status of Module 15 in this High Voltage Energy Storage Pack Instance.  Not Operational is used when the module is initializing or not able to function (e.g. internal module level monitors have failed...";
CM_ SG_ 2364700926 Hvsp13Mdl16OprtnlStts "HVESP13 Module 16 Operational Status: Operational Status of Module 16 in this High Voltage Energy Storage Pack Instance.  Not Operational is used when the module is initializing or not able to function (e.g. internal module level monitors have failed...";
CM_ SG_ 2364700926 Hvsp13Mdl17OprtnlStts "HVESP13 Module 17 Operational Status: Operational Status of Module 17 in this High Voltage Energy Storage Pack Instance.  Not Operational is used when the module is initializing or not able to function (e.g. internal module level monitors have failed...";
CM_ SG_ 2364700926 Hvsp13Mdl18OprtnlStts "HVESP13 Module 18 Operational Status: Operational Status of Module 18 in this High Voltage Energy Storage Pack Instance.  Not Operational is used when the module is initializing or not able to function (e.g. internal module level monitors have failed...";
CM_ SG_ 2364700926 Hvsp13Mdl19OprtnlStts "HVESP13 Module 19 Operational Status: Operational Status of Module 19 in this High Voltage Energy Storage Pack Instance.  Not Operational is used when the module is initializing or not able to function (e.g. internal module level monitors have failed...";
CM_ SG_ 2364700926 Hvsp13Mdl20OprtnlStts "HVESP13 Module 20 Operational Status: Operational Status of Module 20 in this High Voltage Energy Storage Pack Instance.  Not Operational is used when the module is initializing or not able to function (e.g. internal module level monitors have failed...";
CM_ SG_ 2364700926 Hvsp13Mdl21OprtnlStts "HVESP13 Module 21 Operational Status: Operational Status of Module 21 in this High Voltage Energy Storage Pack Instance.  Not Operational is used when the module is initializing or not able to function (e.g. internal module level monitors have failed...";
CM_ SG_ 2364700926 Hvsp13Mdl22OprtnlStts "HVESP13 Module 22 Operational Status: Operational Status of Module 22 in this High Voltage Energy Storage Pack Instance.  Not Operational is used when the module is initializing or not able to function (e.g. internal module level monitors have failed...";
CM_ SG_ 2364700926 Hvsp13Mdl23OprtnlStts "HVESP13 Module 23 Operational Status: Operational Status of Module 23 in this High Voltage Energy Storage Pack Instance.  Not Operational is used when the module is initializing or not able to function (e.g. internal module level monitors have failed...";
CM_ SG_ 2364700926 Hvsp13Mdl24OprtnlStts "HVESP13 Module 24 Operational Status: Operational Status of Module 24 in this High Voltage Energy Storage Pack Instance.  Not Operational is used when the module is initializing or not able to function (e.g. internal module level monitors have failed...";
CM_ SG_ 2364700926 Hvsp13Mdl25OprtnlStts "HVESP13 Module 25 Operational Status: Operational Status of Module 25 in this High Voltage Energy Storage Pack Instance.  Not Operational is used when the module is initializing or not able to function (e.g. internal module level monitors have failed...";
CM_ SG_ 2364700926 Hvsp13Mdl26OprtnlStts "HVESP13 Module 26 Operational Status: Operational Status of Module 26 in this High Voltage Energy Storage Pack Instance.  Not Operational is used when the module is initializing or not able to function (e.g. internal module level monitors have failed...";
CM_ SG_ 2364700926 Hvsp13Mdl27OprtnlStts "HVESP13 Module 27 Operational Status: Operational Status of Module 27 in this High Voltage Energy Storage Pack Instance.  Not Operational is used when the module is initializing or not able to function (e.g. internal module level monitors have failed...";
CM_ SG_ 2364700926 Hvsp13Mdl28OprtnlStts "HVESP13 Module 28 Operational Status: Operational Status of Module 28 in this High Voltage Energy Storage Pack Instance.  Not Operational is used when the module is initializing or not able to function (e.g. internal module level monitors have failed...";
CM_ SG_ 2364700926 Hvsp13Mdl29OprtnlStts "HVESP13 Module 29 Operational Status: Operational Status of Module 29 in this High Voltage Energy Storage Pack Instance.  Not Operational is used when the module is initializing or not able to function (e.g. internal module level monitors have failed...";
CM_ SG_ 2364700926 Hvsp13Mdl30OprtnlStts "HVESP13 Module 30 Operational Status: Operational Status of Module 30 in this High Voltage Energy Storage Pack Instance.  Not Operational is used when the module is initializing or not able to function (e.g. internal module level monitors have failed...";
CM_ SG_ 2364700926 Hvsp13Mdl31OprtnlStts "HVESP13 Module 31 Operational Status: Operational Status of Module 31 in this High Voltage Energy Storage Pack Instance.  Not Operational is used when the module is initializing or not able to function (e.g. internal module level monitors have failed...";
CM_ SG_ 2364700926 Hvsp13Mdl32OprtnlStts "HVESP13 Module 32 Operational Status: Operational Status of Module 32 in this High Voltage Energy Storage Pack Instance.  Not Operational is used when the module is initializing or not able to function (e.g. internal module level monitors have failed...";
CM_ BO_ 2364701182 "High Voltage Energy Storage Pack 13 Thermal Management System Status 1";
CM_ SG_ 2364701182 Hvsp13ThrmlMngmntSstmSlInptPwr "HVESP13 Thermal Management System SLI Input Power: This is the low-voltage power consumed by this HVES Thermal Management System (TMS).This parameter is for one of multiple packs in an HVESS.  If there is only one pack in the system, the HVESS parame...";
CM_ SG_ 2364701182 Hvsp13TMtSstHVtIptPw "HVESP13 Thermal Management System High-Voltage Input Power: This is the high-voltage power consumed by this HVES Thermal Management System (TMS).This parameter is for one of multiple packs in an HVESS.  If there is only one pack in the system, the HV...";
CM_ SG_ 2364701182 Hvsp13ThrmlMngmntSstmCmprssrSpd "HVESP13 Thermal Management System Compressor Speed: When this High Voltage Energy Storage Pack Thermal Management System is equipped with an active cooling system (e.g. air conditioner), this is the Compressor Speed.This parameter is for one of multi...";
CM_ SG_ 2364701182 Hvsp13ThrmlMngmntSstmRltvHmdt "HVESP13 Thermal Management System Relative Humidty: When this High Voltage Energy Storage Pack Thermal Management System is equipped with a relative humidity sensor, this is the  measured Relative Humidity.This parameter is for one of multiple packs ...";
CM_ SG_ 2364701182 Hvsp13ThrmlMngmntSstmHtrStts "HVESP13 Thermal Management System Heater Status: The state of this High Voltage Energy Storage Pack heaterThis parameter is for one of multiple packs in an HVESS.  If there is only one pack in the system, the HVESS parameters should be used. If there...";
CM_ SG_ 2364701182 Hvsp13ThrmlMngmntSstmHvlStts "HVESP13 Thermal Management System HVIL Status: In multiple HVES configurations, this is the status of the High Voltage Interlock Loop from the viewpoint of this Thermal Management System.00b = HVIL Closed01b = HVIL Open10b = Error11b = Not AvailableT...";
CM_ SG_ 2364701182 Hvsp13ThrmlMngmntSstmMd "HVESP13 Thermal Management System Mode: Indicates the operating mode of the Thermal Management System.  The heat transfer medium may be (e.g. liquid or air).  The cooling system may be fans, liquid coolant, or a combination of mediums.  The system ma...";
CM_ SG_ 2364701182 Hvsp13ThrmlMngmntSstmClntLvl "HVESP13 Thermal Management System Coolant Level: Indicates the coolant level in this HVES Thermal Management System (TMS).This parameter is for one of multiple packs in an HVESS.  If there is only one pack in the system, the HVESS parameters should b...";
CM_ BO_ 2364701438 "High Voltage Energy Storage Pack 13 Data 8";
CM_ SG_ 2364701438 Hvsp13HghstCllVltgMdlNmr "HVESP13 Highest Cell Voltage Module Number: Identifies the location of the module containing SPN 15581 (HVESP13 Highest Cell Voltage).This parameter is for one of multiple packs in an HVESS. If there is only one pack in the system, the HVESS paramete...";
CM_ SG_ 2364701438 Hvsp13HghstCllVltgCllNmr "HVESP13 Highest Cell Voltage Cell Number: Identifies the location of SPN 15581 (HVESP13 Highest Cell Voltage) within SPN 15661 (HVESP13 Highest Cell Voltage Module Number).This parameter is for one of multiple packs in an HVESS. If there is only one ...";
CM_ SG_ 2364701438 Hvsp13LwstCllVltgMdlNmr "HVESP13 Lowest Cell Voltage Module Number: Identifies the location of the module containing SPN 15582 (HVESP13 Lowest Cell Voltage).This parameter is for one of multiple packs in an HVESS. If there is only one pack in the system, the HVESS parameters...";
CM_ SG_ 2364701438 Hvsp13LwstCllVltgCllNmr "HVESP13 Lowest Cell Voltage Cell Number: Identifies the location of SPN 15582 (HVESP13 Lowest Cell Voltage) within SPN 15663 (HVESP13 Lowest Cell Voltage Module Number).This parameter is for one of multiple packs in an HVESS. If there is only one pac...";
CM_ SG_ 2364701438 Hvesp13AverageCellVoltage "HVESP13 Average Cell Voltage: The average cell voltage in this High Voltage Energy Storage Pack instance.This parameter is for one of multiple packs in an HVESS.  If there is only one pack in the system, the HVESS parameters should be used. If there ...";
CM_ BO_ 2364701694 "High Voltage Energy Storage Pack 13 Data 9";
CM_ SG_ 2364701694 Hvsp13HghstCllTmprtrMdlNmr "HVESP13 Highest Cell Temperature Module Number: Identifies the location of the module containing SPN 15584 (HVESP13 Highest Cell Temperature).This parameter is for one of multiple packs in an HVESS. If there is only one pack in the system, the HVESS ...";
CM_ SG_ 2364701694 Hvsp13HghstCllTmprtrCllNmr "HVESP13 Highest Cell Temperature Cell Number: Identifies the location of SPN 15584 (HVESP13 Highest Cell Temperature) within SPN 15666 (HVESP13 Highest Cell Temperature Module Number).This parameter is for one of multiple packs in an HVESS. If there ...";
CM_ SG_ 2364701694 Hvsp13LwstCllTmprtrMdlNmr "HVESP13 Lowest Cell Temperature Module Number: Identifies the location of the module containing SPN 15585 (HVESP13 Lowest Cell Temperature).This parameter is for one of multiple packs in an HVESS. If there is only one pack in the system, the HVESS pa...";
CM_ SG_ 2364701694 Hvsp13LwstCllTmprtrCllNmr "HVESP13 Lowest Cell Temperature Cell Number: Identifies the location of SPN 15585 (HVESP13 Lowest Cell Temperature) within SPN 15668 (HVESP13 Lowest Cell Temperature Module Number).This parameter is for one of multiple packs in an HVESS. If there is ...";
CM_ SG_ 2364701694 Hvess13ThermalEventDetected "HVESS13 Thermal Event Detected: A sensor has detected the presence of a thermal event at or near High Voltage Energy Storage Pack instance.00b = No Thermal Event Detected01b = Thermal Event Detected10b = Error11b = Not availableThis parameter is for ...";
CM_ SG_ 2364701694 Hvsp13Dt9EmdddIntgrtSpprt "HVESP13 Data 9 Embedded Integrity Support: Indicates SPN 23012 (HVESP13 Data 9 CRC) and SPN 23011 (HVESP13 Data 9 Counter) are supported by the sender.00b = Embedded CRC and Counter are supported by the sender01b = Protection is provided using an ext...";
CM_ SG_ 2364701694 Hvesp13Data9Counter "HVESP13 Data 9 Counter: The message counter is used to detect situations where the transmitting ECU malfunction repeats the same frame all the time. The receiver of the information may use the counter parameter to detect this situation. The transmitt...";
CM_ SG_ 2364701694 Hvesp13Data9Crc "HVESP13 Data 9 CRC: The CRC is defined as follows: - Length: 8 bits- Polynomial: x^8+x^5+x^3+x^2+x+1- Initial Value: FFh- Input Data Reflection: Not reflected- Result Data Reflection: Not reflected- XOR value: FFh SAE makes no claim of the functional...";
CM_ BO_ 2364701950 "High Voltage Energy Storage Pack 13 Data 10";
CM_ SG_ 2364701950 Hvsp13HghstCllSttOfChrgMdlNmr "HVESP13 Highest Cell State of Charge Module Number: Identifies the location of the module containing SPN 15594 (HVESP13 Highest Cell State of Charge).This parameter is for one of multiple packs in an HVESS. If there is only one pack in the system, th...";
CM_ SG_ 2364701950 Hvsp13HghstCllSttOfChrgCllNmr "HVESP13 Highest Cell State of Charge Cell Number: Identifies the location of SPN 15594 (HVESP13 Highest Cell State of Charge) within SPN 15670 (HVESP13 Highest Cell State of Charge Module Number).This parameter is for one of multiple packs in an HVES...";
CM_ SG_ 2364701950 Hvsp13LwstCllSttOfChrgMdlNmr "HVESP13 Lowest Cell State of Charge Module Number: Identifies the location of the module containing SPN 15593 (HVESP13 Lowest Cell State of Charge).This parameter is for one of multiple packs in an HVESS. If there is only one pack in the system, the ...";
CM_ SG_ 2364701950 Hvsp13LwstCllSttOfChrgCllNmr "HVESP13 Lowest Cell State of Charge Cell Number: Identifies the location of SPN 15593 (HVESP13 Lowest Cell State of Charge) within SPN 15672 (HVESP13 Lowest Cell State of Charge Module Number).This parameter is for one of multiple packs in an HVESS. ...";
CM_ SG_ 2364701950 Hvsp13HghVltgBsAtvIsltnTstRslts "HVESP13 High-Voltage Bus Active Isolation Test Results: The isolation resistance expressed in Ohms per Volt that resulted from the High-Voltage Bus Active Isolation Test.See SPN 15606 (HVESP13 High-Voltage Bus Active Isolation Test Status) for test s...";
CM_ SG_ 2364701950 Hvsp13HVtBsPssvIstTstRsts "HVESP13 High-Voltage Bus Passive Isolation Test Results: The isolation resistance expressed in Ohms per Volt that resulted from the High-Voltage Bus Passive Isolation Test.See SPN 15607 (HVESP13 High-Voltage Bus Passive Isolation Test Status) for tes...";
CM_ BO_ 2364702206 "High Voltage Energy Storage Pack 13 Data 11";
CM_ SG_ 2364702206 Hvsp13BsVltgNgtvTChsssGrndVltg "HVESP13 Bus Voltage Negative to Chassis Ground Voltage: Voltage difference between the most negative terminal of the HVES battery and chassis measured on the hybrid or EV system bus side (not the battery side) of any HVES contained output contactor. ...";
CM_ SG_ 2364702206 Hvsp13VltgLvlNgtvTChsssGrndVltg "HVESP13 Voltage Level Negative to Chassis Ground Voltage: Voltage difference between the most negative terminal of the HVES battery and chassis measured at the battery side of any HVES contained output contactor.  This voltage may be used for system ...";
CM_ SG_ 2364702206 Hvesp13ActualChargeRate "HVESP13 Actual Charge Rate: This signal represents the actual present charge rate of this High Voltage Energy Storage Pack instance.This parameter is for one of multiple packs in an HVESS. If there is only one pack in the system, the HVESS parameters...";
CM_ BO_ 2364702462 "High Voltage Energy Storage Pack 14 Status 2";
CM_ SG_ 2364702462 Hvsp14DshrgPwrLmtDTSttOfChrg "HVESP14 Discharge Power Limit Due to State of Charge: Indicates whether or not discharge power of this HVES instance is being limited due to state of charge.This parameter is for one of multiple packs in an HVESS.  If there is only one pack in the sy...";
CM_ SG_ 2364702462 Hvsp14DshrgPwrLmtDTBttrTmprtr "HVESP14 Discharge Power Limit Due to Battery Temperature: Indicates whether or not discharge power of this HVES instance is being limited due to battery temperature.This parameter is for one of multiple packs in an HVESS.  If there is only one pack i...";
CM_ SG_ 2364702462 Hvsp14DsPwLtDTBttDstCdt "HVESP14 Discharge Power Limit Due to Battery Diagnostic Condition: Indicates whether or not discharge power of this HVES instance is being limited due to a battery diagnostic condition.This parameter is for one of multiple packs in an HVESS.  If ther...";
CM_ SG_ 2364702462 Hvsp14DsPwLtDTBttOCVt "HVESP14 Discharge Power Limit Due to Battery or Cell Voltage: Indicates whether or not discharge power of this HVES instance is being limited due to a battery or cell voltage level.This parameter is for one of multiple packs in an HVESS.  If there is...";
CM_ SG_ 2364702462 Hvsp14DshrgPwrLmtDTBttrCrrnt "HVESP14 Discharge Power Limit Due to Battery Current: Indicates whether or not discharge power of this HVES instance is being limited due to battery current.This parameter is for one of multiple packs in an HVESS.  If there is only one pack in the sy...";
CM_ SG_ 2364702462 Hvsp14DshrgPwrLmtDTAnUndfndCs "HVESP14 Discharge Power Limit Due to an Undefined Cause: Indicates whether or not discharge power of this HVES instance is being limited due to an undefined cause.This parameter is for one of multiple packs in an HVESS.  If there is only one pack in ...";
CM_ SG_ 2364702462 Hvsp14ChrgPwrLmtDTSttOfChrg "HVESP14 Charge Power Limit Due to State of Charge: Indicates whether or not charge power of this HVES instance is being limited due to state of charge.This parameter is for one of multiple packs in an HVESS.  If there is only one pack in the system, ...";
CM_ SG_ 2364702462 Hvsp14ChrgPwrLmtDTBttrTmprtr "HVESP14 Charge Power Limit Due to Battery Temperature: Indicates whether or not charge power of this HVES instance is being limited due to battery temperature.This parameter is for one of multiple packs in an HVESS.  If there is only one pack in the ...";
CM_ SG_ 2364702462 Hvsp14CPwLtDTBttDstCdt "HVESP14 Charge Power Limit Due to Battery Diagnostic Condition: Indicates whether or not charge power of this HVES instance is being limited due to a battery diagnostic condition.This parameter is for one of multiple packs in an HVESS.  If there is o...";
CM_ SG_ 2364702462 Hvsp14ChrgPwrLmtDTBttrOrCllVltg "HVESP14 Charge Power Limit Due to Battery or Cell Voltage: Indicates whether or not charge power of this HVES instance is being limited due to a battery or cell voltage level.This parameter is for one of multiple packs in an HVESS.  If there is only ...";
CM_ SG_ 2364702462 Hvsp14ChrgPwrLmtDTBttrCrrnt "HVESP14 Charge Power Limit Due to Battery Current: Indicates whether or not charge power of this HVES instance is being limited due to battery current.This parameter is for one of multiple packs in an HVESS.  If there is only one pack in the system, ...";
CM_ SG_ 2364702462 Hvsp14ChrgPwrLmtDTAnUndfndCs "HVESP14 Charge Power Limit Due to an Undefined Cause: Indicates whether or not charge power of this HVES instance is being limited due to an undefined cause.This parameter is for one of multiple packs in an HVESS.  If there is only one pack in the sy...";
CM_ BO_ 2364702718 "High Voltage Energy Storage Pack 14 Data 1";
CM_ SG_ 2364702718 Hvesp14AvailableDischargePower "HVESP14 Available Discharge Power: The rate at which this High Voltage Energy Storage Pack instance can currently provide energy for propulsion or other uses.This parameter is for one of multiple packs in an HVESS.  If there is only one pack in the s...";
CM_ SG_ 2364702718 Hvesp14AvailableChargePower "HVESP14 Available Charge Power: The rate at which this High Voltage Energy Storage Pack instance can currently receive energy from a regenerative or recharging system.This parameter is for one of multiple packs in an HVESS.  If there is only one pack...";
CM_ SG_ 2364702718 Hvesp14VoltageLevel "HVESP14 Voltage Level: The voltage level of this High Voltage Energy Storage Pack instance. This parameter should be synchronized with SPN 15721 (HVESP14 Current) such that a realized power value can be calculated. If the HVES component physically co...";
CM_ SG_ 2364702718 Hvesp14Current "HVESP14 Current: The current in or out of this High Voltage Energy Storage Pack instance. This parameter should be synchronized with SPN 15720 (HVESP14 Voltage Level) such that a realized power value can be calculated. This parameter is defined from ...";
CM_ BO_ 2364702974 "High Voltage Energy Storage Pack 14 Data 2";
CM_ SG_ 2364702974 Hvesp14FastUpdateStateOfCharge "HVESP14 Fast Update State of Charge: Indicates this High Voltage Energy Storage Pack instance state of charge. 0% means no charge remaining, 100% means the system is fully charged in terms of physical limits of this energy storage pack instance. Acce...";
CM_ SG_ 2364702974 Hvesp14HighestCellVoltage "HVESP14 Highest Cell Voltage: The highest voltage level reported by any cell in this High Voltage Energy Storage Pack instance. If a single voltage sensor covers more than one cell, the value in this parameter is for the smallest group of cells measu...";
CM_ SG_ 2364702974 Hvesp14LowestCellVoltage "HVESP14 Lowest Cell Voltage: The lowest voltage level reported by any cell in this High Voltage Energy Storage Pack instance. If a single voltage sensor covers more than one cell, the value in this parameter is for the smallest group of cells measure...";
CM_ SG_ 2364702974 Hvsp14CllVltgDffrntlStts "HVESP14 Cell Voltage Differential Status: Indicates whether or not the differential between the highest and lowest cell voltages are within acceptable limits, according to this High Voltage Energy Storage Pack instance. The actual voltage differentia...";
CM_ BO_ 2364703230 "High Voltage Energy Storage Pack 14 Data 3";
CM_ SG_ 2364703230 Hvesp14HighestCellTemperature "HVESP14 Highest Cell Temperature: The highest temperature level reported by any cell in this High Voltage Energy Storage Pack instance. If a single temperature sensor covers more than one cell, the value in this parameter is for the smallest group of...";
CM_ SG_ 2364703230 Hvesp14LowestCellTemperature "HVESP14 Lowest Cell Temperature: The lowest temperature level reported by any cell in this High Voltage Energy Storage Pack instance. If a single temperature sensor covers more than one cell, the value in this parameter is for the smallest group of c...";
CM_ SG_ 2364703230 Hvesp14AverageCellTemperature "HVESP14 Average Cell Temperature: The average temperature level of all cells in this High Voltage Energy Storage Pack instance.This parameter is for one of multiple packs in an HVESS.  If there is only one pack in the system, the HVESS parameters sho...";
CM_ SG_ 2364703230 Hvsp14CllTmprtrDffrntlStts "HVESP14 Cell Temperature Differential Status: Indicates whether or not the differential between the highest and lowest cell temperatures are within acceptable limits per this High Voltage Energy Storage Pack instance. The actual temperature different...";
CM_ BO_ 2364703486 "High Voltage Energy Storage Pack 14 Data 4";
CM_ SG_ 2364703486 Hvesp14DischargeCapacity "HVESP14 Discharge Capacity: The amount of stored electrical charge in this High Voltage Energy Storage Pack instance that is available for use by the hybrid or EV system, i.e. 'how full is the tank'. See SPN 15760 (HVESP14 Discharge Energy Capacity) ...";
CM_ SG_ 2364703486 Hvesp14ChargeCapacity "HVESP14 Charge Capacity: The amount of unused electrical charge storage in this High Voltage Energy Storage Pack instance that is available to be filled by charging, i.e. 'how much empty space is remaining in the tank'. See SPN 15761 (HVESP14 Charge ...";
CM_ SG_ 2364703486 Hvesp14CellBalancingCount "HVESP14 Cell Balancing Count: The number of cells that are currently being balanced in this High Voltage Energy Storage Pack instance.This parameter is for one of multiple packs in an HVESS.  If there is only one pack in the system, the HVESS paramet...";
CM_ BO_ 2364703742 "High Voltage Energy Storage Pack 14 Data 5";
CM_ SG_ 2364703742 Hvesp14LowestCellStateOfCharge "HVESP14 Lowest Cell State of Charge: Indicates the state of charge of the lowest-charged cell in this High Voltage Energy Storage Pack instance. 0% means no charge remaining, 100% means the cell is fully charged. If a single state of charge value cov...";
CM_ SG_ 2364703742 Hvesp14HighestCellStateOfCharge "HVESP14 Highest Cell State of Charge: Indicates the state of charge of the highest-charged cell in this High Voltage Energy Storage Pack instance. 0% means no charge remaining, 100% means the cell is fully charged. If a single state of charge value c...";
CM_ SG_ 2364703742 Hvsp14MxmmInstntnsDshrgCrrntLmt "HVESP14 Maximum Instantaneous Discharge Current Limit: The maximum instantaneous current flow limit out of this High Voltage Energy Storage Pack instance. This parameter is defined from the high voltage energy storage pack's point of view and should ...";
CM_ SG_ 2364703742 Hvsp14MxmmInstntnsChrgCrrntLmt "HVESP14 Maximum Instantaneous Charge Current Limit: The maximum instantaneous current flow limit into this High Voltage Energy Storage Pack instance. This parameter is defined from the high voltage energy storage pack's point of view and should refle...";
CM_ BO_ 2364703998 "High Voltage Energy Storage Pack 14 Data 6";
CM_ SG_ 2364703998 Hvesp14BusVoltage "HVESP14 Bus Voltage: The voltage level of the high voltage bus, as measured by this High Voltage Energy Storage Pack instance on the bus side (not the battery side) of its contactors.This parameter is for one of multiple packs in an HVESS.  If there ...";
CM_ SG_ 2364703998 Hvesp14IgnitionVoltage "HVESP14 Ignition Voltage: The voltage level at the ignition input of this High Voltage Energy Storage Pack controller.This parameter is for one of multiple packs in an HVESS.  If there is only one pack in the system, the HVESS parameters should be us...";
CM_ SG_ 2364703998 Hvesp14IntakeCoolantTemperature "HVESP14 Intake Coolant Temperature: The temperature of liquid coolant as it enters this High Voltage Energy Storage Pack instance.This parameter is for one of multiple packs in an HVESS.  If there is only one pack in the system, the HVESS parameters ...";
CM_ SG_ 2364703998 Hvesp14OutletCoolantTemperature "HVESP14 Outlet Coolant Temperature: The temperature of liquid coolant as it exits this High Voltage Energy Storage Pack instance.This parameter is for one of multiple packs in an HVESS.  If there is only one pack in the system, the HVESS parameters s...";
CM_ SG_ 2364703998 Hvesp14ElectronicsTemperature "HVESP14 Electronics Temperature: The temperature of the electronics or control modules in this High Voltage Energy Storage Pack instance.  If there are multiple temperature sensors then this parameter would be set to the maximum sensor reading.This p...";
CM_ SG_ 2364703998 Hvesp14Temperature "HVESP14 Temperature: The temperature of this High Voltage Energy Storage Pack instance. The value may be determined from a unique sensor specifically for this purpose, or by aggregating various temperature sensor readings within the pack.This paramet...";
CM_ BO_ 2364704254 "High Voltage Energy Storage Pack 14 Status 1";
CM_ SG_ 2364704254 Hvsp14HghVltgBsPstvCnttrStt "HVESP14 High-Voltage Bus (Positive) Contactor State: Position of this High Voltage Energy Storage Pack instance positive side bus contactor.  When this contactor is closed, the positive side of this HVES instance is connected to the positive side of ...";
CM_ SG_ 2364704254 Hvsp14HghVltgBsNgtvCnttrStt "HVESP14 High-Voltage Bus (Negative) Contactor State: Position of this High Voltage Energy Storage Pack instance negative side bus contactor. When this contactor is closed, the negative side of this HVES instance is connected to the negative side of t...";
CM_ SG_ 2364704254 Hvsp14HghVltgBsDsnntFrwrnng "HVESP14 High-Voltage Bus Disconnect Forewarning: Indicates that this High Voltage Energy Storage Pack instance is about to disconnect from the high voltage bus due to unacceptable conditions.This parameter is for one of multiple packs in an HVESS. If...";
CM_ SG_ 2364704254 Hvsp14HghVltgBsPrChrgRlStt "HVESP14 High-Voltage Bus Pre-Charge Relay State: Position of the high-voltage bus contactor pre-charge relay.  When this relay is closed, this High Voltage Energy Storage Pack instance is bringing the high-voltage bus up to its operating level.This p...";
CM_ SG_ 2364704254 Hvsp14CntrOfPkCnttrStt "HVESP14 Center of Pack Contactor State: Position of the center high-voltage contactor. When this contactor is closed, the positive half of this High Voltage Energy Storage Pack instance is connected to the negative half. If a system controls the posi...";
CM_ SG_ 2364704254 Hvsp14HghVltgBsAtvIsltnTstStts "HVESP14 High-Voltage Bus Active Isolation Test Status: Status of the high-voltage bus electrical active isolation test as performed by this High Voltage Energy Storage Pack instance.This parameter is for one of multiple packs in an HVESS. If there is...";
CM_ SG_ 2364704254 Hvsp14HghVltgBsPssvIsltnTstStts "HVESP14 High-Voltage Bus Passive Isolation Test Status: Status of the high-voltage bus electrical passive isolation test as performed by this High Voltage Energy Storage Pack instance.This parameter is for one of multiple packs in an HVESS. If there ...";
CM_ SG_ 2364704254 Hvesp14HvilStatus "HVESP14 HVIL Status: Status of the High Voltage Interlock Loop from the viewpoint of this High Voltage Energy Storage Pack instance.This parameter is for one of multiple packs in an HVESS. If there is only one pack in the system, the HVESS parameters...";
CM_ SG_ 2364704254 Hvesp14InertiaSwitchStatus "HVESP14 Inertia Switch Status: Switch indicating that an impact has been sensed by this High Voltage Energy Storage Pack instance. The impact indication may require action by another controller, or by this HVES instance itself.  For example, a contro...";
CM_ SG_ 2364704254 Hvesp14StateOfChargeStatus "HVESP14 State of Charge Status: Status of this High Voltage Energy Storage Pack instance State of Charge (SOC).  Note:  A given HVES controller may not support all of the states.This parameter is for one of multiple packs in an HVESS.  If there is on...";
CM_ SG_ 2364704254 Hvesp14CellBalanceStatus "HVESP14 Cell Balance Status: Indicates whether or not the cells in this High Voltage Energy Storage Pack instance are balanced.This parameter is for one of multiple packs in an HVESS.  If there is only one pack in the system, the HVESS parameters sho...";
CM_ SG_ 2364704254 Hvesp14CellBalancingActive "HVESP14 Cell Balancing Active: Indicates whether or not the cells in this High Voltage Energy Storage Pack instance are currently being balanced.This parameter is for one of multiple packs in an HVESS.  If there is only one pack in the system, the HV...";
CM_ SG_ 2364704254 Hvesp14InternalChargerStatus "HVESP14 Internal Charger Status: Indicates that the charger in this HVES instance is on.  External chargers may use the External Energy Source Connection Status (SPN 7898) and related SPs.This parameter is for one of multiple packs in an HVESS. If th...";
CM_ SG_ 2364704254 Hvsp14HghVltgBsCnntnStts "HVESP14 High-Voltage Bus Connection Status: This parameter provides high level feedback on this High Voltage Energy Storage Pack instance high voltage bus connection. For specific contactor information, see SPN 15743 (HVESP14 High-Voltage Bus (Positi...";
CM_ SG_ 2364704254 Hvesp14OperationalStatus "HVESP14 Operational Status: Provides feedback on where this High Voltage Energy Storage Pack instance is in its operating spectrum, and includes feedback in response to the Operation Consent [i.e. SPN 15701 (HVESP14 Operation Consent)] and Power Down...";
CM_ SG_ 2364704254 Hvesp14Status1Counter "HVESP14 Status 1 Counter: The message counter is used to detect situations where the transmitting ECU malfunction repeats the same frame all the time. The receiver of the information may use the counter parameter to detect this situation. The transmi...";
CM_ SG_ 2364704254 Hvesp14Status1Crc "HVESP14 Status 1 CRC: The CRC is defined as follows: - Length: 8 bits- Polynomial: x^8+x^5+x^3+x^2+x+1- Initial Value: FFh- Input Data Reflection: Not reflected- Result Data Reflection: Not reflected- XOR value: FFh SAE makes no claim of the function...";
CM_ BO_ 2364704510 "High Voltage Energy Storage Pack 14 Data 7";
CM_ SG_ 2364704510 Hvesp14DischargeEnergyCapacity "HVESP14 Discharge Energy Capacity: The amount of stored electrical energy in this High Voltage Energy Storage Pack instance that is available for use by the hybrid or EV system, i.e. 'how full is the tank'. See SPN 15730 (HVESP14 Discharge Capacity) ...";
CM_ SG_ 2364704510 Hvesp14ChargeEnergyCapacity "HVESP14 Charge Energy Capacity: The amount of unused electrical energy storage available to be filled by charging this High Voltage Energy Storage Pack instance, i.e. 'how much empty space is remaining in the tank'. See SPN 15731 (HVESP14 Charge Capa...";
CM_ SG_ 2364704510 Hvsp14MxmmChrgVltgLmt "HVESP14 Maximum Charge Voltage Limit: The maximum voltage level not to be exceeded while charging this High Voltage Energy Storage Pack instance. If this parameter is not supported, the maximum charge voltage should be limited to SPN 15829 (HVESP14 R...";
BA_DEF_ SG_  "SPN" INT 0 524287;
BA_DEF_ BO_  "VFrameFormat" ENUM  "StandardCAN","ExtendedCAN","reserved","J1939PG";
BA_DEF_DEF_  "SPN" 0;
BA_DEF_DEF_  "VFrameFormat" "J1939PG";
BA_ "SPN" SG_ 2364573182 PowerConverter2Status1Crc 20670;
BA_ "SPN" SG_ 2364573182 PowerConverter2Status1Counter 20671;
BA_ "SPN" SG_ 2364573182 PowerConverter2Current 20672;
BA_ "SPN" SG_ 2364573182 PowerConverter2Frequency 20673;
BA_ "SPN" SG_ 2364573182 PwrCnvrtr2DEnrgSr1Crrnt 20674;
BA_ "SPN" SG_ 2364573182 PwrCnvrtr2DEnrgSr1Vltg 20675;
BA_ "SPN" SG_ 2364573438 PowerConverter1Status1Crc 20692;
BA_ "SPN" SG_ 2364573438 PowerConverter1Status1Counter 20693;
BA_ "SPN" SG_ 2364573438 PowerConverter1Current 20694;
BA_ "SPN" SG_ 2364573438 PowerConverter1Frequency 20695;
BA_ "SPN" SG_ 2364573438 PwrCnvrtr1DEnrgSr1Crrnt 20696;
BA_ "SPN" SG_ 2364573438 PwrCnvrtr1DEnrgSr1Vltg 20697;
BA_ "SPN" SG_ 2364690942 Hvsp11DshrgPwrLmtDTSttOfChrg 15280;
BA_ "SPN" SG_ 2364690942 Hvsp11DshrgPwrLmtDTBttrTmprtr 15281;
BA_ "SPN" SG_ 2364690942 Hvsp11DsPwLtDTBttDstCdt 15282;
BA_ "SPN" SG_ 2364690942 Hvsp11DsPwLtDTBttOCVt 15283;
BA_ "SPN" SG_ 2364690942 Hvsp11DshrgPwrLmtDTBttrCrrnt 15284;
BA_ "SPN" SG_ 2364690942 Hvsp11DshrgPwrLmtDTAnUndfndCs 15285;
BA_ "SPN" SG_ 2364690942 Hvsp11ChrgPwrLmtDTSttOfChrg 15286;
BA_ "SPN" SG_ 2364690942 Hvsp11ChrgPwrLmtDTBttrTmprtr 15287;
BA_ "SPN" SG_ 2364690942 Hvsp11CPwLtDTBttDstCdt 15288;
BA_ "SPN" SG_ 2364690942 Hvsp11ChrgPwrLmtDTBttrOrCllVltg 15289;
BA_ "SPN" SG_ 2364690942 Hvsp11ChrgPwrLmtDTBttrCrrnt 15290;
BA_ "SPN" SG_ 2364690942 Hvsp11ChrgPwrLmtDTAnUndfndCs 15291;
BA_ "SPN" SG_ 2364691198 Hvesp11AvailableDischargePower 15292;
BA_ "SPN" SG_ 2364691198 Hvesp11AvailableChargePower 15293;
BA_ "SPN" SG_ 2364691198 Hvesp11VoltageLevel 15294;
BA_ "SPN" SG_ 2364691198 Hvesp11Current 15295;
BA_ "SPN" SG_ 2364691454 Hvesp11FastUpdateStateOfCharge 15296;
BA_ "SPN" SG_ 2364691454 Hvesp11HighestCellVoltage 15297;
BA_ "SPN" SG_ 2364691454 Hvesp11LowestCellVoltage 15298;
BA_ "SPN" SG_ 2364691454 Hvsp11CllVltgDffrntlStts 15299;
BA_ "SPN" SG_ 2364691710 Hvesp11HighestCellTemperature 15300;
BA_ "SPN" SG_ 2364691710 Hvesp11LowestCellTemperature 15301;
BA_ "SPN" SG_ 2364691710 Hvesp11AverageCellTemperature 15302;
BA_ "SPN" SG_ 2364691710 Hvsp11CllTmprtrDffrntlStts 15303;
BA_ "SPN" SG_ 2364691966 Hvesp11DischargeCapacity 15304;
BA_ "SPN" SG_ 2364691966 Hvesp11ChargeCapacity 15305;
BA_ "SPN" SG_ 2364691966 Hvesp11CellBalancingCount 15306;
BA_ "SPN" SG_ 2364692222 Hvesp11LowestCellStateOfCharge 15309;
BA_ "SPN" SG_ 2364692222 Hvesp11HighestCellStateOfCharge 15310;
BA_ "SPN" SG_ 2364692222 Hvsp11MxmmInstntnsDshrgCrrntLmt 15307;
BA_ "SPN" SG_ 2364692222 Hvsp11MxmmInstntnsChrgCrrntLmt 15308;
BA_ "SPN" SG_ 2364692478 Hvesp11BusVoltage 15311;
BA_ "SPN" SG_ 2364692478 Hvesp11IgnitionVoltage 15312;
BA_ "SPN" SG_ 2364692478 Hvesp11IntakeCoolantTemperature 15313;
BA_ "SPN" SG_ 2364692478 Hvesp11OutletCoolantTemperature 15314;
BA_ "SPN" SG_ 2364692478 Hvesp11ElectronicsTemperature 15315;
BA_ "SPN" SG_ 2364692478 Hvesp11Temperature 15316;
BA_ "SPN" SG_ 2364692734 Hvsp11HghVltgBsPstvCnttrStt 15317;
BA_ "SPN" SG_ 2364692734 Hvsp11HghVltgBsNgtvCnttrStt 15318;
BA_ "SPN" SG_ 2364692734 Hvsp11HghVltgBsDsnntFrwrnng 15319;
BA_ "SPN" SG_ 2364692734 Hvsp11HghVltgBsPrChrgRlStt 15320;
BA_ "SPN" SG_ 2364692734 Hvsp11CntrOfPkCnttrStt 15321;
BA_ "SPN" SG_ 2364692734 Hvsp11HghVltgBsAtvIsltnTstStts 15322;
BA_ "SPN" SG_ 2364692734 Hvsp11HghVltgBsPssvIsltnTstStts 15323;
BA_ "SPN" SG_ 2364692734 Hvesp11HvilStatus 15324;
BA_ "SPN" SG_ 2364692734 Hvesp11InertiaSwitchStatus 15325;
BA_ "SPN" SG_ 2364692734 Hvesp11StateOfChargeStatus 15326;
BA_ "SPN" SG_ 2364692734 Hvesp11CellBalanceStatus 15327;
BA_ "SPN" SG_ 2364692734 Hvesp11CellBalancingActive 15328;
BA_ "SPN" SG_ 2364692734 Hvesp11InternalChargerStatus 15329;
BA_ "SPN" SG_ 2364692734 Hvsp11HghVltgBsCnntnStts 15330;
BA_ "SPN" SG_ 2364692734 Hvesp11OperationalStatus 15331;
BA_ "SPN" SG_ 2364692734 Hvesp11Status1Counter 15332;
BA_ "SPN" SG_ 2364692734 Hvesp11Status1Crc 15333;
BA_ "SPN" SG_ 2364692990 Hvesp11DischargeEnergyCapacity 15334;
BA_ "SPN" SG_ 2364692990 Hvesp11ChargeEnergyCapacity 15335;
BA_ "SPN" SG_ 2364692990 Hvsp11MxmmChrgVltgLmt 15336;
BA_ "SPN" SG_ 2364693246 Hvesp11Module1OperationalStatus 15337;
BA_ "SPN" SG_ 2364693246 Hvesp11Module2OperationalStatus 15338;
BA_ "SPN" SG_ 2364693246 Hvesp11Module3OperationalStatus 15339;
BA_ "SPN" SG_ 2364693246 Hvesp11Module4OperationalStatus 15340;
BA_ "SPN" SG_ 2364693246 Hvesp11Module5OperationalStatus 15341;
BA_ "SPN" SG_ 2364693246 Hvesp11Module6OperationalStatus 15342;
BA_ "SPN" SG_ 2364693246 Hvesp11Module7OperationalStatus 15343;
BA_ "SPN" SG_ 2364693246 Hvesp11Module8OperationalStatus 15344;
BA_ "SPN" SG_ 2364693246 Hvesp11Module9OperationalStatus 15345;
BA_ "SPN" SG_ 2364693246 Hvsp11Mdl10OprtnlStts 15346;
BA_ "SPN" SG_ 2364693246 Hvsp11Mdl11OprtnlStts 15347;
BA_ "SPN" SG_ 2364693246 Hvsp11Mdl12OprtnlStts 15348;
BA_ "SPN" SG_ 2364693246 Hvsp11Mdl13OprtnlStts 15349;
BA_ "SPN" SG_ 2364693246 Hvsp11Mdl14OprtnlStts 15350;
BA_ "SPN" SG_ 2364693246 Hvsp11Mdl15OprtnlStts 15351;
BA_ "SPN" SG_ 2364693246 Hvsp11Mdl16OprtnlStts 15352;
BA_ "SPN" SG_ 2364693246 Hvsp11Mdl17OprtnlStts 15353;
BA_ "SPN" SG_ 2364693246 Hvsp11Mdl18OprtnlStts 15354;
BA_ "SPN" SG_ 2364693246 Hvsp11Mdl19OprtnlStts 15355;
BA_ "SPN" SG_ 2364693246 Hvsp11Mdl20OprtnlStts 15356;
BA_ "SPN" SG_ 2364693246 Hvsp11Mdl21OprtnlStts 15357;
BA_ "SPN" SG_ 2364693246 Hvsp11Mdl22OprtnlStts 15358;
BA_ "SPN" SG_ 2364693246 Hvsp11Mdl23OprtnlStts 15359;
BA_ "SPN" SG_ 2364693246 Hvsp11Mdl24OprtnlStts 15360;
BA_ "SPN" SG_ 2364693246 Hvsp11Mdl25OprtnlStts 15361;
BA_ "SPN" SG_ 2364693246 Hvsp11Mdl26OprtnlStts 15362;
BA_ "SPN" SG_ 2364693246 Hvsp11Mdl27OprtnlStts 15363;
BA_ "SPN" SG_ 2364693246 Hvsp11Mdl28OprtnlStts 15364;
BA_ "SPN" SG_ 2364693246 Hvsp11Mdl29OprtnlStts 15365;
BA_ "SPN" SG_ 2364693246 Hvsp11Mdl30OprtnlStts 15366;
BA_ "SPN" SG_ 2364693246 Hvsp11Mdl31OprtnlStts 15367;
BA_ "SPN" SG_ 2364693246 Hvsp11Mdl32OprtnlStts 15368;
BA_ "SPN" SG_ 2364693502 Hvsp11ThrmlMngmntSstmSlInptPwr 15369;
BA_ "SPN" SG_ 2364693502 Hvsp11TMtSstHVtIptPw 15370;
BA_ "SPN" SG_ 2364693502 Hvsp11ThrmlMngmntSstmCmprssrSpd 15371;
BA_ "SPN" SG_ 2364693502 Hvsp11ThrmlMngmntSstmRltvHmdt 15372;
BA_ "SPN" SG_ 2364693502 Hvsp11ThrmlMngmntSstmHtrStts 15373;
BA_ "SPN" SG_ 2364693502 Hvsp11ThrmlMngmntSstmHvlStts 15374;
BA_ "SPN" SG_ 2364693502 Hvsp11ThrmlMngmntSstmMd 15375;
BA_ "SPN" SG_ 2364693502 Hvsp11ThrmlMngmntSstmClntLvl 15376;
BA_ "SPN" SG_ 2364693758 Hvsp11HghstCllVltgMdlNmr 15377;
BA_ "SPN" SG_ 2364693758 Hvsp11HghstCllVltgCllNmr 15378;
BA_ "SPN" SG_ 2364693758 Hvsp11LwstCllVltgMdlNmr 15379;
BA_ "SPN" SG_ 2364693758 Hvsp11LwstCllVltgCllNmr 15380;
BA_ "SPN" SG_ 2364693758 Hvesp11AverageCellVoltage 15381;
BA_ "SPN" SG_ 2364694014 Hvsp11HghstCllTmprtrMdlNmr 15382;
BA_ "SPN" SG_ 2364694014 Hvsp11HghstCllTmprtrCllNmr 15383;
BA_ "SPN" SG_ 2364694014 Hvsp11LwstCllTmprtrMdlNmr 15384;
BA_ "SPN" SG_ 2364694014 Hvsp11LwstCllTmprtrCllNmr 15385;
BA_ "SPN" SG_ 2364694014 Hvess11ThermalEventDetected 21298;
BA_ "SPN" SG_ 2364694014 Hvsp11Dt9EmdddIntgrtSpprt 23004;
BA_ "SPN" SG_ 2364694014 Hvesp11Data9Counter 23005;
BA_ "SPN" SG_ 2364694014 Hvesp11Data9Crc 23006;
BA_ "SPN" SG_ 2364694270 Hvsp11HghstCllSttOfChrgMdlNmr 15386;
BA_ "SPN" SG_ 2364694270 Hvsp11HghstCllSttOfChrgCllNmr 15387;
BA_ "SPN" SG_ 2364694270 Hvsp11LwstCllSttOfChrgMdlNmr 15388;
BA_ "SPN" SG_ 2364694270 Hvsp11LwstCllSttOfChrgCllNmr 15389;
BA_ "SPN" SG_ 2364694270 Hvsp11HghVltgBsAtvIsltnTstRslts 15390;
BA_ "SPN" SG_ 2364694270 Hvsp11HVtBsPssvIstTstRsts 15391;
BA_ "SPN" SG_ 2364694526 Hvsp11BsVltgNgtvTChsssGrndVltg 15392;
BA_ "SPN" SG_ 2364694526 Hvsp11VltgLvlNgtvTChsssGrndVltg 15393;
BA_ "SPN" SG_ 2364694526 Hvesp11ActualChargeRate 15394;
BA_ "SPN" SG_ 2364694782 Hvsp12DshrgPwrLmtDTSttOfChrg 15422;
BA_ "SPN" SG_ 2364694782 Hvsp12DshrgPwrLmtDTBttrTmprtr 15423;
BA_ "SPN" SG_ 2364694782 Hvsp12DsPwLtDTBttDstCdt 15424;
BA_ "SPN" SG_ 2364694782 Hvsp12DsPwLtDTBttOCVt 15425;
BA_ "SPN" SG_ 2364694782 Hvsp12DshrgPwrLmtDTBttrCrrnt 15426;
BA_ "SPN" SG_ 2364694782 Hvsp12DshrgPwrLmtDTAnUndfndCs 15427;
BA_ "SPN" SG_ 2364694782 Hvsp12ChrgPwrLmtDTSttOfChrg 15428;
BA_ "SPN" SG_ 2364694782 Hvsp12ChrgPwrLmtDTBttrTmprtr 15429;
BA_ "SPN" SG_ 2364694782 Hvsp12CPwLtDTBttDstCdt 15430;
BA_ "SPN" SG_ 2364694782 Hvsp12ChrgPwrLmtDTBttrOrCllVltg 15431;
BA_ "SPN" SG_ 2364694782 Hvsp12ChrgPwrLmtDTBttrCrrnt 15432;
BA_ "SPN" SG_ 2364694782 Hvsp12ChrgPwrLmtDTAnUndfndCs 15433;
BA_ "SPN" SG_ 2364695038 Hvesp12AvailableDischargePower 15434;
BA_ "SPN" SG_ 2364695038 Hvesp12AvailableChargePower 15435;
BA_ "SPN" SG_ 2364695038 Hvesp12VoltageLevel 15436;
BA_ "SPN" SG_ 2364695038 Hvesp12Current 15437;
BA_ "SPN" SG_ 2364695294 Hvesp12FastUpdateStateOfCharge 15438;
BA_ "SPN" SG_ 2364695294 Hvesp12HighestCellVoltage 15439;
BA_ "SPN" SG_ 2364695294 Hvesp12LowestCellVoltage 15440;
BA_ "SPN" SG_ 2364695294 Hvsp12CllVltgDffrntlStts 15441;
BA_ "SPN" SG_ 2364695550 Hvesp12HighestCellTemperature 15442;
BA_ "SPN" SG_ 2364695550 Hvesp12LowestCellTemperature 15443;
BA_ "SPN" SG_ 2364695550 Hvesp12AverageCellTemperature 15444;
BA_ "SPN" SG_ 2364695550 Hvsp12CllTmprtrDffrntlStts 15445;
BA_ "SPN" SG_ 2364695806 Hvesp12DischargeCapacity 15446;
BA_ "SPN" SG_ 2364695806 Hvesp12ChargeCapacity 15447;
BA_ "SPN" SG_ 2364695806 Hvesp12CellBalancingCount 15448;
BA_ "SPN" SG_ 2364696062 Hvesp12LowestCellStateOfCharge 15451;
BA_ "SPN" SG_ 2364696062 Hvesp12HighestCellStateOfCharge 15452;
BA_ "SPN" SG_ 2364696062 Hvsp12MxmmInstntnsDshrgCrrntLmt 15449;
BA_ "SPN" SG_ 2364696062 Hvsp12MxmmInstntnsChrgCrrntLmt 15450;
BA_ "SPN" SG_ 2364696318 Hvesp12BusVoltage 15453;
BA_ "SPN" SG_ 2364696318 Hvesp12IgnitionVoltage 15454;
BA_ "SPN" SG_ 2364696318 Hvesp12IntakeCoolantTemperature 15455;
BA_ "SPN" SG_ 2364696318 Hvesp12OutletCoolantTemperature 15456;
BA_ "SPN" SG_ 2364696318 Hvesp12ElectronicsTemperature 15457;
BA_ "SPN" SG_ 2364696318 Hvesp12Temperature 15458;
BA_ "SPN" SG_ 2364696574 Hvsp12HghVltgBsPstvCnttrStt 15459;
BA_ "SPN" SG_ 2364696574 Hvsp12HghVltgBsNgtvCnttrStt 15460;
BA_ "SPN" SG_ 2364696574 Hvsp12HghVltgBsDsnntFrwrnng 15461;
BA_ "SPN" SG_ 2364696574 Hvsp12HghVltgBsPrChrgRlStt 15462;
BA_ "SPN" SG_ 2364696574 Hvsp12CntrOfPkCnttrStt 15463;
BA_ "SPN" SG_ 2364696574 Hvsp12HghVltgBsAtvIsltnTstStts 15464;
BA_ "SPN" SG_ 2364696574 Hvsp12HghVltgBsPssvIsltnTstStts 15465;
BA_ "SPN" SG_ 2364696574 Hvesp12HvilStatus 15466;
BA_ "SPN" SG_ 2364696574 Hvesp12InertiaSwitchStatus 15467;
BA_ "SPN" SG_ 2364696574 Hvesp12StateOfChargeStatus 15468;
BA_ "SPN" SG_ 2364696574 Hvesp12CellBalanceStatus 15469;
BA_ "SPN" SG_ 2364696574 Hvesp12CellBalancingActive 15470;
BA_ "SPN" SG_ 2364696574 Hvesp12InternalChargerStatus 15471;
BA_ "SPN" SG_ 2364696574 Hvsp12HghVltgBsCnntnStts 15472;
BA_ "SPN" SG_ 2364696574 Hvesp12OperationalStatus 15473;
BA_ "SPN" SG_ 2364696574 Hvesp12Status1Counter 15474;
BA_ "SPN" SG_ 2364696574 Hvesp12Status1Crc 15475;
BA_ "SPN" SG_ 2364696830 Hvesp12DischargeEnergyCapacity 15476;
BA_ "SPN" SG_ 2364696830 Hvesp12ChargeEnergyCapacity 15477;
BA_ "SPN" SG_ 2364696830 Hvsp12MxmmChrgVltgLmt 15478;
BA_ "SPN" SG_ 2364697086 Hvesp12Module1OperationalStatus 15479;
BA_ "SPN" SG_ 2364697086 Hvesp12Module2OperationalStatus 15480;
BA_ "SPN" SG_ 2364697086 Hvesp12Module3OperationalStatus 15481;
BA_ "SPN" SG_ 2364697086 Hvesp12Module4OperationalStatus 15482;
BA_ "SPN" SG_ 2364697086 Hvesp12Module5OperationalStatus 15483;
BA_ "SPN" SG_ 2364697086 Hvesp12Module6OperationalStatus 15484;
BA_ "SPN" SG_ 2364697086 Hvesp12Module7OperationalStatus 15485;
BA_ "SPN" SG_ 2364697086 Hvesp12Module8OperationalStatus 15486;
BA_ "SPN" SG_ 2364697086 Hvesp12Module9OperationalStatus 15487;
BA_ "SPN" SG_ 2364697086 Hvsp12Mdl10OprtnlStts 15488;
BA_ "SPN" SG_ 2364697086 Hvsp12Mdl11OprtnlStts 15489;
BA_ "SPN" SG_ 2364697086 Hvsp12Mdl12OprtnlStts 15490;
BA_ "SPN" SG_ 2364697086 Hvsp12Mdl13OprtnlStts 15491;
BA_ "SPN" SG_ 2364697086 Hvsp12Mdl14OprtnlStts 15492;
BA_ "SPN" SG_ 2364697086 Hvsp12Mdl15OprtnlStts 15493;
BA_ "SPN" SG_ 2364697086 Hvsp12Mdl16OprtnlStts 15494;
BA_ "SPN" SG_ 2364697086 Hvsp12Mdl17OprtnlStts 15495;
BA_ "SPN" SG_ 2364697086 Hvsp12Mdl18OprtnlStts 15496;
BA_ "SPN" SG_ 2364697086 Hvsp12Mdl19OprtnlStts 15497;
BA_ "SPN" SG_ 2364697086 Hvsp12Mdl20OprtnlStts 15498;
BA_ "SPN" SG_ 2364697086 Hvsp12Mdl21OprtnlStts 15499;
BA_ "SPN" SG_ 2364697086 Hvsp12Mdl22OprtnlStts 15500;
BA_ "SPN" SG_ 2364697086 Hvsp12Mdl23OprtnlStts 15501;
BA_ "SPN" SG_ 2364697086 Hvsp12Mdl24OprtnlStts 15502;
BA_ "SPN" SG_ 2364697086 Hvsp12Mdl25OprtnlStts 15503;
BA_ "SPN" SG_ 2364697086 Hvsp12Mdl26OprtnlStts 15504;
BA_ "SPN" SG_ 2364697086 Hvsp12Mdl27OprtnlStts 15505;
BA_ "SPN" SG_ 2364697086 Hvsp12Mdl28OprtnlStts 15506;
BA_ "SPN" SG_ 2364697086 Hvsp12Mdl29OprtnlStts 15507;
BA_ "SPN" SG_ 2364697086 Hvsp12Mdl30OprtnlStts 15508;
BA_ "SPN" SG_ 2364697086 Hvsp12Mdl31OprtnlStts 15509;
BA_ "SPN" SG_ 2364697086 Hvsp12Mdl32OprtnlStts 15510;
BA_ "SPN" SG_ 2364697342 Hvsp12ThrmlMngmntSstmSlInptPwr 15511;
BA_ "SPN" SG_ 2364697342 Hvsp12TMtSstHVtIptPw 15512;
BA_ "SPN" SG_ 2364697342 Hvsp12ThrmlMngmntSstmCmprssrSpd 15513;
BA_ "SPN" SG_ 2364697342 Hvsp12ThrmlMngmntSstmRltvHmdt 15514;
BA_ "SPN" SG_ 2364697342 Hvsp12ThrmlMngmntSstmHtrStts 15515;
BA_ "SPN" SG_ 2364697342 Hvsp12ThrmlMngmntSstmHvlStts 15516;
BA_ "SPN" SG_ 2364697342 Hvsp12ThrmlMngmntSstmMd 15517;
BA_ "SPN" SG_ 2364697342 Hvsp12ThrmlMngmntSstmClntLvl 15518;
BA_ "SPN" SG_ 2364697598 Hvsp12HghstCllVltgMdlNmr 15519;
BA_ "SPN" SG_ 2364697598 Hvsp12HghstCllVltgCllNmr 15520;
BA_ "SPN" SG_ 2364697598 Hvsp12LwstCllVltgMdlNmr 15521;
BA_ "SPN" SG_ 2364697598 Hvsp12LwstCllVltgCllNmr 15522;
BA_ "SPN" SG_ 2364697598 Hvesp12AverageCellVoltage 15523;
BA_ "SPN" SG_ 2364697854 Hvsp12HghstCllTmprtrMdlNmr 15524;
BA_ "SPN" SG_ 2364697854 Hvsp12HghstCllTmprtrCllNmr 15525;
BA_ "SPN" SG_ 2364697854 Hvsp12LwstCllTmprtrMdlNmr 15526;
BA_ "SPN" SG_ 2364697854 Hvsp12LwstCllTmprtrCllNmr 15527;
BA_ "SPN" SG_ 2364697854 Hvess12ThermalEventDetected 21299;
BA_ "SPN" SG_ 2364697854 Hvsp12Dt9EmdddIntgrtSpprt 23007;
BA_ "SPN" SG_ 2364697854 Hvesp12Data9Counter 23008;
BA_ "SPN" SG_ 2364697854 Hvesp12Data9Crc 23009;
BA_ "SPN" SG_ 2364698110 Hvsp12HghstCllSttOfChrgMdlNmr 15528;
BA_ "SPN" SG_ 2364698110 Hvsp12HghstCllSttOfChrgCllNmr 15529;
BA_ "SPN" SG_ 2364698110 Hvsp12LwstCllSttOfChrgMdlNmr 15530;
BA_ "SPN" SG_ 2364698110 Hvsp12LwstCllSttOfChrgCllNmr 15531;
BA_ "SPN" SG_ 2364698110 Hvsp12HghVltgBsAtvIsltnTstRslts 15532;
BA_ "SPN" SG_ 2364698110 Hvsp12HVtBsPssvIstTstRsts 15533;
BA_ "SPN" SG_ 2364698366 Hvsp12BsVltgNgtvTChsssGrndVltg 15534;
BA_ "SPN" SG_ 2364698366 Hvsp12VltgLvlNgtvTChsssGrndVltg 15535;
BA_ "SPN" SG_ 2364698366 Hvesp12ActualChargeRate 15536;
BA_ "SPN" SG_ 2364698622 Hvsp13DshrgPwrLmtDTSttOfChrg 15564;
BA_ "SPN" SG_ 2364698622 Hvsp13DshrgPwrLmtDTBttrTmprtr 15565;
BA_ "SPN" SG_ 2364698622 Hvsp13DsPwLtDTBttDstCdt 15566;
BA_ "SPN" SG_ 2364698622 Hvsp13DsPwLtDTBttOCVt 15567;
BA_ "SPN" SG_ 2364698622 Hvsp13DshrgPwrLmtDTBttrCrrnt 15568;
BA_ "SPN" SG_ 2364698622 Hvsp13DshrgPwrLmtDTAnUndfndCs 15569;
BA_ "SPN" SG_ 2364698622 Hvsp13ChrgPwrLmtDTSttOfChrg 15570;
BA_ "SPN" SG_ 2364698622 Hvsp13ChrgPwrLmtDTBttrTmprtr 15571;
BA_ "SPN" SG_ 2364698622 Hvsp13CPwLtDTBttDstCdt 15572;
BA_ "SPN" SG_ 2364698622 Hvsp13ChrgPwrLmtDTBttrOrCllVltg 15573;
BA_ "SPN" SG_ 2364698622 Hvsp13ChrgPwrLmtDTBttrCrrnt 15574;
BA_ "SPN" SG_ 2364698622 Hvsp13ChrgPwrLmtDTAnUndfndCs 15575;
BA_ "SPN" SG_ 2364698878 Hvesp13AvailableDischargePower 15576;
BA_ "SPN" SG_ 2364698878 Hvesp13AvailableChargePower 15577;
BA_ "SPN" SG_ 2364698878 Hvesp13VoltageLevel 15578;
BA_ "SPN" SG_ 2364698878 Hvesp13Current 15579;
BA_ "SPN" SG_ 2364699134 Hvesp13FastUpdateStateOfCharge 15580;
BA_ "SPN" SG_ 2364699134 Hvesp13HighestCellVoltage 15581;
BA_ "SPN" SG_ 2364699134 Hvesp13LowestCellVoltage 15582;
BA_ "SPN" SG_ 2364699134 Hvsp13CllVltgDffrntlStts 15583;
BA_ "SPN" SG_ 2364699390 Hvesp13HighestCellTemperature 15584;
BA_ "SPN" SG_ 2364699390 Hvesp13LowestCellTemperature 15585;
BA_ "SPN" SG_ 2364699390 Hvesp13AverageCellTemperature 15586;
BA_ "SPN" SG_ 2364699390 Hvsp13CllTmprtrDffrntlStts 15587;
BA_ "SPN" SG_ 2364699646 Hvesp13DischargeCapacity 15588;
BA_ "SPN" SG_ 2364699646 Hvesp13ChargeCapacity 15589;
BA_ "SPN" SG_ 2364699646 Hvesp13CellBalancingCount 15590;
BA_ "SPN" SG_ 2364699902 Hvesp13LowestCellStateOfCharge 15593;
BA_ "SPN" SG_ 2364699902 Hvesp13HighestCellStateOfCharge 15594;
BA_ "SPN" SG_ 2364699902 Hvsp13MxmmInstntnsDshrgCrrntLmt 15591;
BA_ "SPN" SG_ 2364699902 Hvsp13MxmmInstntnsChrgCrrntLmt 15592;
BA_ "SPN" SG_ 2364700158 Hvesp13BusVoltage 15595;
BA_ "SPN" SG_ 2364700158 Hvesp13IgnitionVoltage 15596;
BA_ "SPN" SG_ 2364700158 Hvesp13IntakeCoolantTemperature 15597;
BA_ "SPN" SG_ 2364700158 Hvesp13OutletCoolantTemperature 15598;
BA_ "SPN" SG_ 2364700158 Hvesp13ElectronicsTemperature 15599;
BA_ "SPN" SG_ 2364700158 Hvesp13Temperature 15600;
BA_ "SPN" SG_ 2364700414 Hvsp13HghVltgBsPstvCnttrStt 15601;
BA_ "SPN" SG_ 2364700414 Hvsp13HghVltgBsNgtvCnttrStt 15602;
BA_ "SPN" SG_ 2364700414 Hvsp13HghVltgBsDsnntFrwrnng 15603;
BA_ "SPN" SG_ 2364700414 Hvsp13HghVltgBsPrChrgRlStt 15604;
BA_ "SPN" SG_ 2364700414 Hvsp13CntrOfPkCnttrStt 15605;
BA_ "SPN" SG_ 2364700414 Hvsp13HghVltgBsAtvIsltnTstStts 15606;
BA_ "SPN" SG_ 2364700414 Hvsp13HghVltgBsPssvIsltnTstStts 15607;
BA_ "SPN" SG_ 2364700414 Hvesp13HvilStatus 15608;
BA_ "SPN" SG_ 2364700414 Hvesp13InertiaSwitchStatus 15609;
BA_ "SPN" SG_ 2364700414 Hvesp13StateOfChargeStatus 15610;
BA_ "SPN" SG_ 2364700414 Hvesp13CellBalanceStatus 15611;
BA_ "SPN" SG_ 2364700414 Hvesp13CellBalancingActive 15612;
BA_ "SPN" SG_ 2364700414 Hvesp13InternalChargerStatus 15613;
BA_ "SPN" SG_ 2364700414 Hvsp13HghVltgBsCnntnStts 15614;
BA_ "SPN" SG_ 2364700414 Hvesp13OperationalStatus 15615;
BA_ "SPN" SG_ 2364700414 Hvesp13Status1Counter 15616;
BA_ "SPN" SG_ 2364700414 Hvesp13Status1Crc 15617;
BA_ "SPN" SG_ 2364700670 Hvesp13DischargeEnergyCapacity 15618;
BA_ "SPN" SG_ 2364700670 Hvesp13ChargeEnergyCapacity 15619;
BA_ "SPN" SG_ 2364700670 Hvsp13MxmmChrgVltgLmt 15620;
BA_ "SPN" SG_ 2364700926 Hvesp13Module1OperationalStatus 15621;
BA_ "SPN" SG_ 2364700926 Hvesp13Module2OperationalStatus 15622;
BA_ "SPN" SG_ 2364700926 Hvesp13Module3OperationalStatus 15623;
BA_ "SPN" SG_ 2364700926 Hvesp13Module4OperationalStatus 15624;
BA_ "SPN" SG_ 2364700926 Hvesp13Module5OperationalStatus 15625;
BA_ "SPN" SG_ 2364700926 Hvesp13Module6OperationalStatus 15626;
BA_ "SPN" SG_ 2364700926 Hvesp13Module7OperationalStatus 15627;
BA_ "SPN" SG_ 2364700926 Hvesp13Module8OperationalStatus 15628;
BA_ "SPN" SG_ 2364700926 Hvesp13Module9OperationalStatus 15629;
BA_ "SPN" SG_ 2364700926 Hvsp13Mdl10OprtnlStts 15630;
BA_ "SPN" SG_ 2364700926 Hvsp13Mdl11OprtnlStts 15631;
BA_ "SPN" SG_ 2364700926 Hvsp13Mdl12OprtnlStts 15632;
BA_ "SPN" SG_ 2364700926 Hvsp13Mdl13OprtnlStts 15633;
BA_ "SPN" SG_ 2364700926 Hvsp13Mdl14OprtnlStts 15634;
BA_ "SPN" SG_ 2364700926 Hvsp13Mdl15OprtnlStts 15635;
BA_ "SPN" SG_ 2364700926 Hvsp13Mdl16OprtnlStts 15636;
BA_ "SPN" SG_ 2364700926 Hvsp13Mdl17OprtnlStts 15637;
BA_ "SPN" SG_ 2364700926 Hvsp13Mdl18OprtnlStts 15638;
BA_ "SPN" SG_ 2364700926 Hvsp13Mdl19OprtnlStts 15639;
BA_ "SPN" SG_ 2364700926 Hvsp13Mdl20OprtnlStts 15640;
BA_ "SPN" SG_ 2364700926 Hvsp13Mdl21OprtnlStts 15641;
BA_ "SPN" SG_ 2364700926 Hvsp13Mdl22OprtnlStts 15642;
BA_ "SPN" SG_ 2364700926 Hvsp13Mdl23OprtnlStts 15643;
BA_ "SPN" SG_ 2364700926 Hvsp13Mdl24OprtnlStts 15644;
BA_ "SPN" SG_ 2364700926 Hvsp13Mdl25OprtnlStts 15645;
BA_ "SPN" SG_ 2364700926 Hvsp13Mdl26OprtnlStts 15646;
BA_ "SPN" SG_ 2364700926 Hvsp13Mdl27OprtnlStts 15647;
BA_ "SPN" SG_ 2364700926 Hvsp13Mdl28OprtnlStts 15648;
BA_ "SPN" SG_ 2364700926 Hvsp13Mdl29OprtnlStts 15649;
BA_ "SPN" SG_ 2364700926 Hvsp13Mdl30OprtnlStts 15650;
BA_ "SPN" SG_ 2364700926 Hvsp13Mdl31OprtnlStts 15651;
BA_ "SPN" SG_ 2364700926 Hvsp13Mdl32OprtnlStts 15652;
BA_ "SPN" SG_ 2364701182 Hvsp13ThrmlMngmntSstmSlInptPwr 15653;
BA_ "SPN" SG_ 2364701182 Hvsp13TMtSstHVtIptPw 15654;
BA_ "SPN" SG_ 2364701182 Hvsp13ThrmlMngmntSstmCmprssrSpd 15655;
BA_ "SPN" SG_ 2364701182 Hvsp13ThrmlMngmntSstmRltvHmdt 15656;
BA_ "SPN" SG_ 2364701182 Hvsp13ThrmlMngmntSstmHtrStts 15657;
BA_ "SPN" SG_ 2364701182 Hvsp13ThrmlMngmntSstmHvlStts 15658;
BA_ "SPN" SG_ 2364701182 Hvsp13ThrmlMngmntSstmMd 15659;
BA_ "SPN" SG_ 2364701182 Hvsp13ThrmlMngmntSstmClntLvl 15660;
BA_ "SPN" SG_ 2364701438 Hvsp13HghstCllVltgMdlNmr 15661;
BA_ "SPN" SG_ 2364701438 Hvsp13HghstCllVltgCllNmr 15662;
BA_ "SPN" SG_ 2364701438 Hvsp13LwstCllVltgMdlNmr 15663;
BA_ "SPN" SG_ 2364701438 Hvsp13LwstCllVltgCllNmr 15664;
BA_ "SPN" SG_ 2364701438 Hvesp13AverageCellVoltage 15665;
BA_ "SPN" SG_ 2364701694 Hvsp13HghstCllTmprtrMdlNmr 15666;
BA_ "SPN" SG_ 2364701694 Hvsp13HghstCllTmprtrCllNmr 15667;
BA_ "SPN" SG_ 2364701694 Hvsp13LwstCllTmprtrMdlNmr 15668;
BA_ "SPN" SG_ 2364701694 Hvsp13LwstCllTmprtrCllNmr 15669;
BA_ "SPN" SG_ 2364701694 Hvess13ThermalEventDetected 21300;
BA_ "SPN" SG_ 2364701694 Hvsp13Dt9EmdddIntgrtSpprt 23010;
BA_ "SPN" SG_ 2364701694 Hvesp13Data9Counter 23011;
BA_ "SPN" SG_ 2364701694 Hvesp13Data9Crc 23012;
BA_ "SPN" SG_ 2364701950 Hvsp13HghstCllSttOfChrgMdlNmr 15670;
BA_ "SPN" SG_ 2364701950 Hvsp13HghstCllSttOfChrgCllNmr 15671;
BA_ "SPN" SG_ 2364701950 Hvsp13LwstCllSttOfChrgMdlNmr 15672;
BA_ "SPN" SG_ 2364701950 Hvsp13LwstCllSttOfChrgCllNmr 15673;
BA_ "SPN" SG_ 2364701950 Hvsp13HghVltgBsAtvIsltnTstRslts 15674;
BA_ "SPN" SG_ 2364701950 Hvsp13HVtBsPssvIstTstRsts 15675;
BA_ "SPN" SG_ 2364702206 Hvsp13BsVltgNgtvTChsssGrndVltg 15676;
BA_ "SPN" SG_ 2364702206 Hvsp13VltgLvlNgtvTChsssGrndVltg 15677;
BA_ "SPN" SG_ 2364702206 Hvesp13ActualChargeRate 15678;
BA_ "SPN" SG_ 2364702462 Hvsp14DshrgPwrLmtDTSttOfChrg 15706;
BA_ "SPN" SG_ 2364702462 Hvsp14DshrgPwrLmtDTBttrTmprtr 15707;
BA_ "SPN" SG_ 2364702462 Hvsp14DsPwLtDTBttDstCdt 15708;
BA_ "SPN" SG_ 2364702462 Hvsp14DsPwLtDTBttOCVt 15709;
BA_ "SPN" SG_ 2364702462 Hvsp14DshrgPwrLmtDTBttrCrrnt 15710;
BA_ "SPN" SG_ 2364702462 Hvsp14DshrgPwrLmtDTAnUndfndCs 15711;
BA_ "SPN" SG_ 2364702462 Hvsp14ChrgPwrLmtDTSttOfChrg 15712;
BA_ "SPN" SG_ 2364702462 Hvsp14ChrgPwrLmtDTBttrTmprtr 15713;
BA_ "SPN" SG_ 2364702462 Hvsp14CPwLtDTBttDstCdt 15714;
BA_ "SPN" SG_ 2364702462 Hvsp14ChrgPwrLmtDTBttrOrCllVltg 15715;
BA_ "SPN" SG_ 2364702462 Hvsp14ChrgPwrLmtDTBttrCrrnt 15716;
BA_ "SPN" SG_ 2364702462 Hvsp14ChrgPwrLmtDTAnUndfndCs 15717;
BA_ "SPN" SG_ 2364702718 Hvesp14AvailableDischargePower 15718;
BA_ "SPN" SG_ 2364702718 Hvesp14AvailableChargePower 15719;
BA_ "SPN" SG_ 2364702718 Hvesp14VoltageLevel 15720;
BA_ "SPN" SG_ 2364702718 Hvesp14Current 15721;
BA_ "SPN" SG_ 2364702974 Hvesp14FastUpdateStateOfCharge 15722;
BA_ "SPN" SG_ 2364702974 Hvesp14HighestCellVoltage 15723;
BA_ "SPN" SG_ 2364702974 Hvesp14LowestCellVoltage 15724;
BA_ "SPN" SG_ 2364702974 Hvsp14CllVltgDffrntlStts 15725;
BA_ "SPN" SG_ 2364703230 Hvesp14HighestCellTemperature 15726;
BA_ "SPN" SG_ 2364703230 Hvesp14LowestCellTemperature 15727;
BA_ "SPN" SG_ 2364703230 Hvesp14AverageCellTemperature 15728;
BA_ "SPN" SG_ 2364703230 Hvsp14CllTmprtrDffrntlStts 15729;
BA_ "SPN" SG_ 2364703486 Hvesp14DischargeCapacity 15730;
BA_ "SPN" SG_ 2364703486 Hvesp14ChargeCapacity 15731;
BA_ "SPN" SG_ 2364703486 Hvesp14CellBalancingCount 15732;
BA_ "SPN" SG_ 2364703742 Hvesp14LowestCellStateOfCharge 15735;
BA_ "SPN" SG_ 2364703742 Hvesp14HighestCellStateOfCharge 15736;
BA_ "SPN" SG_ 2364703742 Hvsp14MxmmInstntnsDshrgCrrntLmt 15733;
BA_ "SPN" SG_ 2364703742 Hvsp14MxmmInstntnsChrgCrrntLmt 15734;
BA_ "SPN" SG_ 2364703998 Hvesp14BusVoltage 15737;
BA_ "SPN" SG_ 2364703998 Hvesp14IgnitionVoltage 15738;
BA_ "SPN" SG_ 2364703998 Hvesp14IntakeCoolantTemperature 15739;
BA_ "SPN" SG_ 2364703998 Hvesp14OutletCoolantTemperature 15740;
BA_ "SPN" SG_ 2364703998 Hvesp14ElectronicsTemperature 15741;
BA_ "SPN" SG_ 2364703998 Hvesp14Temperature 15742;
BA_ "SPN" SG_ 2364704254 Hvsp14HghVltgBsPstvCnttrStt 15743;
BA_ "SPN" SG_ 2364704254 Hvsp14HghVltgBsNgtvCnttrStt 15744;
BA_ "SPN" SG_ 2364704254 Hvsp14HghVltgBsDsnntFrwrnng 15745;
BA_ "SPN" SG_ 2364704254 Hvsp14HghVltgBsPrChrgRlStt 15746;
BA_ "SPN" SG_ 2364704254 Hvsp14CntrOfPkCnttrStt 15747;
BA_ "SPN" SG_ 2364704254 Hvsp14HghVltgBsAtvIsltnTstStts 15748;
BA_ "SPN" SG_ 2364704254 Hvsp14HghVltgBsPssvIsltnTstStts 15749;
BA_ "SPN" SG_ 2364704254 Hvesp14HvilStatus 15750;
BA_ "SPN" SG_ 2364704254 Hvesp14InertiaSwitchStatus 15751;
BA_ "SPN" SG_ 2364704254 Hvesp14StateOfChargeStatus 15752;
BA_ "SPN" SG_ 2364704254 Hvesp14CellBalanceStatus 15753;
BA_ "SPN" SG_ 2364704254 Hvesp14CellBalancingActive 15754;
BA_ "SPN" SG_ 2364704254 Hvesp14InternalChargerStatus 15755;
BA_ "SPN" SG_ 2364704254 Hvsp14HghVltgBsCnntnStts 15756;
BA_ "SPN" SG_ 2364704254 Hvesp14OperationalStatus 15757;
BA_ "SPN" SG_ 2364704254 Hvesp14Status1Counter 15758;
BA_ "SPN" SG_ 2364704254 Hvesp14Status1Crc 15759;
BA_ "SPN" SG_ 2364704510 Hvesp14DischargeEnergyCapacity 15760;
BA_ "SPN" SG_ 2364704510 Hvesp14ChargeEnergyCapacity 15761;
BA_ "SPN" SG_ 2364704510 Hvsp14MxmmChrgVltgLmt 15762;
